AUTOSAR XML (schema 4-1-2)
package /Nexteer/NvMProxy_swc/DataTypes
  impl type NvM_BlockIdType: category=VALUE, base-type=NvM_BlockIdType, range raw 1..32767
  impl type NvM_RequestResultType: category=VALUE, base-type=NvM_RequestResultType, compu {0=NVM_REQ_OK, 1=NVM_REQ_NOT_OK, 2=NVM_REQ_PENDING, 3=NVM_REQ_INTEGRITY_FAILED, 4=NVM_REQ_BLOCK_SKIPPED, 5=NVM_REQ_NV_INVALIDATED, 6=NVM_REQ_CANCELED, 7=NVM_REQ_REDUNDANCY_FAILED, 8=NVM_REQ_RESTORED_FROM_ROM}
package /Nexteer/NvMProxy_swc/DataTypes/BaseTypes
  base type NvM_BlockIdType: category=FIXED_LENGTH, base-type-size=16, base-type-encoding=NONE, native-declaration=uint16
  base type NvM_RequestResultType: category=FIXED_LENGTH, base-type-size=8, base-type-encoding=NONE, native-declaration=uint8
package /Nexteer/NvMProxy_swc/Interfaces
  5 x client server interface, all with is-service=true:
    NvMAdministration
      operation SetBlockProtection: possible-error=NvMAdministration/E_NOT_OK
        arg ProtectionEnabled_Arg: type=boolean, direction=IN
      error E_NOT_OK: error-code=1
    NvMService_AC3_SRBS
      6 x operation, all with possible-error=NvMService_AC3_SRBS/E_NOT_OK:
        EraseBlock
        GetErrorStatus
          arg ErrorStatus_Arg: type=NvM_RequestResultType, direction=OUT
        InvalidateNvBlock
        ReadBlock
          arg DstPtr_Arg: type=dtRef_VOID, direction=IN
        SetRamBlockStatus
          arg RamBlockStatus_Arg: type=boolean, direction=IN
        WriteBlock
          arg SrcPtr_Arg: type=dtRef_const_VOID, direction=IN
      error E_NOT_OK: error-code=1
    NvMService_AC3_SRBS_Defs
      7 x operation, all with possible-error=NvMService_AC3_SRBS_Defs/E_NOT_OK:
        EraseBlock
        GetErrorStatus
          arg ErrorStatus_Arg: type=NvM_RequestResultType, direction=OUT
        InvalidateNvBlock
        ReadBlock
          arg DstPtr_Arg: type=dtRef_VOID, direction=IN
        RestoreBlockDefaults
          arg DstPtr_Arg: type=dtRef_VOID, direction=IN
        SetRamBlockStatus
          arg RamBlockStatus_Arg: type=boolean, direction=IN
        WriteBlock
          arg SrcPtr_Arg: type=dtRef_const_VOID, direction=IN
      error E_NOT_OK: error-code=1
    NvMService_AC3_SRBS_DS
      8 x operation, all with possible-error=NvMService_AC3_SRBS_DS/E_NOT_OK:
        EraseBlock
        GetDataIndex
          arg DataIndex_Arg: type=uint8, direction=OUT
        GetErrorStatus
          arg ErrorStatus_Arg: type=NvM_RequestResultType, direction=OUT
        InvalidateNvBlock
        ReadBlock
          arg DstPtr_Arg: type=dtRef_VOID, direction=IN
        SetDataIndex
          arg DataIndex_Arg: type=uint8, direction=IN
        SetRamBlockStatus
          arg RamBlockStatus_Arg: type=boolean, direction=IN
        WriteBlock
          arg SrcPtr_Arg: type=dtRef_const_VOID, direction=IN
      error E_NOT_OK: error-code=1
    NvMService_AC3_SRBS_DS_Defs
      9 x operation, all with possible-error=NvMService_AC3_SRBS_DS_Defs/E_NOT_OK:
        EraseBlock
        GetDataIndex
          arg DataIndex_Arg: type=uint8, direction=OUT
        GetErrorStatus
          arg ErrorStatus_Arg: type=NvM_RequestResultType, direction=OUT
        InvalidateNvBlock
        ReadBlock
          arg DstPtr_Arg: type=dtRef_VOID, direction=IN
        RestoreBlockDefaults
          arg DstPtr_Arg: type=dtRef_VOID, direction=IN
        SetDataIndex
          arg DataIndex_Arg: type=uint8, direction=IN
        SetRamBlockStatus
          arg RamBlockStatus_Arg: type=boolean, direction=IN
        WriteBlock
          arg SrcPtr_Arg: type=dtRef_const_VOID, direction=IN
      error E_NOT_OK: error-code=1
package /Nexteer/NvMProxy_swc/ComponentTypes
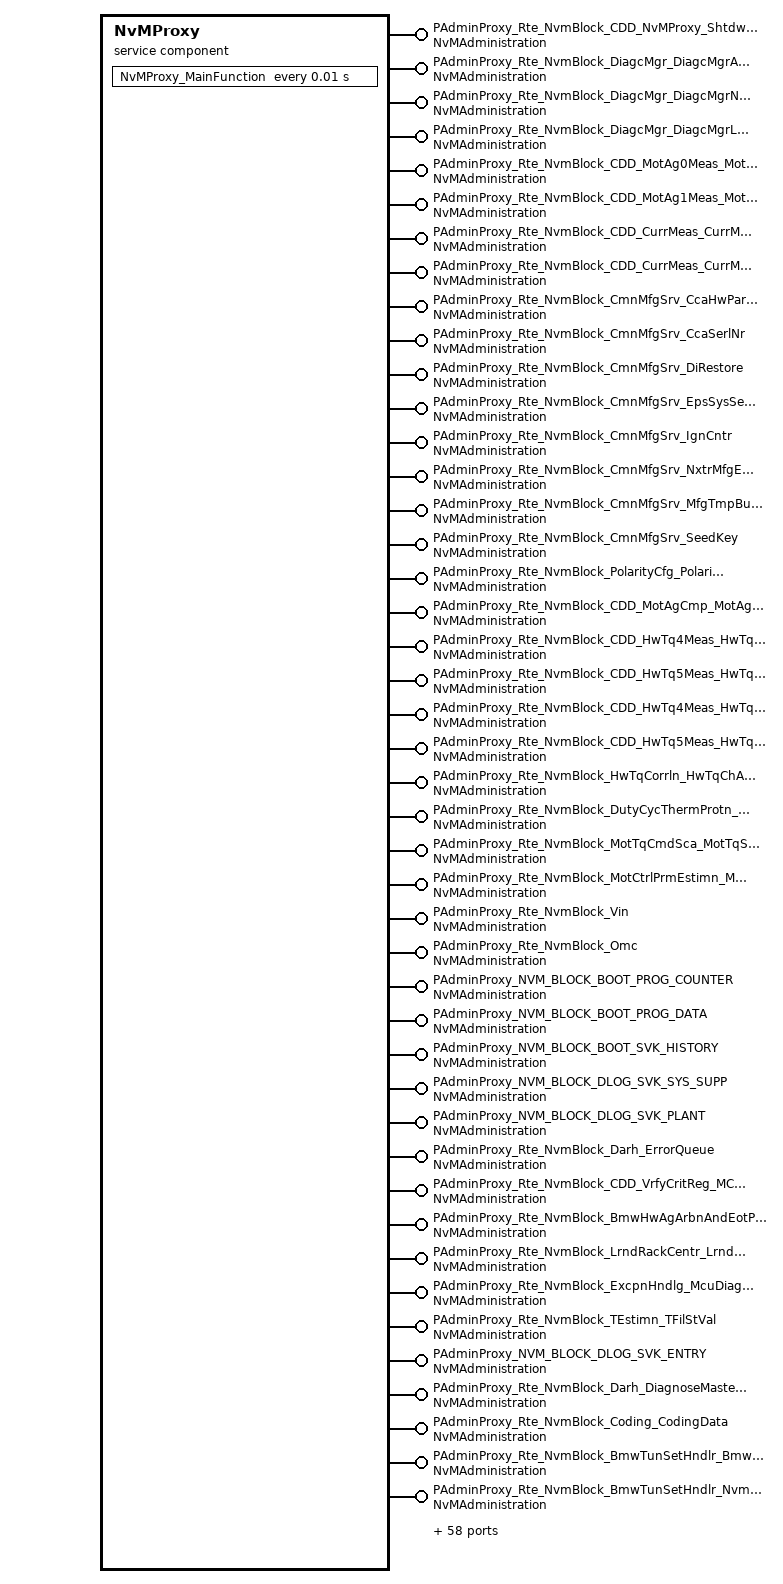
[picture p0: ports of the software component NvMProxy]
  service sw component type NvMProxy
    106 x provide port:
      PAdminProxy_Rte_NvmBlock_CDD_NvMProxy_ShtdwnClsChk: server-com-spec{operation=SetBlockProtection, queue-length=1}, provided-interface=NvMAdministration
      PAdminProxy_Rte_NvmBlock_DiagcMgr_DiagcMgrApplCrc: server-com-spec{operation=SetBlockProtection, queue-length=1}, provided-interface=NvMAdministration
      PAdminProxy_Rte_NvmBlock_DiagcMgr_DiagcMgrNtcFltAry: server-com-spec{operation=SetBlockProtection, queue-length=1}, provided-interface=NvMAdministration
      PAdminProxy_Rte_NvmBlock_DiagcMgr_DiagcMgrLtchCntrAry: server-com-spec{operation=SetBlockProtection, queue-length=1}, provided-interface=NvMAdministration
      PAdminProxy_Rte_NvmBlock_CDD_MotAg0Meas_MotAg0CoeffTbl: server-com-spec{operation=SetBlockProtection, queue-length=1}, provided-interface=NvMAdministration
      PAdminProxy_Rte_NvmBlock_CDD_MotAg1Meas_MotAg1CoeffTbl: server-com-spec{operation=SetBlockProtection, queue-length=1}, provided-interface=NvMAdministration
      PAdminProxy_Rte_NvmBlock_CDD_CurrMeas_CurrMeasEolGainCalSetABC: server-com-spec{operation=SetBlockProtection, queue-length=1}, provided-interface=NvMAdministration
      PAdminProxy_Rte_NvmBlock_CDD_CurrMeas_CurrMeasEolOffsCalSetABC: server-com-spec{operation=SetBlockProtection, queue-length=1}, provided-interface=NvMAdministration
      PAdminProxy_Rte_NvmBlock_CmnMfgSrv_CcaHwPartNr: server-com-spec{operation=SetBlockProtection, queue-length=1}, provided-interface=NvMAdministration
      PAdminProxy_Rte_NvmBlock_CmnMfgSrv_CcaSerlNr: server-com-spec{operation=SetBlockProtection, queue-length=1}, provided-interface=NvMAdministration
      PAdminProxy_Rte_NvmBlock_CmnMfgSrv_DiRestore: server-com-spec{operation=SetBlockProtection, queue-length=1}, provided-interface=NvMAdministration
      PAdminProxy_Rte_NvmBlock_CmnMfgSrv_EpsSysSerlNr: server-com-spec{operation=SetBlockProtection, queue-length=1}, provided-interface=NvMAdministration
      PAdminProxy_Rte_NvmBlock_CmnMfgSrv_IgnCntr: server-com-spec{operation=SetBlockProtection, queue-length=1}, provided-interface=NvMAdministration
      PAdminProxy_Rte_NvmBlock_CmnMfgSrv_NxtrMfgEnaCntr: server-com-spec{operation=SetBlockProtection, queue-length=1}, provided-interface=NvMAdministration
      PAdminProxy_Rte_NvmBlock_CmnMfgSrv_MfgTmpBuf{0..4}: server-com-spec{operation=SetBlockProtection, queue-length=1}, provided-interface=NvMAdministration
      PAdminProxy_Rte_NvmBlock_CmnMfgSrv_SeedKey: server-com-spec{operation=SetBlockProtection, queue-length=1}, provided-interface=NvMAdministration
      PAdminProxy_Rte_NvmBlock_PolarityCfg_PolarityCfgSaved: server-com-spec{operation=SetBlockProtection, queue-length=1}, provided-interface=NvMAdministration
      PAdminProxy_Rte_NvmBlock_CDD_MotAgCmp_MotAgCmpMotAgBackEmf: server-com-spec{operation=SetBlockProtection, queue-length=1}, provided-interface=NvMAdministration
      PAdminProxy_Rte_NvmBlock_CDD_HwTq4Meas_HwTq4Offs_MirrorBlock: server-com-spec{operation=SetBlockProtection, queue-length=1}, provided-interface=NvMAdministration
      PAdminProxy_Rte_NvmBlock_CDD_HwTq5Meas_HwTq5Offs_MirrorBlock: server-com-spec{operation=SetBlockProtection, queue-length=1}, provided-interface=NvMAdministration
      PAdminProxy_Rte_NvmBlock_CDD_HwTq4Meas_HwTq4Sca_MirrorBlock: server-com-spec{operation=SetBlockProtection, queue-length=1}, provided-interface=NvMAdministration
      PAdminProxy_Rte_NvmBlock_CDD_HwTq5Meas_HwTq5Sca_MirrorBlock: server-com-spec{operation=SetBlockProtection, queue-length=1}, provided-interface=NvMAdministration
      PAdminProxy_Rte_NvmBlock_HwTqCorrln_HwTqChACmnModCmpLpFilSt: server-com-spec{operation=SetBlockProtection, queue-length=1}, provided-interface=NvMAdministration
      PAdminProxy_Rte_NvmBlock_DutyCycThermProtn_FilStVal: server-com-spec{operation=SetBlockProtection, queue-length=1}, provided-interface=NvMAdministration
      PAdminProxy_Rte_NvmBlock_MotTqCmdSca_MotTqScaFac: server-com-spec{operation=SetBlockProtection, queue-length=1}, provided-interface=NvMAdministration
      PAdminProxy_Rte_NvmBlock_MotCtrlPrmEstimn_MotPrmNom: server-com-spec{operation=SetBlockProtection, queue-length=1}, provided-interface=NvMAdministration
      PAdminProxy_Rte_NvmBlock_Vin: server-com-spec{operation=SetBlockProtection, queue-length=1}, provided-interface=NvMAdministration
      PAdminProxy_Rte_NvmBlock_Omc: server-com-spec{operation=SetBlockProtection, queue-length=1}, provided-interface=NvMAdministration
      PAdminProxy_NVM_BLOCK_BOOT_PROG_COUNTER: server-com-spec{operation=SetBlockProtection, queue-length=1}, provided-interface=NvMAdministration
      PAdminProxy_NVM_BLOCK_BOOT_PROG_DATA: server-com-spec{operation=SetBlockProtection, queue-length=1}, provided-interface=NvMAdministration
      PAdminProxy_NVM_BLOCK_BOOT_SVK_HISTORY: server-com-spec{operation=SetBlockProtection, queue-length=1}, provided-interface=NvMAdministration
      PAdminProxy_NVM_BLOCK_DLOG_SVK_SYS_SUPP: server-com-spec{operation=SetBlockProtection, queue-length=1}, provided-interface=NvMAdministration
      PAdminProxy_NVM_BLOCK_DLOG_SVK_PLANT: server-com-spec{operation=SetBlockProtection, queue-length=1}, provided-interface=NvMAdministration
      PAdminProxy_Rte_NvmBlock_Darh_ErrorQueue: server-com-spec{operation=SetBlockProtection, queue-length=1}, provided-interface=NvMAdministration
      PAdminProxy_Rte_NvmBlock_CDD_VrfyCritReg_MCalReadVrfyCritRegFltInfo: server-com-spec{operation=SetBlockProtection, queue-length=1}, provided-interface=NvMAdministration
      PAdminProxy_Rte_NvmBlock_BmwHwAgArbnAndEotPosn_BmwVehCentrOffs: server-com-spec{operation=SetBlockProtection, queue-length=1}, provided-interface=NvMAdministration
      PAdminProxy_Rte_NvmBlock_LrndRackCentr_LrndRackCentr: server-com-spec{operation=SetBlockProtection, queue-length=1}, provided-interface=NvMAdministration
      PAdminProxy_Rte_NvmBlock_ExcpnHndlg_McuDiagcData: server-com-spec{operation=SetBlockProtection, queue-length=1}, provided-interface=NvMAdministration
      PAdminProxy_Rte_NvmBlock_TEstimn_TFilStVal: server-com-spec{operation=SetBlockProtection, queue-length=1}, provided-interface=NvMAdministration
      PAdminProxy_NVM_BLOCK_DLOG_SVK_ENTRY: server-com-spec{operation=SetBlockProtection, queue-length=1}, provided-interface=NvMAdministration
      PAdminProxy_Rte_NvmBlock_Darh_DiagnoseMasterEnable: server-com-spec{operation=SetBlockProtection, queue-length=1}, provided-interface=NvMAdministration
      PAdminProxy_Rte_NvmBlock_Coding_CodingData: server-com-spec{operation=SetBlockProtection, queue-length=1}, provided-interface=NvMAdministration
      PAdminProxy_Rte_NvmBlock_BmwTunSetHndlr_BmwDesIninIdx: server-com-spec{operation=SetBlockProtection, queue-length=1}, provided-interface=NvMAdministration
      PAdminProxy_Rte_NvmBlock_BmwTunSetHndlr_NvmBmwDesIninOptSetAIdx: server-com-spec{operation=SetBlockProtection, queue-length=1}, provided-interface=NvMAdministration
      PAdminProxy_Rte_NvmBlock_BmwDiagcSrvHndlg_MilesKmEeprom: server-com-spec{operation=SetBlockProtection, queue-length=1}, provided-interface=NvMAdministration
      PAdminProxy_Rte_NvmBlock_BmwDiagcSrvHndlg_ProgCntr: server-com-spec{operation=SetBlockProtection, queue-length=1}, provided-interface=NvMAdministration
      PAdminProxy_Rte_NvmBlock_BmwDiagcSrvHndlg_ProgCntrMaxVal: server-com-spec{operation=SetBlockProtection, queue-length=1}, provided-interface=NvMAdministration
      PAdminProxy_Rte_NvmBlock_BmwDiagcSrvHndlg_TestStamp: server-com-spec{operation=SetBlockProtection, queue-length=1}, provided-interface=NvMAdministration
      PAdminProxy_Rte_NvmBlock_PullCmpActv_PullCmpLongTerm: server-com-spec{operation=SetBlockProtection, queue-length=1}, provided-interface=NvMAdministration
      PSProxy_Rte_NvmBlock_DiagcMgr_DiagcMgrApplCrc: provided-interface=NvMService_AC3_SRBS_Defs
        provided-com-specs:
          operation=NvMService_AC3_SRBS_Defs/EraseBlock, queue-length=1
          operation=NvMService_AC3_SRBS_Defs/GetErrorStatus, queue-length=1
          operation=NvMService_AC3_SRBS_Defs/InvalidateNvBlock, queue-length=1
          operation=NvMService_AC3_SRBS_Defs/ReadBlock, queue-length=1
          operation=NvMService_AC3_SRBS_Defs/RestoreBlockDefaults, queue-length=1
          operation=NvMService_AC3_SRBS_Defs/SetRamBlockStatus, queue-length=1
          operation=NvMService_AC3_SRBS_Defs/WriteBlock, queue-length=1
      PSProxy_Rte_NvmBlock_CDD_CurrMeas_CurrMeasEolGainCalSetABC: provided-interface=NvMService_AC3_SRBS_Defs
        provided-com-specs:
          operation=NvMService_AC3_SRBS_Defs/EraseBlock, queue-length=1
          operation=NvMService_AC3_SRBS_Defs/GetErrorStatus, queue-length=1
          operation=NvMService_AC3_SRBS_Defs/InvalidateNvBlock, queue-length=1
          operation=NvMService_AC3_SRBS_Defs/ReadBlock, queue-length=1
          operation=NvMService_AC3_SRBS_Defs/RestoreBlockDefaults, queue-length=1
          operation=NvMService_AC3_SRBS_Defs/SetRamBlockStatus, queue-length=1
          operation=NvMService_AC3_SRBS_Defs/WriteBlock, queue-length=1
      PSProxy_Rte_NvmBlock_CDD_CurrMeas_CurrMeasEolOffsCalSetABC: provided-interface=NvMService_AC3_SRBS_Defs
        provided-com-specs:
          operation=NvMService_AC3_SRBS_Defs/EraseBlock, queue-length=1
          operation=NvMService_AC3_SRBS_Defs/GetErrorStatus, queue-length=1
          operation=NvMService_AC3_SRBS_Defs/InvalidateNvBlock, queue-length=1
          operation=NvMService_AC3_SRBS_Defs/ReadBlock, queue-length=1
          operation=NvMService_AC3_SRBS_Defs/RestoreBlockDefaults, queue-length=1
          operation=NvMService_AC3_SRBS_Defs/SetRamBlockStatus, queue-length=1
          operation=NvMService_AC3_SRBS_Defs/WriteBlock, queue-length=1
      PSProxy_Rte_NvmBlock_CmnMfgSrv_IgnCntr: provided-interface=NvMService_AC3_SRBS_Defs
        provided-com-specs:
          operation=NvMService_AC3_SRBS_Defs/EraseBlock, queue-length=1
          operation=NvMService_AC3_SRBS_Defs/GetErrorStatus, queue-length=1
          operation=NvMService_AC3_SRBS_Defs/InvalidateNvBlock, queue-length=1
          operation=NvMService_AC3_SRBS_Defs/ReadBlock, queue-length=1
          operation=NvMService_AC3_SRBS_Defs/RestoreBlockDefaults, queue-length=1
          operation=NvMService_AC3_SRBS_Defs/SetRamBlockStatus, queue-length=1
          operation=NvMService_AC3_SRBS_Defs/WriteBlock, queue-length=1
      PSProxy_Rte_NvmBlock_CmnMfgSrv_NxtrMfgEnaCntr: provided-interface=NvMService_AC3_SRBS_Defs
        provided-com-specs:
          operation=NvMService_AC3_SRBS_Defs/EraseBlock, queue-length=1
          operation=NvMService_AC3_SRBS_Defs/GetErrorStatus, queue-length=1
          operation=NvMService_AC3_SRBS_Defs/InvalidateNvBlock, queue-length=1
          operation=NvMService_AC3_SRBS_Defs/ReadBlock, queue-length=1
          operation=NvMService_AC3_SRBS_Defs/RestoreBlockDefaults, queue-length=1
          operation=NvMService_AC3_SRBS_Defs/SetRamBlockStatus, queue-length=1
          operation=NvMService_AC3_SRBS_Defs/WriteBlock, queue-length=1
      PSProxy_Rte_NvmBlock_CmnMfgSrv_SeedKey: provided-interface=NvMService_AC3_SRBS_Defs
        provided-com-specs:
          operation=NvMService_AC3_SRBS_Defs/EraseBlock, queue-length=1
          operation=NvMService_AC3_SRBS_Defs/GetErrorStatus, queue-length=1
          operation=NvMService_AC3_SRBS_Defs/InvalidateNvBlock, queue-length=1
          operation=NvMService_AC3_SRBS_Defs/ReadBlock, queue-length=1
          operation=NvMService_AC3_SRBS_Defs/RestoreBlockDefaults, queue-length=1
          operation=NvMService_AC3_SRBS_Defs/SetRamBlockStatus, queue-length=1
          operation=NvMService_AC3_SRBS_Defs/WriteBlock, queue-length=1
      PSProxy_Rte_NvmBlock_PolarityCfg_PolarityCfgSaved: provided-interface=NvMService_AC3_SRBS_Defs
        provided-com-specs:
          operation=NvMService_AC3_SRBS_Defs/EraseBlock, queue-length=1
          operation=NvMService_AC3_SRBS_Defs/GetErrorStatus, queue-length=1
          operation=NvMService_AC3_SRBS_Defs/InvalidateNvBlock, queue-length=1
          operation=NvMService_AC3_SRBS_Defs/ReadBlock, queue-length=1
          operation=NvMService_AC3_SRBS_Defs/RestoreBlockDefaults, queue-length=1
          operation=NvMService_AC3_SRBS_Defs/SetRamBlockStatus, queue-length=1
          operation=NvMService_AC3_SRBS_Defs/WriteBlock, queue-length=1
      PSProxy_Rte_NvmBlock_CDD_MotAgCmp_MotAgCmpMotAgBackEmf: provided-interface=NvMService_AC3_SRBS_Defs
        provided-com-specs:
          operation=NvMService_AC3_SRBS_Defs/EraseBlock, queue-length=1
          operation=NvMService_AC3_SRBS_Defs/GetErrorStatus, queue-length=1
          operation=NvMService_AC3_SRBS_Defs/InvalidateNvBlock, queue-length=1
          operation=NvMService_AC3_SRBS_Defs/ReadBlock, queue-length=1
          operation=NvMService_AC3_SRBS_Defs/RestoreBlockDefaults, queue-length=1
          operation=NvMService_AC3_SRBS_Defs/SetRamBlockStatus, queue-length=1
          operation=NvMService_AC3_SRBS_Defs/WriteBlock, queue-length=1
      PSProxy_Rte_NvmBlock_HwTqCorrln_HwTqChACmnModCmpLpFilSt: provided-interface=NvMService_AC3_SRBS_Defs
        provided-com-specs:
          operation=NvMService_AC3_SRBS_Defs/EraseBlock, queue-length=1
          operation=NvMService_AC3_SRBS_Defs/GetErrorStatus, queue-length=1
          operation=NvMService_AC3_SRBS_Defs/InvalidateNvBlock, queue-length=1
          operation=NvMService_AC3_SRBS_Defs/ReadBlock, queue-length=1
          operation=NvMService_AC3_SRBS_Defs/RestoreBlockDefaults, queue-length=1
          operation=NvMService_AC3_SRBS_Defs/SetRamBlockStatus, queue-length=1
          operation=NvMService_AC3_SRBS_Defs/WriteBlock, queue-length=1
      PSProxy_Rte_NvmBlock_Vin: provided-interface=NvMService_AC3_SRBS_Defs
        provided-com-specs:
          operation=NvMService_AC3_SRBS_Defs/EraseBlock, queue-length=1
          operation=NvMService_AC3_SRBS_Defs/GetErrorStatus, queue-length=1
          operation=NvMService_AC3_SRBS_Defs/InvalidateNvBlock, queue-length=1
          operation=NvMService_AC3_SRBS_Defs/ReadBlock, queue-length=1
          operation=NvMService_AC3_SRBS_Defs/RestoreBlockDefaults, queue-length=1
          operation=NvMService_AC3_SRBS_Defs/SetRamBlockStatus, queue-length=1
          operation=NvMService_AC3_SRBS_Defs/WriteBlock, queue-length=1
      PSProxy_Rte_NvmBlock_Omc: provided-interface=NvMService_AC3_SRBS_Defs
        provided-com-specs:
          operation=NvMService_AC3_SRBS_Defs/EraseBlock, queue-length=1
          operation=NvMService_AC3_SRBS_Defs/GetErrorStatus, queue-length=1
          operation=NvMService_AC3_SRBS_Defs/InvalidateNvBlock, queue-length=1
          operation=NvMService_AC3_SRBS_Defs/ReadBlock, queue-length=1
          operation=NvMService_AC3_SRBS_Defs/RestoreBlockDefaults, queue-length=1
          operation=NvMService_AC3_SRBS_Defs/SetRamBlockStatus, queue-length=1
          operation=NvMService_AC3_SRBS_Defs/WriteBlock, queue-length=1
      PSProxy_Rte_NvmBlock_Darh_ErrorQueue: provided-interface=NvMService_AC3_SRBS_Defs
        provided-com-specs:
          operation=NvMService_AC3_SRBS_Defs/EraseBlock, queue-length=1
          operation=NvMService_AC3_SRBS_Defs/GetErrorStatus, queue-length=1
          operation=NvMService_AC3_SRBS_Defs/InvalidateNvBlock, queue-length=1
          operation=NvMService_AC3_SRBS_Defs/ReadBlock, queue-length=1
          operation=NvMService_AC3_SRBS_Defs/RestoreBlockDefaults, queue-length=1
          operation=NvMService_AC3_SRBS_Defs/SetRamBlockStatus, queue-length=1
          operation=NvMService_AC3_SRBS_Defs/WriteBlock, queue-length=1
      PSProxy_Rte_NvmBlock_ExcpnHndlg_McuDiagcData: provided-interface=NvMService_AC3_SRBS_Defs
        provided-com-specs:
          operation=NvMService_AC3_SRBS_Defs/EraseBlock, queue-length=1
          operation=NvMService_AC3_SRBS_Defs/GetErrorStatus, queue-length=1
          operation=NvMService_AC3_SRBS_Defs/InvalidateNvBlock, queue-length=1
          operation=NvMService_AC3_SRBS_Defs/ReadBlock, queue-length=1
          operation=NvMService_AC3_SRBS_Defs/RestoreBlockDefaults, queue-length=1
          operation=NvMService_AC3_SRBS_Defs/SetRamBlockStatus, queue-length=1
          operation=NvMService_AC3_SRBS_Defs/WriteBlock, queue-length=1
      PSProxy_Rte_NvmBlock_Coding_CodingData: provided-interface=NvMService_AC3_SRBS_Defs
        provided-com-specs:
          operation=NvMService_AC3_SRBS_Defs/EraseBlock, queue-length=1
          operation=NvMService_AC3_SRBS_Defs/GetErrorStatus, queue-length=1
          operation=NvMService_AC3_SRBS_Defs/InvalidateNvBlock, queue-length=1
          operation=NvMService_AC3_SRBS_Defs/ReadBlock, queue-length=1
          operation=NvMService_AC3_SRBS_Defs/RestoreBlockDefaults, queue-length=1
          operation=NvMService_AC3_SRBS_Defs/SetRamBlockStatus, queue-length=1
          operation=NvMService_AC3_SRBS_Defs/WriteBlock, queue-length=1
      PSProxy_Rte_NvmBlock_BmwTunSetHndlr_BmwDesIninIdx: provided-interface=NvMService_AC3_SRBS_Defs
        provided-com-specs:
          operation=NvMService_AC3_SRBS_Defs/EraseBlock, queue-length=1
          operation=NvMService_AC3_SRBS_Defs/GetErrorStatus, queue-length=1
          operation=NvMService_AC3_SRBS_Defs/InvalidateNvBlock, queue-length=1
          operation=NvMService_AC3_SRBS_Defs/ReadBlock, queue-length=1
          operation=NvMService_AC3_SRBS_Defs/RestoreBlockDefaults, queue-length=1
          operation=NvMService_AC3_SRBS_Defs/SetRamBlockStatus, queue-length=1
          operation=NvMService_AC3_SRBS_Defs/WriteBlock, queue-length=1
      PSProxy_Rte_NvmBlock_BmwTunSetHndlr_NvmBmwDesIninOptSetAIdx: provided-interface=NvMService_AC3_SRBS_Defs
        provided-com-specs:
          operation=NvMService_AC3_SRBS_Defs/EraseBlock, queue-length=1
          operation=NvMService_AC3_SRBS_Defs/GetErrorStatus, queue-length=1
          operation=NvMService_AC3_SRBS_Defs/InvalidateNvBlock, queue-length=1
          operation=NvMService_AC3_SRBS_Defs/ReadBlock, queue-length=1
          operation=NvMService_AC3_SRBS_Defs/RestoreBlockDefaults, queue-length=1
          operation=NvMService_AC3_SRBS_Defs/SetRamBlockStatus, queue-length=1
          operation=NvMService_AC3_SRBS_Defs/WriteBlock, queue-length=1
      PSProxy_Rte_NvmBlock_BmwDiagcSrvHndlg_ProgCntrMaxVal: provided-interface=NvMService_AC3_SRBS_Defs
        provided-com-specs:
          operation=NvMService_AC3_SRBS_Defs/EraseBlock, queue-length=1
          operation=NvMService_AC3_SRBS_Defs/GetErrorStatus, queue-length=1
          operation=NvMService_AC3_SRBS_Defs/InvalidateNvBlock, queue-length=1
          operation=NvMService_AC3_SRBS_Defs/ReadBlock, queue-length=1
          operation=NvMService_AC3_SRBS_Defs/RestoreBlockDefaults, queue-length=1
          operation=NvMService_AC3_SRBS_Defs/SetRamBlockStatus, queue-length=1
          operation=NvMService_AC3_SRBS_Defs/WriteBlock, queue-length=1
      PSProxy_Rte_NvmBlock_PullCmpActv_PullCmpLongTerm: provided-interface=NvMService_AC3_SRBS_Defs
        provided-com-specs:
          operation=NvMService_AC3_SRBS_Defs/EraseBlock, queue-length=1
          operation=NvMService_AC3_SRBS_Defs/GetErrorStatus, queue-length=1
          operation=NvMService_AC3_SRBS_Defs/InvalidateNvBlock, queue-length=1
          operation=NvMService_AC3_SRBS_Defs/ReadBlock, queue-length=1
          operation=NvMService_AC3_SRBS_Defs/RestoreBlockDefaults, queue-length=1
          operation=NvMService_AC3_SRBS_Defs/SetRamBlockStatus, queue-length=1
          operation=NvMService_AC3_SRBS_Defs/WriteBlock, queue-length=1
      PSProxy_NVM_BLOCK_DLOG_SVK_ENTRY: provided-interface=NvMService_AC3_SRBS_DS
        provided-com-specs:
          operation=NvMService_AC3_SRBS_DS/EraseBlock, queue-length=1
          operation=NvMService_AC3_SRBS_DS/GetDataIndex, queue-length=1
          operation=NvMService_AC3_SRBS_DS/GetErrorStatus, queue-length=1
          operation=NvMService_AC3_SRBS_DS/InvalidateNvBlock, queue-length=1
          operation=NvMService_AC3_SRBS_DS/ReadBlock, queue-length=1
          operation=NvMService_AC3_SRBS_DS/SetDataIndex, queue-length=1
          operation=NvMService_AC3_SRBS_DS/SetRamBlockStatus, queue-length=1
          operation=NvMService_AC3_SRBS_DS/WriteBlock, queue-length=1
      PSProxy_Rte_NvmBlock_CDD_NvMProxy_ShtdwnClsChk: provided-interface=NvMService_AC3_SRBS
        provided-com-specs:
          operation=NvMService_AC3_SRBS/EraseBlock, queue-length=1
          operation=NvMService_AC3_SRBS/GetErrorStatus, queue-length=1
          operation=NvMService_AC3_SRBS/InvalidateNvBlock, queue-length=1
          operation=NvMService_AC3_SRBS/ReadBlock, queue-length=1
          operation=NvMService_AC3_SRBS/SetRamBlockStatus, queue-length=1
          operation=NvMService_AC3_SRBS/WriteBlock, queue-length=1
      PSProxy_Rte_NvmBlock_DiagcMgr_DiagcMgrNtcFltAry: provided-interface=NvMService_AC3_SRBS
        provided-com-specs:
          operation=NvMService_AC3_SRBS/EraseBlock, queue-length=1
          operation=NvMService_AC3_SRBS/GetErrorStatus, queue-length=1
          operation=NvMService_AC3_SRBS/InvalidateNvBlock, queue-length=1
          operation=NvMService_AC3_SRBS/ReadBlock, queue-length=1
          operation=NvMService_AC3_SRBS/SetRamBlockStatus, queue-length=1
          operation=NvMService_AC3_SRBS/WriteBlock, queue-length=1
      PSProxy_Rte_NvmBlock_DiagcMgr_DiagcMgrLtchCntrAry: provided-interface=NvMService_AC3_SRBS
        provided-com-specs:
          operation=NvMService_AC3_SRBS/EraseBlock, queue-length=1
          operation=NvMService_AC3_SRBS/GetErrorStatus, queue-length=1
          operation=NvMService_AC3_SRBS/InvalidateNvBlock, queue-length=1
          operation=NvMService_AC3_SRBS/ReadBlock, queue-length=1
          operation=NvMService_AC3_SRBS/SetRamBlockStatus, queue-length=1
          operation=NvMService_AC3_SRBS/WriteBlock, queue-length=1
      PSProxy_Rte_NvmBlock_CDD_MotAg0Meas_MotAg0CoeffTbl: provided-interface=NvMService_AC3_SRBS
        provided-com-specs:
          operation=NvMService_AC3_SRBS/EraseBlock, queue-length=1
          operation=NvMService_AC3_SRBS/GetErrorStatus, queue-length=1
          operation=NvMService_AC3_SRBS/InvalidateNvBlock, queue-length=1
          operation=NvMService_AC3_SRBS/ReadBlock, queue-length=1
          operation=NvMService_AC3_SRBS/SetRamBlockStatus, queue-length=1
          operation=NvMService_AC3_SRBS/WriteBlock, queue-length=1
      PSProxy_Rte_NvmBlock_CDD_MotAg1Meas_MotAg1CoeffTbl: provided-interface=NvMService_AC3_SRBS
        provided-com-specs:
          operation=NvMService_AC3_SRBS/EraseBlock, queue-length=1
          operation=NvMService_AC3_SRBS/GetErrorStatus, queue-length=1
          operation=NvMService_AC3_SRBS/InvalidateNvBlock, queue-length=1
          operation=NvMService_AC3_SRBS/ReadBlock, queue-length=1
          operation=NvMService_AC3_SRBS/SetRamBlockStatus, queue-length=1
          operation=NvMService_AC3_SRBS/WriteBlock, queue-length=1
      PSProxy_Rte_NvmBlock_CmnMfgSrv_CcaHwPartNr: provided-interface=NvMService_AC3_SRBS
        provided-com-specs:
          operation=NvMService_AC3_SRBS/EraseBlock, queue-length=1
          operation=NvMService_AC3_SRBS/GetErrorStatus, queue-length=1
          operation=NvMService_AC3_SRBS/InvalidateNvBlock, queue-length=1
          operation=NvMService_AC3_SRBS/ReadBlock, queue-length=1
          operation=NvMService_AC3_SRBS/SetRamBlockStatus, queue-length=1
          operation=NvMService_AC3_SRBS/WriteBlock, queue-length=1
      PSProxy_Rte_NvmBlock_CmnMfgSrv_CcaSerlNr: provided-interface=NvMService_AC3_SRBS
        provided-com-specs:
          operation=NvMService_AC3_SRBS/EraseBlock, queue-length=1
          operation=NvMService_AC3_SRBS/GetErrorStatus, queue-length=1
          operation=NvMService_AC3_SRBS/InvalidateNvBlock, queue-length=1
          operation=NvMService_AC3_SRBS/ReadBlock, queue-length=1
          operation=NvMService_AC3_SRBS/SetRamBlockStatus, queue-length=1
          operation=NvMService_AC3_SRBS/WriteBlock, queue-length=1
      PSProxy_Rte_NvmBlock_CmnMfgSrv_DiRestore: provided-interface=NvMService_AC3_SRBS
        provided-com-specs:
          operation=NvMService_AC3_SRBS/EraseBlock, queue-length=1
          operation=NvMService_AC3_SRBS/GetErrorStatus, queue-length=1
          operation=NvMService_AC3_SRBS/InvalidateNvBlock, queue-length=1
          operation=NvMService_AC3_SRBS/ReadBlock, queue-length=1
          operation=NvMService_AC3_SRBS/SetRamBlockStatus, queue-length=1
          operation=NvMService_AC3_SRBS/WriteBlock, queue-length=1
      PSProxy_Rte_NvmBlock_CmnMfgSrv_EpsSysSerlNr: provided-interface=NvMService_AC3_SRBS
        provided-com-specs:
          operation=NvMService_AC3_SRBS/EraseBlock, queue-length=1
          operation=NvMService_AC3_SRBS/GetErrorStatus, queue-length=1
          operation=NvMService_AC3_SRBS/InvalidateNvBlock, queue-length=1
          operation=NvMService_AC3_SRBS/ReadBlock, queue-length=1
          operation=NvMService_AC3_SRBS/SetRamBlockStatus, queue-length=1
          operation=NvMService_AC3_SRBS/WriteBlock, queue-length=1
      PSProxy_Rte_NvmBlock_CmnMfgSrv_MfgTmpBuf0: provided-interface=NvMService_AC3_SRBS
        provided-com-specs:
          operation=NvMService_AC3_SRBS/EraseBlock, queue-length=1
          operation=NvMService_AC3_SRBS/GetErrorStatus, queue-length=1
          operation=NvMService_AC3_SRBS/InvalidateNvBlock, queue-length=1
          operation=NvMService_AC3_SRBS/ReadBlock, queue-length=1
          operation=NvMService_AC3_SRBS/SetRamBlockStatus, queue-length=1
          operation=NvMService_AC3_SRBS/WriteBlock, queue-length=1
      PSProxy_Rte_NvmBlock_CmnMfgSrv_MfgTmpBuf1: provided-interface=NvMService_AC3_SRBS
        provided-com-specs:
          operation=NvMService_AC3_SRBS/EraseBlock, queue-length=1
          operation=NvMService_AC3_SRBS/GetErrorStatus, queue-length=1
          operation=NvMService_AC3_SRBS/InvalidateNvBlock, queue-length=1
          operation=NvMService_AC3_SRBS/ReadBlock, queue-length=1
          operation=NvMService_AC3_SRBS/SetRamBlockStatus, queue-length=1
          operation=NvMService_AC3_SRBS/WriteBlock, queue-length=1
      PSProxy_Rte_NvmBlock_CmnMfgSrv_MfgTmpBuf2: provided-interface=NvMService_AC3_SRBS
        provided-com-specs:
          operation=NvMService_AC3_SRBS/EraseBlock, queue-length=1
          operation=NvMService_AC3_SRBS/GetErrorStatus, queue-length=1
          operation=NvMService_AC3_SRBS/InvalidateNvBlock, queue-length=1
          operation=NvMService_AC3_SRBS/ReadBlock, queue-length=1
          operation=NvMService_AC3_SRBS/SetRamBlockStatus, queue-length=1
          operation=NvMService_AC3_SRBS/WriteBlock, queue-length=1
      PSProxy_Rte_NvmBlock_CmnMfgSrv_MfgTmpBuf3: provided-interface=NvMService_AC3_SRBS
        provided-com-specs:
          operation=NvMService_AC3_SRBS/EraseBlock, queue-length=1
          operation=NvMService_AC3_SRBS/GetErrorStatus, queue-length=1
          operation=NvMService_AC3_SRBS/InvalidateNvBlock, queue-length=1
          operation=NvMService_AC3_SRBS/ReadBlock, queue-length=1
          operation=NvMService_AC3_SRBS/SetRamBlockStatus, queue-length=1
          operation=NvMService_AC3_SRBS/WriteBlock, queue-length=1
      PSProxy_Rte_NvmBlock_CmnMfgSrv_MfgTmpBuf4: provided-interface=NvMService_AC3_SRBS
        provided-com-specs:
          operation=NvMService_AC3_SRBS/EraseBlock, queue-length=1
          operation=NvMService_AC3_SRBS/GetErrorStatus, queue-length=1
          operation=NvMService_AC3_SRBS/InvalidateNvBlock, queue-length=1
          operation=NvMService_AC3_SRBS/ReadBlock, queue-length=1
          operation=NvMService_AC3_SRBS/SetRamBlockStatus, queue-length=1
          operation=NvMService_AC3_SRBS/WriteBlock, queue-length=1
      PSProxy_Rte_NvmBlock_CDD_HwTq4Meas_HwTq4Offs_MirrorBlock: provided-interface=NvMService_AC3_SRBS
        provided-com-specs:
          operation=NvMService_AC3_SRBS/EraseBlock, queue-length=1
          operation=NvMService_AC3_SRBS/GetErrorStatus, queue-length=1
          operation=NvMService_AC3_SRBS/InvalidateNvBlock, queue-length=1
          operation=NvMService_AC3_SRBS/ReadBlock, queue-length=1
          operation=NvMService_AC3_SRBS/SetRamBlockStatus, queue-length=1
          operation=NvMService_AC3_SRBS/WriteBlock, queue-length=1
      PSProxy_Rte_NvmBlock_CDD_HwTq5Meas_HwTq5Offs_MirrorBlock: provided-interface=NvMService_AC3_SRBS
        provided-com-specs:
          operation=NvMService_AC3_SRBS/EraseBlock, queue-length=1
          operation=NvMService_AC3_SRBS/GetErrorStatus, queue-length=1
          operation=NvMService_AC3_SRBS/InvalidateNvBlock, queue-length=1
          operation=NvMService_AC3_SRBS/ReadBlock, queue-length=1
          operation=NvMService_AC3_SRBS/SetRamBlockStatus, queue-length=1
          operation=NvMService_AC3_SRBS/WriteBlock, queue-length=1
      PSProxy_Rte_NvmBlock_CDD_HwTq4Meas_HwTq4Sca_MirrorBlock: provided-interface=NvMService_AC3_SRBS
        provided-com-specs:
          operation=NvMService_AC3_SRBS/EraseBlock, queue-length=1
          operation=NvMService_AC3_SRBS/GetErrorStatus, queue-length=1
          operation=NvMService_AC3_SRBS/InvalidateNvBlock, queue-length=1
          operation=NvMService_AC3_SRBS/ReadBlock, queue-length=1
          operation=NvMService_AC3_SRBS/SetRamBlockStatus, queue-length=1
          operation=NvMService_AC3_SRBS/WriteBlock, queue-length=1
      PSProxy_Rte_NvmBlock_CDD_HwTq5Meas_HwTq5Sca_MirrorBlock: provided-interface=NvMService_AC3_SRBS
        provided-com-specs:
          operation=NvMService_AC3_SRBS/EraseBlock, queue-length=1
          operation=NvMService_AC3_SRBS/GetErrorStatus, queue-length=1
          operation=NvMService_AC3_SRBS/InvalidateNvBlock, queue-length=1
          operation=NvMService_AC3_SRBS/ReadBlock, queue-length=1
          operation=NvMService_AC3_SRBS/SetRamBlockStatus, queue-length=1
          operation=NvMService_AC3_SRBS/WriteBlock, queue-length=1
      PSProxy_Rte_NvmBlock_DutyCycThermProtn_FilStVal: provided-interface=NvMService_AC3_SRBS
        provided-com-specs:
          operation=NvMService_AC3_SRBS/EraseBlock, queue-length=1
          operation=NvMService_AC3_SRBS/GetErrorStatus, queue-length=1
          operation=NvMService_AC3_SRBS/InvalidateNvBlock, queue-length=1
          operation=NvMService_AC3_SRBS/ReadBlock, queue-length=1
          operation=NvMService_AC3_SRBS/SetRamBlockStatus, queue-length=1
          operation=NvMService_AC3_SRBS/WriteBlock, queue-length=1
      PSProxy_Rte_NvmBlock_MotTqCmdSca_MotTqScaFac: provided-interface=NvMService_AC3_SRBS
        provided-com-specs:
          operation=NvMService_AC3_SRBS/EraseBlock, queue-length=1
          operation=NvMService_AC3_SRBS/GetErrorStatus, queue-length=1
          operation=NvMService_AC3_SRBS/InvalidateNvBlock, queue-length=1
          operation=NvMService_AC3_SRBS/ReadBlock, queue-length=1
          operation=NvMService_AC3_SRBS/SetRamBlockStatus, queue-length=1
          operation=NvMService_AC3_SRBS/WriteBlock, queue-length=1
      PSProxy_Rte_NvmBlock_MotCtrlPrmEstimn_MotPrmNom: provided-interface=NvMService_AC3_SRBS
        provided-com-specs:
          operation=NvMService_AC3_SRBS/EraseBlock, queue-length=1
          operation=NvMService_AC3_SRBS/GetErrorStatus, queue-length=1
          operation=NvMService_AC3_SRBS/InvalidateNvBlock, queue-length=1
          operation=NvMService_AC3_SRBS/ReadBlock, queue-length=1
          operation=NvMService_AC3_SRBS/SetRamBlockStatus, queue-length=1
          operation=NvMService_AC3_SRBS/WriteBlock, queue-length=1
      PSProxy_NVM_BLOCK_BOOT_PROG_COUNTER: provided-interface=NvMService_AC3_SRBS
        provided-com-specs:
          operation=NvMService_AC3_SRBS/EraseBlock, queue-length=1
          operation=NvMService_AC3_SRBS/GetErrorStatus, queue-length=1
          operation=NvMService_AC3_SRBS/InvalidateNvBlock, queue-length=1
          operation=NvMService_AC3_SRBS/ReadBlock, queue-length=1
          operation=NvMService_AC3_SRBS/SetRamBlockStatus, queue-length=1
          operation=NvMService_AC3_SRBS/WriteBlock, queue-length=1
      PSProxy_NVM_BLOCK_BOOT_PROG_DATA: provided-interface=NvMService_AC3_SRBS
        provided-com-specs:
          operation=NvMService_AC3_SRBS/EraseBlock, queue-length=1
          operation=NvMService_AC3_SRBS/GetErrorStatus, queue-length=1
          operation=NvMService_AC3_SRBS/InvalidateNvBlock, queue-length=1
          operation=NvMService_AC3_SRBS/ReadBlock, queue-length=1
          operation=NvMService_AC3_SRBS/SetRamBlockStatus, queue-length=1
          operation=NvMService_AC3_SRBS/WriteBlock, queue-length=1
      PSProxy_NVM_BLOCK_BOOT_SVK_HISTORY: provided-interface=NvMService_AC3_SRBS
        provided-com-specs:
          operation=NvMService_AC3_SRBS/EraseBlock, queue-length=1
          operation=NvMService_AC3_SRBS/GetErrorStatus, queue-length=1
          operation=NvMService_AC3_SRBS/InvalidateNvBlock, queue-length=1
          operation=NvMService_AC3_SRBS/ReadBlock, queue-length=1
          operation=NvMService_AC3_SRBS/SetRamBlockStatus, queue-length=1
          operation=NvMService_AC3_SRBS/WriteBlock, queue-length=1
      PSProxy_NVM_BLOCK_DLOG_SVK_SYS_SUPP: provided-interface=NvMService_AC3_SRBS
        provided-com-specs:
          operation=NvMService_AC3_SRBS/EraseBlock, queue-length=1
          operation=NvMService_AC3_SRBS/GetErrorStatus, queue-length=1
          operation=NvMService_AC3_SRBS/InvalidateNvBlock, queue-length=1
          operation=NvMService_AC3_SRBS/ReadBlock, queue-length=1
          operation=NvMService_AC3_SRBS/SetRamBlockStatus, queue-length=1
          operation=NvMService_AC3_SRBS/WriteBlock, queue-length=1
      PSProxy_NVM_BLOCK_DLOG_SVK_PLANT: provided-interface=NvMService_AC3_SRBS
        provided-com-specs:
          operation=NvMService_AC3_SRBS/EraseBlock, queue-length=1
          operation=NvMService_AC3_SRBS/GetErrorStatus, queue-length=1
          operation=NvMService_AC3_SRBS/InvalidateNvBlock, queue-length=1
          operation=NvMService_AC3_SRBS/ReadBlock, queue-length=1
          operation=NvMService_AC3_SRBS/SetRamBlockStatus, queue-length=1
          operation=NvMService_AC3_SRBS/WriteBlock, queue-length=1
      PSProxy_Rte_NvmBlock_CDD_VrfyCritReg_MCalReadVrfyCritRegFltInfo: provided-interface=NvMService_AC3_SRBS
        provided-com-specs:
          operation=NvMService_AC3_SRBS/EraseBlock, queue-length=1
          operation=NvMService_AC3_SRBS/GetErrorStatus, queue-length=1
          operation=NvMService_AC3_SRBS/InvalidateNvBlock, queue-length=1
          operation=NvMService_AC3_SRBS/ReadBlock, queue-length=1
          operation=NvMService_AC3_SRBS/SetRamBlockStatus, queue-length=1
          operation=NvMService_AC3_SRBS/WriteBlock, queue-length=1
      PSProxy_Rte_NvmBlock_BmwHwAgArbnAndEotPosn_BmwVehCentrOffs: provided-interface=NvMService_AC3_SRBS
        provided-com-specs:
          operation=NvMService_AC3_SRBS/EraseBlock, queue-length=1
          operation=NvMService_AC3_SRBS/GetErrorStatus, queue-length=1
          operation=NvMService_AC3_SRBS/InvalidateNvBlock, queue-length=1
          operation=NvMService_AC3_SRBS/ReadBlock, queue-length=1
          operation=NvMService_AC3_SRBS/SetRamBlockStatus, queue-length=1
          operation=NvMService_AC3_SRBS/WriteBlock, queue-length=1
      PSProxy_Rte_NvmBlock_LrndRackCentr_LrndRackCentr: provided-interface=NvMService_AC3_SRBS
        provided-com-specs:
          operation=NvMService_AC3_SRBS/EraseBlock, queue-length=1
          operation=NvMService_AC3_SRBS/GetErrorStatus, queue-length=1
          operation=NvMService_AC3_SRBS/InvalidateNvBlock, queue-length=1
          operation=NvMService_AC3_SRBS/ReadBlock, queue-length=1
          operation=NvMService_AC3_SRBS/SetRamBlockStatus, queue-length=1
          operation=NvMService_AC3_SRBS/WriteBlock, queue-length=1
      PSProxy_Rte_NvmBlock_TEstimn_TFilStVal: provided-interface=NvMService_AC3_SRBS
        provided-com-specs:
          operation=NvMService_AC3_SRBS/EraseBlock, queue-length=1
          operation=NvMService_AC3_SRBS/GetErrorStatus, queue-length=1
          operation=NvMService_AC3_SRBS/InvalidateNvBlock, queue-length=1
          operation=NvMService_AC3_SRBS/ReadBlock, queue-length=1
          operation=NvMService_AC3_SRBS/SetRamBlockStatus, queue-length=1
          operation=NvMService_AC3_SRBS/WriteBlock, queue-length=1
      PSProxy_Rte_NvmBlock_Darh_DiagnoseMasterEnable: provided-interface=NvMService_AC3_SRBS
        provided-com-specs:
          operation=NvMService_AC3_SRBS/EraseBlock, queue-length=1
          operation=NvMService_AC3_SRBS/GetErrorStatus, queue-length=1
          operation=NvMService_AC3_SRBS/InvalidateNvBlock, queue-length=1
          operation=NvMService_AC3_SRBS/ReadBlock, queue-length=1
          operation=NvMService_AC3_SRBS/SetRamBlockStatus, queue-length=1
          operation=NvMService_AC3_SRBS/WriteBlock, queue-length=1
      PSProxy_Rte_NvmBlock_BmwDiagcSrvHndlg_MilesKmEeprom: provided-interface=NvMService_AC3_SRBS
        provided-com-specs:
          operation=NvMService_AC3_SRBS/EraseBlock, queue-length=1
          operation=NvMService_AC3_SRBS/GetErrorStatus, queue-length=1
          operation=NvMService_AC3_SRBS/InvalidateNvBlock, queue-length=1
          operation=NvMService_AC3_SRBS/ReadBlock, queue-length=1
          operation=NvMService_AC3_SRBS/SetRamBlockStatus, queue-length=1
          operation=NvMService_AC3_SRBS/WriteBlock, queue-length=1
      PSProxy_Rte_NvmBlock_BmwDiagcSrvHndlg_ProgCntr: provided-interface=NvMService_AC3_SRBS
        provided-com-specs:
          operation=NvMService_AC3_SRBS/EraseBlock, queue-length=1
          operation=NvMService_AC3_SRBS/GetErrorStatus, queue-length=1
          operation=NvMService_AC3_SRBS/InvalidateNvBlock, queue-length=1
          operation=NvMService_AC3_SRBS/ReadBlock, queue-length=1
          operation=NvMService_AC3_SRBS/SetRamBlockStatus, queue-length=1
          operation=NvMService_AC3_SRBS/WriteBlock, queue-length=1
      PSProxy_Rte_NvmBlock_BmwDiagcSrvHndlg_TestStamp: provided-interface=NvMService_AC3_SRBS
        provided-com-specs:
          operation=NvMService_AC3_SRBS/EraseBlock, queue-length=1
          operation=NvMService_AC3_SRBS/GetErrorStatus, queue-length=1
          operation=NvMService_AC3_SRBS/InvalidateNvBlock, queue-length=1
          operation=NvMService_AC3_SRBS/ReadBlock, queue-length=1
          operation=NvMService_AC3_SRBS/SetRamBlockStatus, queue-length=1
          operation=NvMService_AC3_SRBS/WriteBlock, queue-length=1
    behavior NvMProxyInternalBehavior
      timing event Timer_NvMProxy_MainFunction: start-on-event=NvMProxy_MainFunction, period=0.01
      391 x operation invoked event:
        OIT_EraseBlock_PSProxy_Rte_NvmBlock_DiagcMgr_DiagcMgrApplCrc_EraseBlock: start-on-event=EraseBlock, operation=PSProxy_Rte_NvmBlock_DiagcMgr_DiagcMgrApplCrc.EraseBlock
        OIT_GetErrorStatus_PSProxy_Rte_NvmBlock_DiagcMgr_DiagcMgrApplCrc_GetErrorStatus: start-on-event=GetErrorStatus, operation=PSProxy_Rte_NvmBlock_DiagcMgr_DiagcMgrApplCrc.GetErrorStatus
        OIT_InvalidateNvBlock_PSProxy_Rte_NvmBlock_DiagcMgr_DiagcMgrApplCrc_InvalidateNvBlock: start-on-event=InvalidateNvBlock, operation=PSProxy_Rte_NvmBlock_DiagcMgr_DiagcMgrApplCrc.InvalidateNvBlock
        OIT_ReadBlock_PSProxy_Rte_NvmBlock_DiagcMgr_DiagcMgrApplCrc_ReadBlock: start-on-event=ReadBlock, operation=PSProxy_Rte_NvmBlock_DiagcMgr_DiagcMgrApplCrc.ReadBlock
        OIT_RestoreBlockDefaults_PSProxy_Rte_NvmBlock_DiagcMgr_DiagcMgrApplCrc_RestoreBlockDefaults: start-on-event=RestoreBlockDefaults, operation=PSProxy_Rte_NvmBlock_DiagcMgr_DiagcMgrApplCrc.RestoreBlockDefaults
        OIT_SetRamBlockStatus_PSProxy_Rte_NvmBlock_DiagcMgr_DiagcMgrApplCrc_SetRamBlockStatus: start-on-event=SetRamBlockStatus, operation=PSProxy_Rte_NvmBlock_DiagcMgr_DiagcMgrApplCrc.SetRamBlockStatus
        OIT_WriteBlock_PSProxy_Rte_NvmBlock_DiagcMgr_DiagcMgrApplCrc_WriteBlock: start-on-event=WriteBlock, operation=PSProxy_Rte_NvmBlock_DiagcMgr_DiagcMgrApplCrc.WriteBlock
        OIT_EraseBlock_PSProxy_Rte_NvmBlock_CDD_CurrMeas_CurrMeasEolGainCalSetABC_EraseBlock: start-on-event=EraseBlock, operation=PSProxy_Rte_NvmBlock_CDD_CurrMeas_CurrMeasEolGainCalSetABC.EraseBlock
        OIT_GetErrorStatus_PSProxy_Rte_NvmBlock_CDD_CurrMeas_CurrMeasEolGainCalSetABC_GetErrorStatus: start-on-event=GetErrorStatus, operation=PSProxy_Rte_NvmBlock_CDD_CurrMeas_CurrMeasEolGainCalSetABC.GetErrorStatus
        OIT_InvalidateNvBlock_PSProxy_Rte_NvmBlock_CDD_CurrMeas_CurrMeasEolGainCalSetABC_InvalidateNvBlock: start-on-event=InvalidateNvBlock, operation=PSProxy_Rte_NvmBlock_CDD_CurrMeas_CurrMeasEolGainCalSetABC.InvalidateNvBlock
        OIT_ReadBlock_PSProxy_Rte_NvmBlock_CDD_CurrMeas_CurrMeasEolGainCalSetABC_ReadBlock: start-on-event=ReadBlock, operation=PSProxy_Rte_NvmBlock_CDD_CurrMeas_CurrMeasEolGainCalSetABC.ReadBlock
        OIT_RestoreBlockDefaults_PSProxy_Rte_NvmBlock_CDD_CurrMeas_CurrMeasEolGainCalSetABC_RestoreBlockDefaults: start-on-event=RestoreBlockDefaults, operation=PSProxy_Rte_NvmBlock_CDD_CurrMeas_CurrMeasEolGainCalSetABC.RestoreBlockDefaults
        OIT_SetRamBlockStatus_PSProxy_Rte_NvmBlock_CDD_CurrMeas_CurrMeasEolGainCalSetABC_SetRamBlockStatus: start-on-event=SetRamBlockStatus, operation=PSProxy_Rte_NvmBlock_CDD_CurrMeas_CurrMeasEolGainCalSetABC.SetRamBlockStatus
        OIT_WriteBlock_PSProxy_Rte_NvmBlock_CDD_CurrMeas_CurrMeasEolGainCalSetABC_WriteBlock: start-on-event=WriteBlock, operation=PSProxy_Rte_NvmBlock_CDD_CurrMeas_CurrMeasEolGainCalSetABC.WriteBlock
        OIT_EraseBlock_PSProxy_Rte_NvmBlock_CDD_CurrMeas_CurrMeasEolOffsCalSetABC_EraseBlock: start-on-event=EraseBlock, operation=PSProxy_Rte_NvmBlock_CDD_CurrMeas_CurrMeasEolOffsCalSetABC.EraseBlock
        OIT_GetErrorStatus_PSProxy_Rte_NvmBlock_CDD_CurrMeas_CurrMeasEolOffsCalSetABC_GetErrorStatus: start-on-event=GetErrorStatus, operation=PSProxy_Rte_NvmBlock_CDD_CurrMeas_CurrMeasEolOffsCalSetABC.GetErrorStatus
        OIT_InvalidateNvBlock_PSProxy_Rte_NvmBlock_CDD_CurrMeas_CurrMeasEolOffsCalSetABC_InvalidateNvBlock: start-on-event=InvalidateNvBlock, operation=PSProxy_Rte_NvmBlock_CDD_CurrMeas_CurrMeasEolOffsCalSetABC.InvalidateNvBlock
        OIT_ReadBlock_PSProxy_Rte_NvmBlock_CDD_CurrMeas_CurrMeasEolOffsCalSetABC_ReadBlock: start-on-event=ReadBlock, operation=PSProxy_Rte_NvmBlock_CDD_CurrMeas_CurrMeasEolOffsCalSetABC.ReadBlock
        OIT_RestoreBlockDefaults_PSProxy_Rte_NvmBlock_CDD_CurrMeas_CurrMeasEolOffsCalSetABC_RestoreBlockDefaults: start-on-event=RestoreBlockDefaults, operation=PSProxy_Rte_NvmBlock_CDD_CurrMeas_CurrMeasEolOffsCalSetABC.RestoreBlockDefaults
        OIT_SetRamBlockStatus_PSProxy_Rte_NvmBlock_CDD_CurrMeas_CurrMeasEolOffsCalSetABC_SetRamBlockStatus: start-on-event=SetRamBlockStatus, operation=PSProxy_Rte_NvmBlock_CDD_CurrMeas_CurrMeasEolOffsCalSetABC.SetRamBlockStatus
        OIT_WriteBlock_PSProxy_Rte_NvmBlock_CDD_CurrMeas_CurrMeasEolOffsCalSetABC_WriteBlock: start-on-event=WriteBlock, operation=PSProxy_Rte_NvmBlock_CDD_CurrMeas_CurrMeasEolOffsCalSetABC.WriteBlock
        OIT_EraseBlock_PSProxy_Rte_NvmBlock_CmnMfgSrv_IgnCntr_EraseBlock: start-on-event=EraseBlock, operation=PSProxy_Rte_NvmBlock_CmnMfgSrv_IgnCntr.EraseBlock
        OIT_GetErrorStatus_PSProxy_Rte_NvmBlock_CmnMfgSrv_IgnCntr_GetErrorStatus: start-on-event=GetErrorStatus, operation=PSProxy_Rte_NvmBlock_CmnMfgSrv_IgnCntr.GetErrorStatus
        OIT_InvalidateNvBlock_PSProxy_Rte_NvmBlock_CmnMfgSrv_IgnCntr_InvalidateNvBlock: start-on-event=InvalidateNvBlock, operation=PSProxy_Rte_NvmBlock_CmnMfgSrv_IgnCntr.InvalidateNvBlock
        OIT_ReadBlock_PSProxy_Rte_NvmBlock_CmnMfgSrv_IgnCntr_ReadBlock: start-on-event=ReadBlock, operation=PSProxy_Rte_NvmBlock_CmnMfgSrv_IgnCntr.ReadBlock
        OIT_RestoreBlockDefaults_PSProxy_Rte_NvmBlock_CmnMfgSrv_IgnCntr_RestoreBlockDefaults: start-on-event=RestoreBlockDefaults, operation=PSProxy_Rte_NvmBlock_CmnMfgSrv_IgnCntr.RestoreBlockDefaults
        OIT_SetRamBlockStatus_PSProxy_Rte_NvmBlock_CmnMfgSrv_IgnCntr_SetRamBlockStatus: start-on-event=SetRamBlockStatus, operation=PSProxy_Rte_NvmBlock_CmnMfgSrv_IgnCntr.SetRamBlockStatus
        OIT_WriteBlock_PSProxy_Rte_NvmBlock_CmnMfgSrv_IgnCntr_WriteBlock: start-on-event=WriteBlock, operation=PSProxy_Rte_NvmBlock_CmnMfgSrv_IgnCntr.WriteBlock
        OIT_EraseBlock_PSProxy_Rte_NvmBlock_CmnMfgSrv_NxtrMfgEnaCntr_EraseBlock: start-on-event=EraseBlock, operation=PSProxy_Rte_NvmBlock_CmnMfgSrv_NxtrMfgEnaCntr.EraseBlock
        OIT_GetErrorStatus_PSProxy_Rte_NvmBlock_CmnMfgSrv_NxtrMfgEnaCntr_GetErrorStatus: start-on-event=GetErrorStatus, operation=PSProxy_Rte_NvmBlock_CmnMfgSrv_NxtrMfgEnaCntr.GetErrorStatus
        OIT_InvalidateNvBlock_PSProxy_Rte_NvmBlock_CmnMfgSrv_NxtrMfgEnaCntr_InvalidateNvBlock: start-on-event=InvalidateNvBlock, operation=PSProxy_Rte_NvmBlock_CmnMfgSrv_NxtrMfgEnaCntr.InvalidateNvBlock
        OIT_ReadBlock_PSProxy_Rte_NvmBlock_CmnMfgSrv_NxtrMfgEnaCntr_ReadBlock: start-on-event=ReadBlock, operation=PSProxy_Rte_NvmBlock_CmnMfgSrv_NxtrMfgEnaCntr.ReadBlock
        OIT_RestoreBlockDefaults_PSProxy_Rte_NvmBlock_CmnMfgSrv_NxtrMfgEnaCntr_RestoreBlockDefaults: start-on-event=RestoreBlockDefaults, operation=PSProxy_Rte_NvmBlock_CmnMfgSrv_NxtrMfgEnaCntr.RestoreBlockDefaults
        OIT_SetRamBlockStatus_PSProxy_Rte_NvmBlock_CmnMfgSrv_NxtrMfgEnaCntr_SetRamBlockStatus: start-on-event=SetRamBlockStatus, operation=PSProxy_Rte_NvmBlock_CmnMfgSrv_NxtrMfgEnaCntr.SetRamBlockStatus
        OIT_WriteBlock_PSProxy_Rte_NvmBlock_CmnMfgSrv_NxtrMfgEnaCntr_WriteBlock: start-on-event=WriteBlock, operation=PSProxy_Rte_NvmBlock_CmnMfgSrv_NxtrMfgEnaCntr.WriteBlock
        OIT_EraseBlock_PSProxy_Rte_NvmBlock_CmnMfgSrv_SeedKey_EraseBlock: start-on-event=EraseBlock, operation=PSProxy_Rte_NvmBlock_CmnMfgSrv_SeedKey.EraseBlock
        OIT_GetErrorStatus_PSProxy_Rte_NvmBlock_CmnMfgSrv_SeedKey_GetErrorStatus: start-on-event=GetErrorStatus, operation=PSProxy_Rte_NvmBlock_CmnMfgSrv_SeedKey.GetErrorStatus
        OIT_InvalidateNvBlock_PSProxy_Rte_NvmBlock_CmnMfgSrv_SeedKey_InvalidateNvBlock: start-on-event=InvalidateNvBlock, operation=PSProxy_Rte_NvmBlock_CmnMfgSrv_SeedKey.InvalidateNvBlock
        OIT_ReadBlock_PSProxy_Rte_NvmBlock_CmnMfgSrv_SeedKey_ReadBlock: start-on-event=ReadBlock, operation=PSProxy_Rte_NvmBlock_CmnMfgSrv_SeedKey.ReadBlock
        OIT_RestoreBlockDefaults_PSProxy_Rte_NvmBlock_CmnMfgSrv_SeedKey_RestoreBlockDefaults: start-on-event=RestoreBlockDefaults, operation=PSProxy_Rte_NvmBlock_CmnMfgSrv_SeedKey.RestoreBlockDefaults
        OIT_SetRamBlockStatus_PSProxy_Rte_NvmBlock_CmnMfgSrv_SeedKey_SetRamBlockStatus: start-on-event=SetRamBlockStatus, operation=PSProxy_Rte_NvmBlock_CmnMfgSrv_SeedKey.SetRamBlockStatus
        OIT_WriteBlock_PSProxy_Rte_NvmBlock_CmnMfgSrv_SeedKey_WriteBlock: start-on-event=WriteBlock, operation=PSProxy_Rte_NvmBlock_CmnMfgSrv_SeedKey.WriteBlock
        OIT_EraseBlock_PSProxy_Rte_NvmBlock_PolarityCfg_PolarityCfgSaved_EraseBlock: start-on-event=EraseBlock, operation=PSProxy_Rte_NvmBlock_PolarityCfg_PolarityCfgSaved.EraseBlock
        OIT_GetErrorStatus_PSProxy_Rte_NvmBlock_PolarityCfg_PolarityCfgSaved_GetErrorStatus: start-on-event=GetErrorStatus, operation=PSProxy_Rte_NvmBlock_PolarityCfg_PolarityCfgSaved.GetErrorStatus
        OIT_InvalidateNvBlock_PSProxy_Rte_NvmBlock_PolarityCfg_PolarityCfgSaved_InvalidateNvBlock: start-on-event=InvalidateNvBlock, operation=PSProxy_Rte_NvmBlock_PolarityCfg_PolarityCfgSaved.InvalidateNvBlock
        OIT_ReadBlock_PSProxy_Rte_NvmBlock_PolarityCfg_PolarityCfgSaved_ReadBlock: start-on-event=ReadBlock, operation=PSProxy_Rte_NvmBlock_PolarityCfg_PolarityCfgSaved.ReadBlock
        OIT_RestoreBlockDefaults_PSProxy_Rte_NvmBlock_PolarityCfg_PolarityCfgSaved_RestoreBlockDefaults: start-on-event=RestoreBlockDefaults, operation=PSProxy_Rte_NvmBlock_PolarityCfg_PolarityCfgSaved.RestoreBlockDefaults
        OIT_SetRamBlockStatus_PSProxy_Rte_NvmBlock_PolarityCfg_PolarityCfgSaved_SetRamBlockStatus: start-on-event=SetRamBlockStatus, operation=PSProxy_Rte_NvmBlock_PolarityCfg_PolarityCfgSaved.SetRamBlockStatus
        OIT_WriteBlock_PSProxy_Rte_NvmBlock_PolarityCfg_PolarityCfgSaved_WriteBlock: start-on-event=WriteBlock, operation=PSProxy_Rte_NvmBlock_PolarityCfg_PolarityCfgSaved.WriteBlock
        OIT_EraseBlock_PSProxy_Rte_NvmBlock_CDD_MotAgCmp_MotAgCmpMotAgBackEmf_EraseBlock: start-on-event=EraseBlock, operation=PSProxy_Rte_NvmBlock_CDD_MotAgCmp_MotAgCmpMotAgBackEmf.EraseBlock
        OIT_GetErrorStatus_PSProxy_Rte_NvmBlock_CDD_MotAgCmp_MotAgCmpMotAgBackEmf_GetErrorStatus: start-on-event=GetErrorStatus, operation=PSProxy_Rte_NvmBlock_CDD_MotAgCmp_MotAgCmpMotAgBackEmf.GetErrorStatus
        OIT_InvalidateNvBlock_PSProxy_Rte_NvmBlock_CDD_MotAgCmp_MotAgCmpMotAgBackEmf_InvalidateNvBlock: start-on-event=InvalidateNvBlock, operation=PSProxy_Rte_NvmBlock_CDD_MotAgCmp_MotAgCmpMotAgBackEmf.InvalidateNvBlock
        OIT_ReadBlock_PSProxy_Rte_NvmBlock_CDD_MotAgCmp_MotAgCmpMotAgBackEmf_ReadBlock: start-on-event=ReadBlock, operation=PSProxy_Rte_NvmBlock_CDD_MotAgCmp_MotAgCmpMotAgBackEmf.ReadBlock
        OIT_RestoreBlockDefaults_PSProxy_Rte_NvmBlock_CDD_MotAgCmp_MotAgCmpMotAgBackEmf_RestoreBlockDefaults: start-on-event=RestoreBlockDefaults, operation=PSProxy_Rte_NvmBlock_CDD_MotAgCmp_MotAgCmpMotAgBackEmf.RestoreBlockDefaults
        OIT_SetRamBlockStatus_PSProxy_Rte_NvmBlock_CDD_MotAgCmp_MotAgCmpMotAgBackEmf_SetRamBlockStatus: start-on-event=SetRamBlockStatus, operation=PSProxy_Rte_NvmBlock_CDD_MotAgCmp_MotAgCmpMotAgBackEmf.SetRamBlockStatus
        OIT_WriteBlock_PSProxy_Rte_NvmBlock_CDD_MotAgCmp_MotAgCmpMotAgBackEmf_WriteBlock: start-on-event=WriteBlock, operation=PSProxy_Rte_NvmBlock_CDD_MotAgCmp_MotAgCmpMotAgBackEmf.WriteBlock
        OIT_EraseBlock_PSProxy_Rte_NvmBlock_HwTqCorrln_HwTqChACmnModCmpLpFilSt_EraseBlock: start-on-event=EraseBlock, operation=PSProxy_Rte_NvmBlock_HwTqCorrln_HwTqChACmnModCmpLpFilSt.EraseBlock
        OIT_GetErrorStatus_PSProxy_Rte_NvmBlock_HwTqCorrln_HwTqChACmnModCmpLpFilSt_GetErrorStatus: start-on-event=GetErrorStatus, operation=PSProxy_Rte_NvmBlock_HwTqCorrln_HwTqChACmnModCmpLpFilSt.GetErrorStatus
        OIT_InvalidateNvBlock_PSProxy_Rte_NvmBlock_HwTqCorrln_HwTqChACmnModCmpLpFilSt_InvalidateNvBlock: start-on-event=InvalidateNvBlock, operation=PSProxy_Rte_NvmBlock_HwTqCorrln_HwTqChACmnModCmpLpFilSt.InvalidateNvBlock
        OIT_ReadBlock_PSProxy_Rte_NvmBlock_HwTqCorrln_HwTqChACmnModCmpLpFilSt_ReadBlock: start-on-event=ReadBlock, operation=PSProxy_Rte_NvmBlock_HwTqCorrln_HwTqChACmnModCmpLpFilSt.ReadBlock
        OIT_RestoreBlockDefaults_PSProxy_Rte_NvmBlock_HwTqCorrln_HwTqChACmnModCmpLpFilSt_RestoreBlockDefaults: start-on-event=RestoreBlockDefaults, operation=PSProxy_Rte_NvmBlock_HwTqCorrln_HwTqChACmnModCmpLpFilSt.RestoreBlockDefaults
        OIT_SetRamBlockStatus_PSProxy_Rte_NvmBlock_HwTqCorrln_HwTqChACmnModCmpLpFilSt_SetRamBlockStatus: start-on-event=SetRamBlockStatus, operation=PSProxy_Rte_NvmBlock_HwTqCorrln_HwTqChACmnModCmpLpFilSt.SetRamBlockStatus
        OIT_WriteBlock_PSProxy_Rte_NvmBlock_HwTqCorrln_HwTqChACmnModCmpLpFilSt_WriteBlock: start-on-event=WriteBlock, operation=PSProxy_Rte_NvmBlock_HwTqCorrln_HwTqChACmnModCmpLpFilSt.WriteBlock
        OIT_EraseBlock_PSProxy_Rte_NvmBlock_Vin_EraseBlock: start-on-event=EraseBlock, operation=PSProxy_Rte_NvmBlock_Vin.EraseBlock
        OIT_GetErrorStatus_PSProxy_Rte_NvmBlock_Vin_GetErrorStatus: start-on-event=GetErrorStatus, operation=PSProxy_Rte_NvmBlock_Vin.GetErrorStatus
        OIT_InvalidateNvBlock_PSProxy_Rte_NvmBlock_Vin_InvalidateNvBlock: start-on-event=InvalidateNvBlock, operation=PSProxy_Rte_NvmBlock_Vin.InvalidateNvBlock
        OIT_ReadBlock_PSProxy_Rte_NvmBlock_Vin_ReadBlock: start-on-event=ReadBlock, operation=PSProxy_Rte_NvmBlock_Vin.ReadBlock
        OIT_RestoreBlockDefaults_PSProxy_Rte_NvmBlock_Vin_RestoreBlockDefaults: start-on-event=RestoreBlockDefaults, operation=PSProxy_Rte_NvmBlock_Vin.RestoreBlockDefaults
        OIT_SetRamBlockStatus_PSProxy_Rte_NvmBlock_Vin_SetRamBlockStatus: start-on-event=SetRamBlockStatus, operation=PSProxy_Rte_NvmBlock_Vin.SetRamBlockStatus
        OIT_WriteBlock_PSProxy_Rte_NvmBlock_Vin_WriteBlock: start-on-event=WriteBlock, operation=PSProxy_Rte_NvmBlock_Vin.WriteBlock
        OIT_EraseBlock_PSProxy_Rte_NvmBlock_Omc_EraseBlock: start-on-event=EraseBlock, operation=PSProxy_Rte_NvmBlock_Omc.EraseBlock
        OIT_GetErrorStatus_PSProxy_Rte_NvmBlock_Omc_GetErrorStatus: start-on-event=GetErrorStatus, operation=PSProxy_Rte_NvmBlock_Omc.GetErrorStatus
        OIT_InvalidateNvBlock_PSProxy_Rte_NvmBlock_Omc_InvalidateNvBlock: start-on-event=InvalidateNvBlock, operation=PSProxy_Rte_NvmBlock_Omc.InvalidateNvBlock
        OIT_ReadBlock_PSProxy_Rte_NvmBlock_Omc_ReadBlock: start-on-event=ReadBlock, operation=PSProxy_Rte_NvmBlock_Omc.ReadBlock
        OIT_RestoreBlockDefaults_PSProxy_Rte_NvmBlock_Omc_RestoreBlockDefaults: start-on-event=RestoreBlockDefaults, operation=PSProxy_Rte_NvmBlock_Omc.RestoreBlockDefaults
        OIT_SetRamBlockStatus_PSProxy_Rte_NvmBlock_Omc_SetRamBlockStatus: start-on-event=SetRamBlockStatus, operation=PSProxy_Rte_NvmBlock_Omc.SetRamBlockStatus
        OIT_WriteBlock_PSProxy_Rte_NvmBlock_Omc_WriteBlock: start-on-event=WriteBlock, operation=PSProxy_Rte_NvmBlock_Omc.WriteBlock
        OIT_EraseBlock_PSProxy_Rte_NvmBlock_Darh_ErrorQueue_EraseBlock: start-on-event=EraseBlock, operation=PSProxy_Rte_NvmBlock_Darh_ErrorQueue.EraseBlock
        OIT_GetErrorStatus_PSProxy_Rte_NvmBlock_Darh_ErrorQueue_GetErrorStatus: start-on-event=GetErrorStatus, operation=PSProxy_Rte_NvmBlock_Darh_ErrorQueue.GetErrorStatus
        OIT_InvalidateNvBlock_PSProxy_Rte_NvmBlock_Darh_ErrorQueue_InvalidateNvBlock: start-on-event=InvalidateNvBlock, operation=PSProxy_Rte_NvmBlock_Darh_ErrorQueue.InvalidateNvBlock
        OIT_ReadBlock_PSProxy_Rte_NvmBlock_Darh_ErrorQueue_ReadBlock: start-on-event=ReadBlock, operation=PSProxy_Rte_NvmBlock_Darh_ErrorQueue.ReadBlock
        OIT_RestoreBlockDefaults_PSProxy_Rte_NvmBlock_Darh_ErrorQueue_RestoreBlockDefaults: start-on-event=RestoreBlockDefaults, operation=PSProxy_Rte_NvmBlock_Darh_ErrorQueue.RestoreBlockDefaults
        OIT_SetRamBlockStatus_PSProxy_Rte_NvmBlock_Darh_ErrorQueue_SetRamBlockStatus: start-on-event=SetRamBlockStatus, operation=PSProxy_Rte_NvmBlock_Darh_ErrorQueue.SetRamBlockStatus
        OIT_WriteBlock_PSProxy_Rte_NvmBlock_Darh_ErrorQueue_WriteBlock: start-on-event=WriteBlock, operation=PSProxy_Rte_NvmBlock_Darh_ErrorQueue.WriteBlock
        OIT_EraseBlock_PSProxy_Rte_NvmBlock_ExcpnHndlg_McuDiagcData_EraseBlock: start-on-event=EraseBlock, operation=PSProxy_Rte_NvmBlock_ExcpnHndlg_McuDiagcData.EraseBlock
        OIT_GetErrorStatus_PSProxy_Rte_NvmBlock_ExcpnHndlg_McuDiagcData_GetErrorStatus: start-on-event=GetErrorStatus, operation=PSProxy_Rte_NvmBlock_ExcpnHndlg_McuDiagcData.GetErrorStatus
        OIT_InvalidateNvBlock_PSProxy_Rte_NvmBlock_ExcpnHndlg_McuDiagcData_InvalidateNvBlock: start-on-event=InvalidateNvBlock, operation=PSProxy_Rte_NvmBlock_ExcpnHndlg_McuDiagcData.InvalidateNvBlock
        OIT_ReadBlock_PSProxy_Rte_NvmBlock_ExcpnHndlg_McuDiagcData_ReadBlock: start-on-event=ReadBlock, operation=PSProxy_Rte_NvmBlock_ExcpnHndlg_McuDiagcData.ReadBlock
        OIT_RestoreBlockDefaults_PSProxy_Rte_NvmBlock_ExcpnHndlg_McuDiagcData_RestoreBlockDefaults: start-on-event=RestoreBlockDefaults, operation=PSProxy_Rte_NvmBlock_ExcpnHndlg_McuDiagcData.RestoreBlockDefaults
        OIT_SetRamBlockStatus_PSProxy_Rte_NvmBlock_ExcpnHndlg_McuDiagcData_SetRamBlockStatus: start-on-event=SetRamBlockStatus, operation=PSProxy_Rte_NvmBlock_ExcpnHndlg_McuDiagcData.SetRamBlockStatus
        OIT_WriteBlock_PSProxy_Rte_NvmBlock_ExcpnHndlg_McuDiagcData_WriteBlock: start-on-event=WriteBlock, operation=PSProxy_Rte_NvmBlock_ExcpnHndlg_McuDiagcData.WriteBlock
        OIT_EraseBlock_PSProxy_Rte_NvmBlock_Coding_CodingData_EraseBlock: start-on-event=EraseBlock, operation=PSProxy_Rte_NvmBlock_Coding_CodingData.EraseBlock
        OIT_GetErrorStatus_PSProxy_Rte_NvmBlock_Coding_CodingData_GetErrorStatus: start-on-event=GetErrorStatus, operation=PSProxy_Rte_NvmBlock_Coding_CodingData.GetErrorStatus
        OIT_InvalidateNvBlock_PSProxy_Rte_NvmBlock_Coding_CodingData_InvalidateNvBlock: start-on-event=InvalidateNvBlock, operation=PSProxy_Rte_NvmBlock_Coding_CodingData.InvalidateNvBlock
        OIT_ReadBlock_PSProxy_Rte_NvmBlock_Coding_CodingData_ReadBlock: start-on-event=ReadBlock, operation=PSProxy_Rte_NvmBlock_Coding_CodingData.ReadBlock
        OIT_RestoreBlockDefaults_PSProxy_Rte_NvmBlock_Coding_CodingData_RestoreBlockDefaults: start-on-event=RestoreBlockDefaults, operation=PSProxy_Rte_NvmBlock_Coding_CodingData.RestoreBlockDefaults
        OIT_SetRamBlockStatus_PSProxy_Rte_NvmBlock_Coding_CodingData_SetRamBlockStatus: start-on-event=SetRamBlockStatus, operation=PSProxy_Rte_NvmBlock_Coding_CodingData.SetRamBlockStatus
        OIT_WriteBlock_PSProxy_Rte_NvmBlock_Coding_CodingData_WriteBlock: start-on-event=WriteBlock, operation=PSProxy_Rte_NvmBlock_Coding_CodingData.WriteBlock
        OIT_EraseBlock_PSProxy_Rte_NvmBlock_BmwTunSetHndlr_BmwDesIninIdx_EraseBlock: start-on-event=EraseBlock, operation=PSProxy_Rte_NvmBlock_BmwTunSetHndlr_BmwDesIninIdx.EraseBlock
        OIT_GetErrorStatus_PSProxy_Rte_NvmBlock_BmwTunSetHndlr_BmwDesIninIdx_GetErrorStatus: start-on-event=GetErrorStatus, operation=PSProxy_Rte_NvmBlock_BmwTunSetHndlr_BmwDesIninIdx.GetErrorStatus
        OIT_InvalidateNvBlock_PSProxy_Rte_NvmBlock_BmwTunSetHndlr_BmwDesIninIdx_InvalidateNvBlock: start-on-event=InvalidateNvBlock, operation=PSProxy_Rte_NvmBlock_BmwTunSetHndlr_BmwDesIninIdx.InvalidateNvBlock
        OIT_ReadBlock_PSProxy_Rte_NvmBlock_BmwTunSetHndlr_BmwDesIninIdx_ReadBlock: start-on-event=ReadBlock, operation=PSProxy_Rte_NvmBlock_BmwTunSetHndlr_BmwDesIninIdx.ReadBlock
        OIT_RestoreBlockDefaults_PSProxy_Rte_NvmBlock_BmwTunSetHndlr_BmwDesIninIdx_RestoreBlockDefaults: start-on-event=RestoreBlockDefaults, operation=PSProxy_Rte_NvmBlock_BmwTunSetHndlr_BmwDesIninIdx.RestoreBlockDefaults
        OIT_SetRamBlockStatus_PSProxy_Rte_NvmBlock_BmwTunSetHndlr_BmwDesIninIdx_SetRamBlockStatus: start-on-event=SetRamBlockStatus, operation=PSProxy_Rte_NvmBlock_BmwTunSetHndlr_BmwDesIninIdx.SetRamBlockStatus
        OIT_WriteBlock_PSProxy_Rte_NvmBlock_BmwTunSetHndlr_BmwDesIninIdx_WriteBlock: start-on-event=WriteBlock, operation=PSProxy_Rte_NvmBlock_BmwTunSetHndlr_BmwDesIninIdx.WriteBlock
        OIT_EraseBlock_PSProxy_Rte_NvmBlock_BmwTunSetHndlr_NvmBmwDesIninOptSetAIdx_EraseBlock: start-on-event=EraseBlock, operation=PSProxy_Rte_NvmBlock_BmwTunSetHndlr_NvmBmwDesIninOptSetAIdx.EraseBlock
        OIT_GetErrorStatus_PSProxy_Rte_NvmBlock_BmwTunSetHndlr_NvmBmwDesIninOptSetAIdx_GetErrorStatus: start-on-event=GetErrorStatus, operation=PSProxy_Rte_NvmBlock_BmwTunSetHndlr_NvmBmwDesIninOptSetAIdx.GetErrorStatus
        OIT_InvalidateNvBlock_PSProxy_Rte_NvmBlock_BmwTunSetHndlr_NvmBmwDesIninOptSetAIdx_InvalidateNvBlock: start-on-event=InvalidateNvBlock, operation=PSProxy_Rte_NvmBlock_BmwTunSetHndlr_NvmBmwDesIninOptSetAIdx.InvalidateNvBlock
        OIT_ReadBlock_PSProxy_Rte_NvmBlock_BmwTunSetHndlr_NvmBmwDesIninOptSetAIdx_ReadBlock: start-on-event=ReadBlock, operation=PSProxy_Rte_NvmBlock_BmwTunSetHndlr_NvmBmwDesIninOptSetAIdx.ReadBlock
        OIT_RestoreBlockDefaults_PSProxy_Rte_NvmBlock_BmwTunSetHndlr_NvmBmwDesIninOptSetAIdx_RestoreBlockDefaults: start-on-event=RestoreBlockDefaults, operation=PSProxy_Rte_NvmBlock_BmwTunSetHndlr_NvmBmwDesIninOptSetAIdx.RestoreBlockDefaults
        OIT_SetRamBlockStatus_PSProxy_Rte_NvmBlock_BmwTunSetHndlr_NvmBmwDesIninOptSetAIdx_SetRamBlockStatus: start-on-event=SetRamBlockStatus, operation=PSProxy_Rte_NvmBlock_BmwTunSetHndlr_NvmBmwDesIninOptSetAIdx.SetRamBlockStatus
        OIT_WriteBlock_PSProxy_Rte_NvmBlock_BmwTunSetHndlr_NvmBmwDesIninOptSetAIdx_WriteBlock: start-on-event=WriteBlock, operation=PSProxy_Rte_NvmBlock_BmwTunSetHndlr_NvmBmwDesIninOptSetAIdx.WriteBlock
        OIT_EraseBlock_PSProxy_Rte_NvmBlock_BmwDiagcSrvHndlg_ProgCntrMaxVal_EraseBlock: start-on-event=EraseBlock, operation=PSProxy_Rte_NvmBlock_BmwDiagcSrvHndlg_ProgCntrMaxVal.EraseBlock
        OIT_GetErrorStatus_PSProxy_Rte_NvmBlock_BmwDiagcSrvHndlg_ProgCntrMaxVal_GetErrorStatus: start-on-event=GetErrorStatus, operation=PSProxy_Rte_NvmBlock_BmwDiagcSrvHndlg_ProgCntrMaxVal.GetErrorStatus
        OIT_InvalidateNvBlock_PSProxy_Rte_NvmBlock_BmwDiagcSrvHndlg_ProgCntrMaxVal_InvalidateNvBlock: start-on-event=InvalidateNvBlock, operation=PSProxy_Rte_NvmBlock_BmwDiagcSrvHndlg_ProgCntrMaxVal.InvalidateNvBlock
        OIT_ReadBlock_PSProxy_Rte_NvmBlock_BmwDiagcSrvHndlg_ProgCntrMaxVal_ReadBlock: start-on-event=ReadBlock, operation=PSProxy_Rte_NvmBlock_BmwDiagcSrvHndlg_ProgCntrMaxVal.ReadBlock
        OIT_RestoreBlockDefaults_PSProxy_Rte_NvmBlock_BmwDiagcSrvHndlg_ProgCntrMaxVal_RestoreBlockDefaults: start-on-event=RestoreBlockDefaults, operation=PSProxy_Rte_NvmBlock_BmwDiagcSrvHndlg_ProgCntrMaxVal.RestoreBlockDefaults
        OIT_SetRamBlockStatus_PSProxy_Rte_NvmBlock_BmwDiagcSrvHndlg_ProgCntrMaxVal_SetRamBlockStatus: start-on-event=SetRamBlockStatus, operation=PSProxy_Rte_NvmBlock_BmwDiagcSrvHndlg_ProgCntrMaxVal.SetRamBlockStatus
        OIT_WriteBlock_PSProxy_Rte_NvmBlock_BmwDiagcSrvHndlg_ProgCntrMaxVal_WriteBlock: start-on-event=WriteBlock, operation=PSProxy_Rte_NvmBlock_BmwDiagcSrvHndlg_ProgCntrMaxVal.WriteBlock
        OIT_EraseBlock_PSProxy_Rte_NvmBlock_PullCmpActv_PullCmpLongTerm_EraseBlock: start-on-event=EraseBlock, operation=PSProxy_Rte_NvmBlock_PullCmpActv_PullCmpLongTerm.EraseBlock
        OIT_GetErrorStatus_PSProxy_Rte_NvmBlock_PullCmpActv_PullCmpLongTerm_GetErrorStatus: start-on-event=GetErrorStatus, operation=PSProxy_Rte_NvmBlock_PullCmpActv_PullCmpLongTerm.GetErrorStatus
        OIT_InvalidateNvBlock_PSProxy_Rte_NvmBlock_PullCmpActv_PullCmpLongTerm_InvalidateNvBlock: start-on-event=InvalidateNvBlock, operation=PSProxy_Rte_NvmBlock_PullCmpActv_PullCmpLongTerm.InvalidateNvBlock
        OIT_ReadBlock_PSProxy_Rte_NvmBlock_PullCmpActv_PullCmpLongTerm_ReadBlock: start-on-event=ReadBlock, operation=PSProxy_Rte_NvmBlock_PullCmpActv_PullCmpLongTerm.ReadBlock
        OIT_RestoreBlockDefaults_PSProxy_Rte_NvmBlock_PullCmpActv_PullCmpLongTerm_RestoreBlockDefaults: start-on-event=RestoreBlockDefaults, operation=PSProxy_Rte_NvmBlock_PullCmpActv_PullCmpLongTerm.RestoreBlockDefaults
        OIT_SetRamBlockStatus_PSProxy_Rte_NvmBlock_PullCmpActv_PullCmpLongTerm_SetRamBlockStatus: start-on-event=SetRamBlockStatus, operation=PSProxy_Rte_NvmBlock_PullCmpActv_PullCmpLongTerm.SetRamBlockStatus
        OIT_WriteBlock_PSProxy_Rte_NvmBlock_PullCmpActv_PullCmpLongTerm_WriteBlock: start-on-event=WriteBlock, operation=PSProxy_Rte_NvmBlock_PullCmpActv_PullCmpLongTerm.WriteBlock
        OIT_EraseBlock_PSProxy_NVM_BLOCK_DLOG_SVK_ENTRY_EraseBlock: start-on-event=EraseBlock, operation=PSProxy_NVM_BLOCK_DLOG_SVK_ENTRY.EraseBlock
        OIT_GetDataIndex_PSProxy_NVM_BLOCK_DLOG_SVK_ENTRY_GetDataIndex: start-on-event=GetDataIndex, operation=PSProxy_NVM_BLOCK_DLOG_SVK_ENTRY.GetDataIndex
        OIT_GetErrorStatus_PSProxy_NVM_BLOCK_DLOG_SVK_ENTRY_GetErrorStatus: start-on-event=GetErrorStatus, operation=PSProxy_NVM_BLOCK_DLOG_SVK_ENTRY.GetErrorStatus
        OIT_InvalidateNvBlock_PSProxy_NVM_BLOCK_DLOG_SVK_ENTRY_InvalidateNvBlock: start-on-event=InvalidateNvBlock, operation=PSProxy_NVM_BLOCK_DLOG_SVK_ENTRY.InvalidateNvBlock
        OIT_ReadBlock_PSProxy_NVM_BLOCK_DLOG_SVK_ENTRY_ReadBlock: start-on-event=ReadBlock, operation=PSProxy_NVM_BLOCK_DLOG_SVK_ENTRY.ReadBlock
        OIT_SetDataIndex_PSProxy_NVM_BLOCK_DLOG_SVK_ENTRY_SetDataIndex: start-on-event=SetDataIndex, operation=PSProxy_NVM_BLOCK_DLOG_SVK_ENTRY.SetDataIndex
        OIT_SetRamBlockStatus_PSProxy_NVM_BLOCK_DLOG_SVK_ENTRY_SetRamBlockStatus: start-on-event=SetRamBlockStatus, operation=PSProxy_NVM_BLOCK_DLOG_SVK_ENTRY.SetRamBlockStatus
        OIT_WriteBlock_PSProxy_NVM_BLOCK_DLOG_SVK_ENTRY_WriteBlock: start-on-event=WriteBlock, operation=PSProxy_NVM_BLOCK_DLOG_SVK_ENTRY.WriteBlock
        OIT_EraseBlock_PSProxy_Rte_NvmBlock_CDD_NvMProxy_ShtdwnClsChk_EraseBlock: start-on-event=EraseBlock, operation=PSProxy_Rte_NvmBlock_CDD_NvMProxy_ShtdwnClsChk.EraseBlock
        OIT_GetErrorStatus_PSProxy_Rte_NvmBlock_CDD_NvMProxy_ShtdwnClsChk_GetErrorStatus: start-on-event=GetErrorStatus, operation=PSProxy_Rte_NvmBlock_CDD_NvMProxy_ShtdwnClsChk.GetErrorStatus
        OIT_InvalidateNvBlock_PSProxy_Rte_NvmBlock_CDD_NvMProxy_ShtdwnClsChk_InvalidateNvBlock: start-on-event=InvalidateNvBlock, operation=PSProxy_Rte_NvmBlock_CDD_NvMProxy_ShtdwnClsChk.InvalidateNvBlock
        OIT_ReadBlock_PSProxy_Rte_NvmBlock_CDD_NvMProxy_ShtdwnClsChk_ReadBlock: start-on-event=ReadBlock, operation=PSProxy_Rte_NvmBlock_CDD_NvMProxy_ShtdwnClsChk.ReadBlock
        OIT_SetRamBlockStatus_PSProxy_Rte_NvmBlock_CDD_NvMProxy_ShtdwnClsChk_SetRamBlockStatus: start-on-event=SetRamBlockStatus, operation=PSProxy_Rte_NvmBlock_CDD_NvMProxy_ShtdwnClsChk.SetRamBlockStatus
        OIT_WriteBlock_PSProxy_Rte_NvmBlock_CDD_NvMProxy_ShtdwnClsChk_WriteBlock: start-on-event=WriteBlock, operation=PSProxy_Rte_NvmBlock_CDD_NvMProxy_ShtdwnClsChk.WriteBlock
        OIT_EraseBlock_PSProxy_Rte_NvmBlock_DiagcMgr_DiagcMgrNtcFltAry_EraseBlock: start-on-event=EraseBlock, operation=PSProxy_Rte_NvmBlock_DiagcMgr_DiagcMgrNtcFltAry.EraseBlock
        OIT_GetErrorStatus_PSProxy_Rte_NvmBlock_DiagcMgr_DiagcMgrNtcFltAry_GetErrorStatus: start-on-event=GetErrorStatus, operation=PSProxy_Rte_NvmBlock_DiagcMgr_DiagcMgrNtcFltAry.GetErrorStatus
        OIT_InvalidateNvBlock_PSProxy_Rte_NvmBlock_DiagcMgr_DiagcMgrNtcFltAry_InvalidateNvBlock: start-on-event=InvalidateNvBlock, operation=PSProxy_Rte_NvmBlock_DiagcMgr_DiagcMgrNtcFltAry.InvalidateNvBlock
        OIT_ReadBlock_PSProxy_Rte_NvmBlock_DiagcMgr_DiagcMgrNtcFltAry_ReadBlock: start-on-event=ReadBlock, operation=PSProxy_Rte_NvmBlock_DiagcMgr_DiagcMgrNtcFltAry.ReadBlock
        OIT_SetRamBlockStatus_PSProxy_Rte_NvmBlock_DiagcMgr_DiagcMgrNtcFltAry_SetRamBlockStatus: start-on-event=SetRamBlockStatus, operation=PSProxy_Rte_NvmBlock_DiagcMgr_DiagcMgrNtcFltAry.SetRamBlockStatus
        OIT_WriteBlock_PSProxy_Rte_NvmBlock_DiagcMgr_DiagcMgrNtcFltAry_WriteBlock: start-on-event=WriteBlock, operation=PSProxy_Rte_NvmBlock_DiagcMgr_DiagcMgrNtcFltAry.WriteBlock
        OIT_EraseBlock_PSProxy_Rte_NvmBlock_DiagcMgr_DiagcMgrLtchCntrAry_EraseBlock: start-on-event=EraseBlock, operation=PSProxy_Rte_NvmBlock_DiagcMgr_DiagcMgrLtchCntrAry.EraseBlock
        OIT_GetErrorStatus_PSProxy_Rte_NvmBlock_DiagcMgr_DiagcMgrLtchCntrAry_GetErrorStatus: start-on-event=GetErrorStatus, operation=PSProxy_Rte_NvmBlock_DiagcMgr_DiagcMgrLtchCntrAry.GetErrorStatus
        OIT_InvalidateNvBlock_PSProxy_Rte_NvmBlock_DiagcMgr_DiagcMgrLtchCntrAry_InvalidateNvBlock: start-on-event=InvalidateNvBlock, operation=PSProxy_Rte_NvmBlock_DiagcMgr_DiagcMgrLtchCntrAry.InvalidateNvBlock
        OIT_ReadBlock_PSProxy_Rte_NvmBlock_DiagcMgr_DiagcMgrLtchCntrAry_ReadBlock: start-on-event=ReadBlock, operation=PSProxy_Rte_NvmBlock_DiagcMgr_DiagcMgrLtchCntrAry.ReadBlock
        OIT_SetRamBlockStatus_PSProxy_Rte_NvmBlock_DiagcMgr_DiagcMgrLtchCntrAry_SetRamBlockStatus: start-on-event=SetRamBlockStatus, operation=PSProxy_Rte_NvmBlock_DiagcMgr_DiagcMgrLtchCntrAry.SetRamBlockStatus
        OIT_WriteBlock_PSProxy_Rte_NvmBlock_DiagcMgr_DiagcMgrLtchCntrAry_WriteBlock: start-on-event=WriteBlock, operation=PSProxy_Rte_NvmBlock_DiagcMgr_DiagcMgrLtchCntrAry.WriteBlock
        OIT_EraseBlock_PSProxy_Rte_NvmBlock_CDD_MotAg0Meas_MotAg0CoeffTbl_EraseBlock: start-on-event=EraseBlock, operation=PSProxy_Rte_NvmBlock_CDD_MotAg0Meas_MotAg0CoeffTbl.EraseBlock
        OIT_GetErrorStatus_PSProxy_Rte_NvmBlock_CDD_MotAg0Meas_MotAg0CoeffTbl_GetErrorStatus: start-on-event=GetErrorStatus, operation=PSProxy_Rte_NvmBlock_CDD_MotAg0Meas_MotAg0CoeffTbl.GetErrorStatus
        OIT_InvalidateNvBlock_PSProxy_Rte_NvmBlock_CDD_MotAg0Meas_MotAg0CoeffTbl_InvalidateNvBlock: start-on-event=InvalidateNvBlock, operation=PSProxy_Rte_NvmBlock_CDD_MotAg0Meas_MotAg0CoeffTbl.InvalidateNvBlock
        OIT_ReadBlock_PSProxy_Rte_NvmBlock_CDD_MotAg0Meas_MotAg0CoeffTbl_ReadBlock: start-on-event=ReadBlock, operation=PSProxy_Rte_NvmBlock_CDD_MotAg0Meas_MotAg0CoeffTbl.ReadBlock
        OIT_SetRamBlockStatus_PSProxy_Rte_NvmBlock_CDD_MotAg0Meas_MotAg0CoeffTbl_SetRamBlockStatus: start-on-event=SetRamBlockStatus, operation=PSProxy_Rte_NvmBlock_CDD_MotAg0Meas_MotAg0CoeffTbl.SetRamBlockStatus
        OIT_WriteBlock_PSProxy_Rte_NvmBlock_CDD_MotAg0Meas_MotAg0CoeffTbl_WriteBlock: start-on-event=WriteBlock, operation=PSProxy_Rte_NvmBlock_CDD_MotAg0Meas_MotAg0CoeffTbl.WriteBlock
        OIT_EraseBlock_PSProxy_Rte_NvmBlock_CDD_MotAg1Meas_MotAg1CoeffTbl_EraseBlock: start-on-event=EraseBlock, operation=PSProxy_Rte_NvmBlock_CDD_MotAg1Meas_MotAg1CoeffTbl.EraseBlock
        OIT_GetErrorStatus_PSProxy_Rte_NvmBlock_CDD_MotAg1Meas_MotAg1CoeffTbl_GetErrorStatus: start-on-event=GetErrorStatus, operation=PSProxy_Rte_NvmBlock_CDD_MotAg1Meas_MotAg1CoeffTbl.GetErrorStatus
        OIT_InvalidateNvBlock_PSProxy_Rte_NvmBlock_CDD_MotAg1Meas_MotAg1CoeffTbl_InvalidateNvBlock: start-on-event=InvalidateNvBlock, operation=PSProxy_Rte_NvmBlock_CDD_MotAg1Meas_MotAg1CoeffTbl.InvalidateNvBlock
        OIT_ReadBlock_PSProxy_Rte_NvmBlock_CDD_MotAg1Meas_MotAg1CoeffTbl_ReadBlock: start-on-event=ReadBlock, operation=PSProxy_Rte_NvmBlock_CDD_MotAg1Meas_MotAg1CoeffTbl.ReadBlock
        OIT_SetRamBlockStatus_PSProxy_Rte_NvmBlock_CDD_MotAg1Meas_MotAg1CoeffTbl_SetRamBlockStatus: start-on-event=SetRamBlockStatus, operation=PSProxy_Rte_NvmBlock_CDD_MotAg1Meas_MotAg1CoeffTbl.SetRamBlockStatus
        OIT_WriteBlock_PSProxy_Rte_NvmBlock_CDD_MotAg1Meas_MotAg1CoeffTbl_WriteBlock: start-on-event=WriteBlock, operation=PSProxy_Rte_NvmBlock_CDD_MotAg1Meas_MotAg1CoeffTbl.WriteBlock
        OIT_EraseBlock_PSProxy_Rte_NvmBlock_CmnMfgSrv_CcaHwPartNr_EraseBlock: start-on-event=EraseBlock, operation=PSProxy_Rte_NvmBlock_CmnMfgSrv_CcaHwPartNr.EraseBlock
        OIT_GetErrorStatus_PSProxy_Rte_NvmBlock_CmnMfgSrv_CcaHwPartNr_GetErrorStatus: start-on-event=GetErrorStatus, operation=PSProxy_Rte_NvmBlock_CmnMfgSrv_CcaHwPartNr.GetErrorStatus
        OIT_InvalidateNvBlock_PSProxy_Rte_NvmBlock_CmnMfgSrv_CcaHwPartNr_InvalidateNvBlock: start-on-event=InvalidateNvBlock, operation=PSProxy_Rte_NvmBlock_CmnMfgSrv_CcaHwPartNr.InvalidateNvBlock
        OIT_ReadBlock_PSProxy_Rte_NvmBlock_CmnMfgSrv_CcaHwPartNr_ReadBlock: start-on-event=ReadBlock, operation=PSProxy_Rte_NvmBlock_CmnMfgSrv_CcaHwPartNr.ReadBlock
        OIT_SetRamBlockStatus_PSProxy_Rte_NvmBlock_CmnMfgSrv_CcaHwPartNr_SetRamBlockStatus: start-on-event=SetRamBlockStatus, operation=PSProxy_Rte_NvmBlock_CmnMfgSrv_CcaHwPartNr.SetRamBlockStatus
        OIT_WriteBlock_PSProxy_Rte_NvmBlock_CmnMfgSrv_CcaHwPartNr_WriteBlock: start-on-event=WriteBlock, operation=PSProxy_Rte_NvmBlock_CmnMfgSrv_CcaHwPartNr.WriteBlock
        OIT_EraseBlock_PSProxy_Rte_NvmBlock_CmnMfgSrv_CcaSerlNr_EraseBlock: start-on-event=EraseBlock, operation=PSProxy_Rte_NvmBlock_CmnMfgSrv_CcaSerlNr.EraseBlock
        OIT_GetErrorStatus_PSProxy_Rte_NvmBlock_CmnMfgSrv_CcaSerlNr_GetErrorStatus: start-on-event=GetErrorStatus, operation=PSProxy_Rte_NvmBlock_CmnMfgSrv_CcaSerlNr.GetErrorStatus
        OIT_InvalidateNvBlock_PSProxy_Rte_NvmBlock_CmnMfgSrv_CcaSerlNr_InvalidateNvBlock: start-on-event=InvalidateNvBlock, operation=PSProxy_Rte_NvmBlock_CmnMfgSrv_CcaSerlNr.InvalidateNvBlock
        OIT_ReadBlock_PSProxy_Rte_NvmBlock_CmnMfgSrv_CcaSerlNr_ReadBlock: start-on-event=ReadBlock, operation=PSProxy_Rte_NvmBlock_CmnMfgSrv_CcaSerlNr.ReadBlock
        OIT_SetRamBlockStatus_PSProxy_Rte_NvmBlock_CmnMfgSrv_CcaSerlNr_SetRamBlockStatus: start-on-event=SetRamBlockStatus, operation=PSProxy_Rte_NvmBlock_CmnMfgSrv_CcaSerlNr.SetRamBlockStatus
        OIT_WriteBlock_PSProxy_Rte_NvmBlock_CmnMfgSrv_CcaSerlNr_WriteBlock: start-on-event=WriteBlock, operation=PSProxy_Rte_NvmBlock_CmnMfgSrv_CcaSerlNr.WriteBlock
        OIT_EraseBlock_PSProxy_Rte_NvmBlock_CmnMfgSrv_DiRestore_EraseBlock: start-on-event=EraseBlock, operation=PSProxy_Rte_NvmBlock_CmnMfgSrv_DiRestore.EraseBlock
        OIT_GetErrorStatus_PSProxy_Rte_NvmBlock_CmnMfgSrv_DiRestore_GetErrorStatus: start-on-event=GetErrorStatus, operation=PSProxy_Rte_NvmBlock_CmnMfgSrv_DiRestore.GetErrorStatus
        OIT_InvalidateNvBlock_PSProxy_Rte_NvmBlock_CmnMfgSrv_DiRestore_InvalidateNvBlock: start-on-event=InvalidateNvBlock, operation=PSProxy_Rte_NvmBlock_CmnMfgSrv_DiRestore.InvalidateNvBlock
        OIT_ReadBlock_PSProxy_Rte_NvmBlock_CmnMfgSrv_DiRestore_ReadBlock: start-on-event=ReadBlock, operation=PSProxy_Rte_NvmBlock_CmnMfgSrv_DiRestore.ReadBlock
        OIT_SetRamBlockStatus_PSProxy_Rte_NvmBlock_CmnMfgSrv_DiRestore_SetRamBlockStatus: start-on-event=SetRamBlockStatus, operation=PSProxy_Rte_NvmBlock_CmnMfgSrv_DiRestore.SetRamBlockStatus
        OIT_WriteBlock_PSProxy_Rte_NvmBlock_CmnMfgSrv_DiRestore_WriteBlock: start-on-event=WriteBlock, operation=PSProxy_Rte_NvmBlock_CmnMfgSrv_DiRestore.WriteBlock
        OIT_EraseBlock_PSProxy_Rte_NvmBlock_CmnMfgSrv_EpsSysSerlNr_EraseBlock: start-on-event=EraseBlock, operation=PSProxy_Rte_NvmBlock_CmnMfgSrv_EpsSysSerlNr.EraseBlock
        OIT_GetErrorStatus_PSProxy_Rte_NvmBlock_CmnMfgSrv_EpsSysSerlNr_GetErrorStatus: start-on-event=GetErrorStatus, operation=PSProxy_Rte_NvmBlock_CmnMfgSrv_EpsSysSerlNr.GetErrorStatus
        OIT_InvalidateNvBlock_PSProxy_Rte_NvmBlock_CmnMfgSrv_EpsSysSerlNr_InvalidateNvBlock: start-on-event=InvalidateNvBlock, operation=PSProxy_Rte_NvmBlock_CmnMfgSrv_EpsSysSerlNr.InvalidateNvBlock
        OIT_ReadBlock_PSProxy_Rte_NvmBlock_CmnMfgSrv_EpsSysSerlNr_ReadBlock: start-on-event=ReadBlock, operation=PSProxy_Rte_NvmBlock_CmnMfgSrv_EpsSysSerlNr.ReadBlock
        OIT_SetRamBlockStatus_PSProxy_Rte_NvmBlock_CmnMfgSrv_EpsSysSerlNr_SetRamBlockStatus: start-on-event=SetRamBlockStatus, operation=PSProxy_Rte_NvmBlock_CmnMfgSrv_EpsSysSerlNr.SetRamBlockStatus
        OIT_WriteBlock_PSProxy_Rte_NvmBlock_CmnMfgSrv_EpsSysSerlNr_WriteBlock: start-on-event=WriteBlock, operation=PSProxy_Rte_NvmBlock_CmnMfgSrv_EpsSysSerlNr.WriteBlock
        OIT_EraseBlock_PSProxy_Rte_NvmBlock_CmnMfgSrv_MfgTmpBuf0_EraseBlock: start-on-event=EraseBlock, operation=PSProxy_Rte_NvmBlock_CmnMfgSrv_MfgTmpBuf0.EraseBlock
        OIT_GetErrorStatus_PSProxy_Rte_NvmBlock_CmnMfgSrv_MfgTmpBuf0_GetErrorStatus: start-on-event=GetErrorStatus, operation=PSProxy_Rte_NvmBlock_CmnMfgSrv_MfgTmpBuf0.GetErrorStatus
        OIT_InvalidateNvBlock_PSProxy_Rte_NvmBlock_CmnMfgSrv_MfgTmpBuf0_InvalidateNvBlock: start-on-event=InvalidateNvBlock, operation=PSProxy_Rte_NvmBlock_CmnMfgSrv_MfgTmpBuf0.InvalidateNvBlock
        OIT_ReadBlock_PSProxy_Rte_NvmBlock_CmnMfgSrv_MfgTmpBuf0_ReadBlock: start-on-event=ReadBlock, operation=PSProxy_Rte_NvmBlock_CmnMfgSrv_MfgTmpBuf0.ReadBlock
        OIT_SetRamBlockStatus_PSProxy_Rte_NvmBlock_CmnMfgSrv_MfgTmpBuf0_SetRamBlockStatus: start-on-event=SetRamBlockStatus, operation=PSProxy_Rte_NvmBlock_CmnMfgSrv_MfgTmpBuf0.SetRamBlockStatus
        OIT_WriteBlock_PSProxy_Rte_NvmBlock_CmnMfgSrv_MfgTmpBuf0_WriteBlock: start-on-event=WriteBlock, operation=PSProxy_Rte_NvmBlock_CmnMfgSrv_MfgTmpBuf0.WriteBlock
        OIT_EraseBlock_PSProxy_Rte_NvmBlock_CmnMfgSrv_MfgTmpBuf1_EraseBlock: start-on-event=EraseBlock, operation=PSProxy_Rte_NvmBlock_CmnMfgSrv_MfgTmpBuf1.EraseBlock
        OIT_GetErrorStatus_PSProxy_Rte_NvmBlock_CmnMfgSrv_MfgTmpBuf1_GetErrorStatus: start-on-event=GetErrorStatus, operation=PSProxy_Rte_NvmBlock_CmnMfgSrv_MfgTmpBuf1.GetErrorStatus
        OIT_InvalidateNvBlock_PSProxy_Rte_NvmBlock_CmnMfgSrv_MfgTmpBuf1_InvalidateNvBlock: start-on-event=InvalidateNvBlock, operation=PSProxy_Rte_NvmBlock_CmnMfgSrv_MfgTmpBuf1.InvalidateNvBlock
        OIT_ReadBlock_PSProxy_Rte_NvmBlock_CmnMfgSrv_MfgTmpBuf1_ReadBlock: start-on-event=ReadBlock, operation=PSProxy_Rte_NvmBlock_CmnMfgSrv_MfgTmpBuf1.ReadBlock
        OIT_SetRamBlockStatus_PSProxy_Rte_NvmBlock_CmnMfgSrv_MfgTmpBuf1_SetRamBlockStatus: start-on-event=SetRamBlockStatus, operation=PSProxy_Rte_NvmBlock_CmnMfgSrv_MfgTmpBuf1.SetRamBlockStatus
        OIT_WriteBlock_PSProxy_Rte_NvmBlock_CmnMfgSrv_MfgTmpBuf1_WriteBlock: start-on-event=WriteBlock, operation=PSProxy_Rte_NvmBlock_CmnMfgSrv_MfgTmpBuf1.WriteBlock
        OIT_EraseBlock_PSProxy_Rte_NvmBlock_CmnMfgSrv_MfgTmpBuf2_EraseBlock: start-on-event=EraseBlock, operation=PSProxy_Rte_NvmBlock_CmnMfgSrv_MfgTmpBuf2.EraseBlock
        OIT_GetErrorStatus_PSProxy_Rte_NvmBlock_CmnMfgSrv_MfgTmpBuf2_GetErrorStatus: start-on-event=GetErrorStatus, operation=PSProxy_Rte_NvmBlock_CmnMfgSrv_MfgTmpBuf2.GetErrorStatus
        OIT_InvalidateNvBlock_PSProxy_Rte_NvmBlock_CmnMfgSrv_MfgTmpBuf2_InvalidateNvBlock: start-on-event=InvalidateNvBlock, operation=PSProxy_Rte_NvmBlock_CmnMfgSrv_MfgTmpBuf2.InvalidateNvBlock
        OIT_ReadBlock_PSProxy_Rte_NvmBlock_CmnMfgSrv_MfgTmpBuf2_ReadBlock: start-on-event=ReadBlock, operation=PSProxy_Rte_NvmBlock_CmnMfgSrv_MfgTmpBuf2.ReadBlock
        OIT_SetRamBlockStatus_PSProxy_Rte_NvmBlock_CmnMfgSrv_MfgTmpBuf2_SetRamBlockStatus: start-on-event=SetRamBlockStatus, operation=PSProxy_Rte_NvmBlock_CmnMfgSrv_MfgTmpBuf2.SetRamBlockStatus
        OIT_WriteBlock_PSProxy_Rte_NvmBlock_CmnMfgSrv_MfgTmpBuf2_WriteBlock: start-on-event=WriteBlock, operation=PSProxy_Rte_NvmBlock_CmnMfgSrv_MfgTmpBuf2.WriteBlock
        OIT_EraseBlock_PSProxy_Rte_NvmBlock_CmnMfgSrv_MfgTmpBuf3_EraseBlock: start-on-event=EraseBlock, operation=PSProxy_Rte_NvmBlock_CmnMfgSrv_MfgTmpBuf3.EraseBlock
        OIT_GetErrorStatus_PSProxy_Rte_NvmBlock_CmnMfgSrv_MfgTmpBuf3_GetErrorStatus: start-on-event=GetErrorStatus, operation=PSProxy_Rte_NvmBlock_CmnMfgSrv_MfgTmpBuf3.GetErrorStatus
        OIT_InvalidateNvBlock_PSProxy_Rte_NvmBlock_CmnMfgSrv_MfgTmpBuf3_InvalidateNvBlock: start-on-event=InvalidateNvBlock, operation=PSProxy_Rte_NvmBlock_CmnMfgSrv_MfgTmpBuf3.InvalidateNvBlock
        OIT_ReadBlock_PSProxy_Rte_NvmBlock_CmnMfgSrv_MfgTmpBuf3_ReadBlock: start-on-event=ReadBlock, operation=PSProxy_Rte_NvmBlock_CmnMfgSrv_MfgTmpBuf3.ReadBlock
        OIT_SetRamBlockStatus_PSProxy_Rte_NvmBlock_CmnMfgSrv_MfgTmpBuf3_SetRamBlockStatus: start-on-event=SetRamBlockStatus, operation=PSProxy_Rte_NvmBlock_CmnMfgSrv_MfgTmpBuf3.SetRamBlockStatus
        OIT_WriteBlock_PSProxy_Rte_NvmBlock_CmnMfgSrv_MfgTmpBuf3_WriteBlock: start-on-event=WriteBlock, operation=PSProxy_Rte_NvmBlock_CmnMfgSrv_MfgTmpBuf3.WriteBlock
        OIT_EraseBlock_PSProxy_Rte_NvmBlock_CmnMfgSrv_MfgTmpBuf4_EraseBlock: start-on-event=EraseBlock, operation=PSProxy_Rte_NvmBlock_CmnMfgSrv_MfgTmpBuf4.EraseBlock
        OIT_GetErrorStatus_PSProxy_Rte_NvmBlock_CmnMfgSrv_MfgTmpBuf4_GetErrorStatus: start-on-event=GetErrorStatus, operation=PSProxy_Rte_NvmBlock_CmnMfgSrv_MfgTmpBuf4.GetErrorStatus
        OIT_InvalidateNvBlock_PSProxy_Rte_NvmBlock_CmnMfgSrv_MfgTmpBuf4_InvalidateNvBlock: start-on-event=InvalidateNvBlock, operation=PSProxy_Rte_NvmBlock_CmnMfgSrv_MfgTmpBuf4.InvalidateNvBlock
        OIT_ReadBlock_PSProxy_Rte_NvmBlock_CmnMfgSrv_MfgTmpBuf4_ReadBlock: start-on-event=ReadBlock, operation=PSProxy_Rte_NvmBlock_CmnMfgSrv_MfgTmpBuf4.ReadBlock
        OIT_SetRamBlockStatus_PSProxy_Rte_NvmBlock_CmnMfgSrv_MfgTmpBuf4_SetRamBlockStatus: start-on-event=SetRamBlockStatus, operation=PSProxy_Rte_NvmBlock_CmnMfgSrv_MfgTmpBuf4.SetRamBlockStatus
        OIT_WriteBlock_PSProxy_Rte_NvmBlock_CmnMfgSrv_MfgTmpBuf4_WriteBlock: start-on-event=WriteBlock, operation=PSProxy_Rte_NvmBlock_CmnMfgSrv_MfgTmpBuf4.WriteBlock
        OIT_EraseBlock_PSProxy_Rte_NvmBlock_CDD_HwTq4Meas_HwTq4Offs_MirrorBlock_EraseBlock: start-on-event=EraseBlock, operation=PSProxy_Rte_NvmBlock_CDD_HwTq4Meas_HwTq4Offs_MirrorBlock.EraseBlock
        OIT_GetErrorStatus_PSProxy_Rte_NvmBlock_CDD_HwTq4Meas_HwTq4Offs_MirrorBlock_GetErrorStatus: start-on-event=GetErrorStatus, operation=PSProxy_Rte_NvmBlock_CDD_HwTq4Meas_HwTq4Offs_MirrorBlock.GetErrorStatus
        OIT_InvalidateNvBlock_PSProxy_Rte_NvmBlock_CDD_HwTq4Meas_HwTq4Offs_MirrorBlock_InvalidateNvBlock: start-on-event=InvalidateNvBlock, operation=PSProxy_Rte_NvmBlock_CDD_HwTq4Meas_HwTq4Offs_MirrorBlock.InvalidateNvBlock
        OIT_ReadBlock_PSProxy_Rte_NvmBlock_CDD_HwTq4Meas_HwTq4Offs_MirrorBlock_ReadBlock: start-on-event=ReadBlock, operation=PSProxy_Rte_NvmBlock_CDD_HwTq4Meas_HwTq4Offs_MirrorBlock.ReadBlock
        OIT_SetRamBlockStatus_PSProxy_Rte_NvmBlock_CDD_HwTq4Meas_HwTq4Offs_MirrorBlock_SetRamBlockStatus: start-on-event=SetRamBlockStatus, operation=PSProxy_Rte_NvmBlock_CDD_HwTq4Meas_HwTq4Offs_MirrorBlock.SetRamBlockStatus
        OIT_WriteBlock_PSProxy_Rte_NvmBlock_CDD_HwTq4Meas_HwTq4Offs_MirrorBlock_WriteBlock: start-on-event=WriteBlock, operation=PSProxy_Rte_NvmBlock_CDD_HwTq4Meas_HwTq4Offs_MirrorBlock.WriteBlock
        OIT_EraseBlock_PSProxy_Rte_NvmBlock_CDD_HwTq5Meas_HwTq5Offs_MirrorBlock_EraseBlock: start-on-event=EraseBlock, operation=PSProxy_Rte_NvmBlock_CDD_HwTq5Meas_HwTq5Offs_MirrorBlock.EraseBlock
        OIT_GetErrorStatus_PSProxy_Rte_NvmBlock_CDD_HwTq5Meas_HwTq5Offs_MirrorBlock_GetErrorStatus: start-on-event=GetErrorStatus, operation=PSProxy_Rte_NvmBlock_CDD_HwTq5Meas_HwTq5Offs_MirrorBlock.GetErrorStatus
        OIT_InvalidateNvBlock_PSProxy_Rte_NvmBlock_CDD_HwTq5Meas_HwTq5Offs_MirrorBlock_InvalidateNvBlock: start-on-event=InvalidateNvBlock, operation=PSProxy_Rte_NvmBlock_CDD_HwTq5Meas_HwTq5Offs_MirrorBlock.InvalidateNvBlock
        OIT_ReadBlock_PSProxy_Rte_NvmBlock_CDD_HwTq5Meas_HwTq5Offs_MirrorBlock_ReadBlock: start-on-event=ReadBlock, operation=PSProxy_Rte_NvmBlock_CDD_HwTq5Meas_HwTq5Offs_MirrorBlock.ReadBlock
        OIT_SetRamBlockStatus_PSProxy_Rte_NvmBlock_CDD_HwTq5Meas_HwTq5Offs_MirrorBlock_SetRamBlockStatus: start-on-event=SetRamBlockStatus, operation=PSProxy_Rte_NvmBlock_CDD_HwTq5Meas_HwTq5Offs_MirrorBlock.SetRamBlockStatus
        OIT_WriteBlock_PSProxy_Rte_NvmBlock_CDD_HwTq5Meas_HwTq5Offs_MirrorBlock_WriteBlock: start-on-event=WriteBlock, operation=PSProxy_Rte_NvmBlock_CDD_HwTq5Meas_HwTq5Offs_MirrorBlock.WriteBlock
        OIT_EraseBlock_PSProxy_Rte_NvmBlock_CDD_HwTq4Meas_HwTq4Sca_MirrorBlock_EraseBlock: start-on-event=EraseBlock, operation=PSProxy_Rte_NvmBlock_CDD_HwTq4Meas_HwTq4Sca_MirrorBlock.EraseBlock
        OIT_GetErrorStatus_PSProxy_Rte_NvmBlock_CDD_HwTq4Meas_HwTq4Sca_MirrorBlock_GetErrorStatus: start-on-event=GetErrorStatus, operation=PSProxy_Rte_NvmBlock_CDD_HwTq4Meas_HwTq4Sca_MirrorBlock.GetErrorStatus
        OIT_InvalidateNvBlock_PSProxy_Rte_NvmBlock_CDD_HwTq4Meas_HwTq4Sca_MirrorBlock_InvalidateNvBlock: start-on-event=InvalidateNvBlock, operation=PSProxy_Rte_NvmBlock_CDD_HwTq4Meas_HwTq4Sca_MirrorBlock.InvalidateNvBlock
        OIT_ReadBlock_PSProxy_Rte_NvmBlock_CDD_HwTq4Meas_HwTq4Sca_MirrorBlock_ReadBlock: start-on-event=ReadBlock, operation=PSProxy_Rte_NvmBlock_CDD_HwTq4Meas_HwTq4Sca_MirrorBlock.ReadBlock
        OIT_SetRamBlockStatus_PSProxy_Rte_NvmBlock_CDD_HwTq4Meas_HwTq4Sca_MirrorBlock_SetRamBlockStatus: start-on-event=SetRamBlockStatus, operation=PSProxy_Rte_NvmBlock_CDD_HwTq4Meas_HwTq4Sca_MirrorBlock.SetRamBlockStatus
        OIT_WriteBlock_PSProxy_Rte_NvmBlock_CDD_HwTq4Meas_HwTq4Sca_MirrorBlock_WriteBlock: start-on-event=WriteBlock, operation=PSProxy_Rte_NvmBlock_CDD_HwTq4Meas_HwTq4Sca_MirrorBlock.WriteBlock
        OIT_EraseBlock_PSProxy_Rte_NvmBlock_CDD_HwTq5Meas_HwTq5Sca_MirrorBlock_EraseBlock: start-on-event=EraseBlock, operation=PSProxy_Rte_NvmBlock_CDD_HwTq5Meas_HwTq5Sca_MirrorBlock.EraseBlock
        OIT_GetErrorStatus_PSProxy_Rte_NvmBlock_CDD_HwTq5Meas_HwTq5Sca_MirrorBlock_GetErrorStatus: start-on-event=GetErrorStatus, operation=PSProxy_Rte_NvmBlock_CDD_HwTq5Meas_HwTq5Sca_MirrorBlock.GetErrorStatus
        OIT_InvalidateNvBlock_PSProxy_Rte_NvmBlock_CDD_HwTq5Meas_HwTq5Sca_MirrorBlock_InvalidateNvBlock: start-on-event=InvalidateNvBlock, operation=PSProxy_Rte_NvmBlock_CDD_HwTq5Meas_HwTq5Sca_MirrorBlock.InvalidateNvBlock
        OIT_ReadBlock_PSProxy_Rte_NvmBlock_CDD_HwTq5Meas_HwTq5Sca_MirrorBlock_ReadBlock: start-on-event=ReadBlock, operation=PSProxy_Rte_NvmBlock_CDD_HwTq5Meas_HwTq5Sca_MirrorBlock.ReadBlock
        OIT_SetRamBlockStatus_PSProxy_Rte_NvmBlock_CDD_HwTq5Meas_HwTq5Sca_MirrorBlock_SetRamBlockStatus: start-on-event=SetRamBlockStatus, operation=PSProxy_Rte_NvmBlock_CDD_HwTq5Meas_HwTq5Sca_MirrorBlock.SetRamBlockStatus
        OIT_WriteBlock_PSProxy_Rte_NvmBlock_CDD_HwTq5Meas_HwTq5Sca_MirrorBlock_WriteBlock: start-on-event=WriteBlock, operation=PSProxy_Rte_NvmBlock_CDD_HwTq5Meas_HwTq5Sca_MirrorBlock.WriteBlock
        OIT_EraseBlock_PSProxy_Rte_NvmBlock_DutyCycThermProtn_FilStVal_EraseBlock: start-on-event=EraseBlock, operation=PSProxy_Rte_NvmBlock_DutyCycThermProtn_FilStVal.EraseBlock
        OIT_GetErrorStatus_PSProxy_Rte_NvmBlock_DutyCycThermProtn_FilStVal_GetErrorStatus: start-on-event=GetErrorStatus, operation=PSProxy_Rte_NvmBlock_DutyCycThermProtn_FilStVal.GetErrorStatus
        OIT_InvalidateNvBlock_PSProxy_Rte_NvmBlock_DutyCycThermProtn_FilStVal_InvalidateNvBlock: start-on-event=InvalidateNvBlock, operation=PSProxy_Rte_NvmBlock_DutyCycThermProtn_FilStVal.InvalidateNvBlock
        OIT_ReadBlock_PSProxy_Rte_NvmBlock_DutyCycThermProtn_FilStVal_ReadBlock: start-on-event=ReadBlock, operation=PSProxy_Rte_NvmBlock_DutyCycThermProtn_FilStVal.ReadBlock
        OIT_SetRamBlockStatus_PSProxy_Rte_NvmBlock_DutyCycThermProtn_FilStVal_SetRamBlockStatus: start-on-event=SetRamBlockStatus, operation=PSProxy_Rte_NvmBlock_DutyCycThermProtn_FilStVal.SetRamBlockStatus
        OIT_WriteBlock_PSProxy_Rte_NvmBlock_DutyCycThermProtn_FilStVal_WriteBlock: start-on-event=WriteBlock, operation=PSProxy_Rte_NvmBlock_DutyCycThermProtn_FilStVal.WriteBlock
        OIT_EraseBlock_PSProxy_Rte_NvmBlock_MotTqCmdSca_MotTqScaFac_EraseBlock: start-on-event=EraseBlock, operation=PSProxy_Rte_NvmBlock_MotTqCmdSca_MotTqScaFac.EraseBlock
        OIT_GetErrorStatus_PSProxy_Rte_NvmBlock_MotTqCmdSca_MotTqScaFac_GetErrorStatus: start-on-event=GetErrorStatus, operation=PSProxy_Rte_NvmBlock_MotTqCmdSca_MotTqScaFac.GetErrorStatus
        OIT_InvalidateNvBlock_PSProxy_Rte_NvmBlock_MotTqCmdSca_MotTqScaFac_InvalidateNvBlock: start-on-event=InvalidateNvBlock, operation=PSProxy_Rte_NvmBlock_MotTqCmdSca_MotTqScaFac.InvalidateNvBlock
        OIT_ReadBlock_PSProxy_Rte_NvmBlock_MotTqCmdSca_MotTqScaFac_ReadBlock: start-on-event=ReadBlock, operation=PSProxy_Rte_NvmBlock_MotTqCmdSca_MotTqScaFac.ReadBlock
        OIT_SetRamBlockStatus_PSProxy_Rte_NvmBlock_MotTqCmdSca_MotTqScaFac_SetRamBlockStatus: start-on-event=SetRamBlockStatus, operation=PSProxy_Rte_NvmBlock_MotTqCmdSca_MotTqScaFac.SetRamBlockStatus
        OIT_WriteBlock_PSProxy_Rte_NvmBlock_MotTqCmdSca_MotTqScaFac_WriteBlock: start-on-event=WriteBlock, operation=PSProxy_Rte_NvmBlock_MotTqCmdSca_MotTqScaFac.WriteBlock
        OIT_EraseBlock_PSProxy_Rte_NvmBlock_MotCtrlPrmEstimn_MotPrmNom_EraseBlock: start-on-event=EraseBlock, operation=PSProxy_Rte_NvmBlock_MotCtrlPrmEstimn_MotPrmNom.EraseBlock
        OIT_GetErrorStatus_PSProxy_Rte_NvmBlock_MotCtrlPrmEstimn_MotPrmNom_GetErrorStatus: start-on-event=GetErrorStatus, operation=PSProxy_Rte_NvmBlock_MotCtrlPrmEstimn_MotPrmNom.GetErrorStatus
        OIT_InvalidateNvBlock_PSProxy_Rte_NvmBlock_MotCtrlPrmEstimn_MotPrmNom_InvalidateNvBlock: start-on-event=InvalidateNvBlock, operation=PSProxy_Rte_NvmBlock_MotCtrlPrmEstimn_MotPrmNom.InvalidateNvBlock
        OIT_ReadBlock_PSProxy_Rte_NvmBlock_MotCtrlPrmEstimn_MotPrmNom_ReadBlock: start-on-event=ReadBlock, operation=PSProxy_Rte_NvmBlock_MotCtrlPrmEstimn_MotPrmNom.ReadBlock
        OIT_SetRamBlockStatus_PSProxy_Rte_NvmBlock_MotCtrlPrmEstimn_MotPrmNom_SetRamBlockStatus: start-on-event=SetRamBlockStatus, operation=PSProxy_Rte_NvmBlock_MotCtrlPrmEstimn_MotPrmNom.SetRamBlockStatus
        OIT_WriteBlock_PSProxy_Rte_NvmBlock_MotCtrlPrmEstimn_MotPrmNom_WriteBlock: start-on-event=WriteBlock, operation=PSProxy_Rte_NvmBlock_MotCtrlPrmEstimn_MotPrmNom.WriteBlock
        OIT_EraseBlock_PSProxy_NVM_BLOCK_BOOT_PROG_COUNTER_EraseBlock: start-on-event=EraseBlock, operation=PSProxy_NVM_BLOCK_BOOT_PROG_COUNTER.EraseBlock
        OIT_GetErrorStatus_PSProxy_NVM_BLOCK_BOOT_PROG_COUNTER_GetErrorStatus: start-on-event=GetErrorStatus, operation=PSProxy_NVM_BLOCK_BOOT_PROG_COUNTER.GetErrorStatus
        OIT_InvalidateNvBlock_PSProxy_NVM_BLOCK_BOOT_PROG_COUNTER_InvalidateNvBlock: start-on-event=InvalidateNvBlock, operation=PSProxy_NVM_BLOCK_BOOT_PROG_COUNTER.InvalidateNvBlock
        OIT_ReadBlock_PSProxy_NVM_BLOCK_BOOT_PROG_COUNTER_ReadBlock: start-on-event=ReadBlock, operation=PSProxy_NVM_BLOCK_BOOT_PROG_COUNTER.ReadBlock
        OIT_SetRamBlockStatus_PSProxy_NVM_BLOCK_BOOT_PROG_COUNTER_SetRamBlockStatus: start-on-event=SetRamBlockStatus, operation=PSProxy_NVM_BLOCK_BOOT_PROG_COUNTER.SetRamBlockStatus
        OIT_WriteBlock_PSProxy_NVM_BLOCK_BOOT_PROG_COUNTER_WriteBlock: start-on-event=WriteBlock, operation=PSProxy_NVM_BLOCK_BOOT_PROG_COUNTER.WriteBlock
        OIT_EraseBlock_PSProxy_NVM_BLOCK_BOOT_PROG_DATA_EraseBlock: start-on-event=EraseBlock, operation=PSProxy_NVM_BLOCK_BOOT_PROG_DATA.EraseBlock
        OIT_GetErrorStatus_PSProxy_NVM_BLOCK_BOOT_PROG_DATA_GetErrorStatus: start-on-event=GetErrorStatus, operation=PSProxy_NVM_BLOCK_BOOT_PROG_DATA.GetErrorStatus
        OIT_InvalidateNvBlock_PSProxy_NVM_BLOCK_BOOT_PROG_DATA_InvalidateNvBlock: start-on-event=InvalidateNvBlock, operation=PSProxy_NVM_BLOCK_BOOT_PROG_DATA.InvalidateNvBlock
        OIT_ReadBlock_PSProxy_NVM_BLOCK_BOOT_PROG_DATA_ReadBlock: start-on-event=ReadBlock, operation=PSProxy_NVM_BLOCK_BOOT_PROG_DATA.ReadBlock
        OIT_SetRamBlockStatus_PSProxy_NVM_BLOCK_BOOT_PROG_DATA_SetRamBlockStatus: start-on-event=SetRamBlockStatus, operation=PSProxy_NVM_BLOCK_BOOT_PROG_DATA.SetRamBlockStatus
        OIT_WriteBlock_PSProxy_NVM_BLOCK_BOOT_PROG_DATA_WriteBlock: start-on-event=WriteBlock, operation=PSProxy_NVM_BLOCK_BOOT_PROG_DATA.WriteBlock
        OIT_EraseBlock_PSProxy_NVM_BLOCK_BOOT_SVK_HISTORY_EraseBlock: start-on-event=EraseBlock, operation=PSProxy_NVM_BLOCK_BOOT_SVK_HISTORY.EraseBlock
        OIT_GetErrorStatus_PSProxy_NVM_BLOCK_BOOT_SVK_HISTORY_GetErrorStatus: start-on-event=GetErrorStatus, operation=PSProxy_NVM_BLOCK_BOOT_SVK_HISTORY.GetErrorStatus
        OIT_InvalidateNvBlock_PSProxy_NVM_BLOCK_BOOT_SVK_HISTORY_InvalidateNvBlock: start-on-event=InvalidateNvBlock, operation=PSProxy_NVM_BLOCK_BOOT_SVK_HISTORY.InvalidateNvBlock
        OIT_ReadBlock_PSProxy_NVM_BLOCK_BOOT_SVK_HISTORY_ReadBlock: start-on-event=ReadBlock, operation=PSProxy_NVM_BLOCK_BOOT_SVK_HISTORY.ReadBlock
        OIT_SetRamBlockStatus_PSProxy_NVM_BLOCK_BOOT_SVK_HISTORY_SetRamBlockStatus: start-on-event=SetRamBlockStatus, operation=PSProxy_NVM_BLOCK_BOOT_SVK_HISTORY.SetRamBlockStatus
        OIT_WriteBlock_PSProxy_NVM_BLOCK_BOOT_SVK_HISTORY_WriteBlock: start-on-event=WriteBlock, operation=PSProxy_NVM_BLOCK_BOOT_SVK_HISTORY.WriteBlock
        OIT_EraseBlock_PSProxy_NVM_BLOCK_DLOG_SVK_SYS_SUPP_EraseBlock: start-on-event=EraseBlock, operation=PSProxy_NVM_BLOCK_DLOG_SVK_SYS_SUPP.EraseBlock
        OIT_GetErrorStatus_PSProxy_NVM_BLOCK_DLOG_SVK_SYS_SUPP_GetErrorStatus: start-on-event=GetErrorStatus, operation=PSProxy_NVM_BLOCK_DLOG_SVK_SYS_SUPP.GetErrorStatus
        OIT_InvalidateNvBlock_PSProxy_NVM_BLOCK_DLOG_SVK_SYS_SUPP_InvalidateNvBlock: start-on-event=InvalidateNvBlock, operation=PSProxy_NVM_BLOCK_DLOG_SVK_SYS_SUPP.InvalidateNvBlock
        OIT_ReadBlock_PSProxy_NVM_BLOCK_DLOG_SVK_SYS_SUPP_ReadBlock: start-on-event=ReadBlock, operation=PSProxy_NVM_BLOCK_DLOG_SVK_SYS_SUPP.ReadBlock
        OIT_SetRamBlockStatus_PSProxy_NVM_BLOCK_DLOG_SVK_SYS_SUPP_SetRamBlockStatus: start-on-event=SetRamBlockStatus, operation=PSProxy_NVM_BLOCK_DLOG_SVK_SYS_SUPP.SetRamBlockStatus
        OIT_WriteBlock_PSProxy_NVM_BLOCK_DLOG_SVK_SYS_SUPP_WriteBlock: start-on-event=WriteBlock, operation=PSProxy_NVM_BLOCK_DLOG_SVK_SYS_SUPP.WriteBlock
        OIT_EraseBlock_PSProxy_NVM_BLOCK_DLOG_SVK_PLANT_EraseBlock: start-on-event=EraseBlock, operation=PSProxy_NVM_BLOCK_DLOG_SVK_PLANT.EraseBlock
        OIT_GetErrorStatus_PSProxy_NVM_BLOCK_DLOG_SVK_PLANT_GetErrorStatus: start-on-event=GetErrorStatus, operation=PSProxy_NVM_BLOCK_DLOG_SVK_PLANT.GetErrorStatus
        OIT_InvalidateNvBlock_PSProxy_NVM_BLOCK_DLOG_SVK_PLANT_InvalidateNvBlock: start-on-event=InvalidateNvBlock, operation=PSProxy_NVM_BLOCK_DLOG_SVK_PLANT.InvalidateNvBlock
        OIT_ReadBlock_PSProxy_NVM_BLOCK_DLOG_SVK_PLANT_ReadBlock: start-on-event=ReadBlock, operation=PSProxy_NVM_BLOCK_DLOG_SVK_PLANT.ReadBlock
        OIT_SetRamBlockStatus_PSProxy_NVM_BLOCK_DLOG_SVK_PLANT_SetRamBlockStatus: start-on-event=SetRamBlockStatus, operation=PSProxy_NVM_BLOCK_DLOG_SVK_PLANT.SetRamBlockStatus
        OIT_WriteBlock_PSProxy_NVM_BLOCK_DLOG_SVK_PLANT_WriteBlock: start-on-event=WriteBlock, operation=PSProxy_NVM_BLOCK_DLOG_SVK_PLANT.WriteBlock
        OIT_EraseBlock_PSProxy_Rte_NvmBlock_CDD_VrfyCritReg_MCalReadVrfyCritRegFltInfo_EraseBlock: start-on-event=EraseBlock, operation=PSProxy_Rte_NvmBlock_CDD_VrfyCritReg_MCalReadVrfyCritRegFltInfo.EraseBlock
        OIT_GetErrorStatus_PSProxy_Rte_NvmBlock_CDD_VrfyCritReg_MCalReadVrfyCritRegFltInfo_GetErrorStatus: start-on-event=GetErrorStatus, operation=PSProxy_Rte_NvmBlock_CDD_VrfyCritReg_MCalReadVrfyCritRegFltInfo.GetErrorStatus
        OIT_InvalidateNvBlock_PSProxy_Rte_NvmBlock_CDD_VrfyCritReg_MCalReadVrfyCritRegFltInfo_InvalidateNvBlock: start-on-event=InvalidateNvBlock, operation=PSProxy_Rte_NvmBlock_CDD_VrfyCritReg_MCalReadVrfyCritRegFltInfo.InvalidateNvBlock
        OIT_ReadBlock_PSProxy_Rte_NvmBlock_CDD_VrfyCritReg_MCalReadVrfyCritRegFltInfo_ReadBlock: start-on-event=ReadBlock, operation=PSProxy_Rte_NvmBlock_CDD_VrfyCritReg_MCalReadVrfyCritRegFltInfo.ReadBlock
        OIT_SetRamBlockStatus_PSProxy_Rte_NvmBlock_CDD_VrfyCritReg_MCalReadVrfyCritRegFltInfo_SetRamBlockStatus: start-on-event=SetRamBlockStatus, operation=PSProxy_Rte_NvmBlock_CDD_VrfyCritReg_MCalReadVrfyCritRegFltInfo.SetRamBlockStatus
        OIT_WriteBlock_PSProxy_Rte_NvmBlock_CDD_VrfyCritReg_MCalReadVrfyCritRegFltInfo_WriteBlock: start-on-event=WriteBlock, operation=PSProxy_Rte_NvmBlock_CDD_VrfyCritReg_MCalReadVrfyCritRegFltInfo.WriteBlock
        OIT_EraseBlock_PSProxy_Rte_NvmBlock_BmwHwAgArbnAndEotPosn_BmwVehCentrOffs_EraseBlock: start-on-event=EraseBlock, operation=PSProxy_Rte_NvmBlock_BmwHwAgArbnAndEotPosn_BmwVehCentrOffs.EraseBlock
        OIT_GetErrorStatus_PSProxy_Rte_NvmBlock_BmwHwAgArbnAndEotPosn_BmwVehCentrOffs_GetErrorStatus: start-on-event=GetErrorStatus, operation=PSProxy_Rte_NvmBlock_BmwHwAgArbnAndEotPosn_BmwVehCentrOffs.GetErrorStatus
        OIT_InvalidateNvBlock_PSProxy_Rte_NvmBlock_BmwHwAgArbnAndEotPosn_BmwVehCentrOffs_InvalidateNvBlock: start-on-event=InvalidateNvBlock, operation=PSProxy_Rte_NvmBlock_BmwHwAgArbnAndEotPosn_BmwVehCentrOffs.InvalidateNvBlock
        OIT_ReadBlock_PSProxy_Rte_NvmBlock_BmwHwAgArbnAndEotPosn_BmwVehCentrOffs_ReadBlock: start-on-event=ReadBlock, operation=PSProxy_Rte_NvmBlock_BmwHwAgArbnAndEotPosn_BmwVehCentrOffs.ReadBlock
        OIT_SetRamBlockStatus_PSProxy_Rte_NvmBlock_BmwHwAgArbnAndEotPosn_BmwVehCentrOffs_SetRamBlockStatus: start-on-event=SetRamBlockStatus, operation=PSProxy_Rte_NvmBlock_BmwHwAgArbnAndEotPosn_BmwVehCentrOffs.SetRamBlockStatus
        OIT_WriteBlock_PSProxy_Rte_NvmBlock_BmwHwAgArbnAndEotPosn_BmwVehCentrOffs_WriteBlock: start-on-event=WriteBlock, operation=PSProxy_Rte_NvmBlock_BmwHwAgArbnAndEotPosn_BmwVehCentrOffs.WriteBlock
        OIT_EraseBlock_PSProxy_Rte_NvmBlock_LrndRackCentr_LrndRackCentr_EraseBlock: start-on-event=EraseBlock, operation=PSProxy_Rte_NvmBlock_LrndRackCentr_LrndRackCentr.EraseBlock
        OIT_GetErrorStatus_PSProxy_Rte_NvmBlock_LrndRackCentr_LrndRackCentr_GetErrorStatus: start-on-event=GetErrorStatus, operation=PSProxy_Rte_NvmBlock_LrndRackCentr_LrndRackCentr.GetErrorStatus
        OIT_InvalidateNvBlock_PSProxy_Rte_NvmBlock_LrndRackCentr_LrndRackCentr_InvalidateNvBlock: start-on-event=InvalidateNvBlock, operation=PSProxy_Rte_NvmBlock_LrndRackCentr_LrndRackCentr.InvalidateNvBlock
        OIT_ReadBlock_PSProxy_Rte_NvmBlock_LrndRackCentr_LrndRackCentr_ReadBlock: start-on-event=ReadBlock, operation=PSProxy_Rte_NvmBlock_LrndRackCentr_LrndRackCentr.ReadBlock
        OIT_SetRamBlockStatus_PSProxy_Rte_NvmBlock_LrndRackCentr_LrndRackCentr_SetRamBlockStatus: start-on-event=SetRamBlockStatus, operation=PSProxy_Rte_NvmBlock_LrndRackCentr_LrndRackCentr.SetRamBlockStatus
        OIT_WriteBlock_PSProxy_Rte_NvmBlock_LrndRackCentr_LrndRackCentr_WriteBlock: start-on-event=WriteBlock, operation=PSProxy_Rte_NvmBlock_LrndRackCentr_LrndRackCentr.WriteBlock
        OIT_EraseBlock_PSProxy_Rte_NvmBlock_TEstimn_TFilStVal_EraseBlock: start-on-event=EraseBlock, operation=PSProxy_Rte_NvmBlock_TEstimn_TFilStVal.EraseBlock
        OIT_GetErrorStatus_PSProxy_Rte_NvmBlock_TEstimn_TFilStVal_GetErrorStatus: start-on-event=GetErrorStatus, operation=PSProxy_Rte_NvmBlock_TEstimn_TFilStVal.GetErrorStatus
        OIT_InvalidateNvBlock_PSProxy_Rte_NvmBlock_TEstimn_TFilStVal_InvalidateNvBlock: start-on-event=InvalidateNvBlock, operation=PSProxy_Rte_NvmBlock_TEstimn_TFilStVal.InvalidateNvBlock
        OIT_ReadBlock_PSProxy_Rte_NvmBlock_TEstimn_TFilStVal_ReadBlock: start-on-event=ReadBlock, operation=PSProxy_Rte_NvmBlock_TEstimn_TFilStVal.ReadBlock
        OIT_SetRamBlockStatus_PSProxy_Rte_NvmBlock_TEstimn_TFilStVal_SetRamBlockStatus: start-on-event=SetRamBlockStatus, operation=PSProxy_Rte_NvmBlock_TEstimn_TFilStVal.SetRamBlockStatus
        OIT_WriteBlock_PSProxy_Rte_NvmBlock_TEstimn_TFilStVal_WriteBlock: start-on-event=WriteBlock, operation=PSProxy_Rte_NvmBlock_TEstimn_TFilStVal.WriteBlock
        OIT_EraseBlock_PSProxy_Rte_NvmBlock_Darh_DiagnoseMasterEnable_EraseBlock: start-on-event=EraseBlock, operation=PSProxy_Rte_NvmBlock_Darh_DiagnoseMasterEnable.EraseBlock
        OIT_GetErrorStatus_PSProxy_Rte_NvmBlock_Darh_DiagnoseMasterEnable_GetErrorStatus: start-on-event=GetErrorStatus, operation=PSProxy_Rte_NvmBlock_Darh_DiagnoseMasterEnable.GetErrorStatus
        OIT_InvalidateNvBlock_PSProxy_Rte_NvmBlock_Darh_DiagnoseMasterEnable_InvalidateNvBlock: start-on-event=InvalidateNvBlock, operation=PSProxy_Rte_NvmBlock_Darh_DiagnoseMasterEnable.InvalidateNvBlock
        OIT_ReadBlock_PSProxy_Rte_NvmBlock_Darh_DiagnoseMasterEnable_ReadBlock: start-on-event=ReadBlock, operation=PSProxy_Rte_NvmBlock_Darh_DiagnoseMasterEnable.ReadBlock
        OIT_SetRamBlockStatus_PSProxy_Rte_NvmBlock_Darh_DiagnoseMasterEnable_SetRamBlockStatus: start-on-event=SetRamBlockStatus, operation=PSProxy_Rte_NvmBlock_Darh_DiagnoseMasterEnable.SetRamBlockStatus
        OIT_WriteBlock_PSProxy_Rte_NvmBlock_Darh_DiagnoseMasterEnable_WriteBlock: start-on-event=WriteBlock, operation=PSProxy_Rte_NvmBlock_Darh_DiagnoseMasterEnable.WriteBlock
        OIT_EraseBlock_PSProxy_Rte_NvmBlock_BmwDiagcSrvHndlg_MilesKmEeprom_EraseBlock: start-on-event=EraseBlock, operation=PSProxy_Rte_NvmBlock_BmwDiagcSrvHndlg_MilesKmEeprom.EraseBlock
        OIT_GetErrorStatus_PSProxy_Rte_NvmBlock_BmwDiagcSrvHndlg_MilesKmEeprom_GetErrorStatus: start-on-event=GetErrorStatus, operation=PSProxy_Rte_NvmBlock_BmwDiagcSrvHndlg_MilesKmEeprom.GetErrorStatus
        OIT_InvalidateNvBlock_PSProxy_Rte_NvmBlock_BmwDiagcSrvHndlg_MilesKmEeprom_InvalidateNvBlock: start-on-event=InvalidateNvBlock, operation=PSProxy_Rte_NvmBlock_BmwDiagcSrvHndlg_MilesKmEeprom.InvalidateNvBlock
        OIT_ReadBlock_PSProxy_Rte_NvmBlock_BmwDiagcSrvHndlg_MilesKmEeprom_ReadBlock: start-on-event=ReadBlock, operation=PSProxy_Rte_NvmBlock_BmwDiagcSrvHndlg_MilesKmEeprom.ReadBlock
        OIT_SetRamBlockStatus_PSProxy_Rte_NvmBlock_BmwDiagcSrvHndlg_MilesKmEeprom_SetRamBlockStatus: start-on-event=SetRamBlockStatus, operation=PSProxy_Rte_NvmBlock_BmwDiagcSrvHndlg_MilesKmEeprom.SetRamBlockStatus
        OIT_WriteBlock_PSProxy_Rte_NvmBlock_BmwDiagcSrvHndlg_MilesKmEeprom_WriteBlock: start-on-event=WriteBlock, operation=PSProxy_Rte_NvmBlock_BmwDiagcSrvHndlg_MilesKmEeprom.WriteBlock
        OIT_EraseBlock_PSProxy_Rte_NvmBlock_BmwDiagcSrvHndlg_ProgCntr_EraseBlock: start-on-event=EraseBlock, operation=PSProxy_Rte_NvmBlock_BmwDiagcSrvHndlg_ProgCntr.EraseBlock
        OIT_GetErrorStatus_PSProxy_Rte_NvmBlock_BmwDiagcSrvHndlg_ProgCntr_GetErrorStatus: start-on-event=GetErrorStatus, operation=PSProxy_Rte_NvmBlock_BmwDiagcSrvHndlg_ProgCntr.GetErrorStatus
        OIT_InvalidateNvBlock_PSProxy_Rte_NvmBlock_BmwDiagcSrvHndlg_ProgCntr_InvalidateNvBlock: start-on-event=InvalidateNvBlock, operation=PSProxy_Rte_NvmBlock_BmwDiagcSrvHndlg_ProgCntr.InvalidateNvBlock
        OIT_ReadBlock_PSProxy_Rte_NvmBlock_BmwDiagcSrvHndlg_ProgCntr_ReadBlock: start-on-event=ReadBlock, operation=PSProxy_Rte_NvmBlock_BmwDiagcSrvHndlg_ProgCntr.ReadBlock
        OIT_SetRamBlockStatus_PSProxy_Rte_NvmBlock_BmwDiagcSrvHndlg_ProgCntr_SetRamBlockStatus: start-on-event=SetRamBlockStatus, operation=PSProxy_Rte_NvmBlock_BmwDiagcSrvHndlg_ProgCntr.SetRamBlockStatus
        OIT_WriteBlock_PSProxy_Rte_NvmBlock_BmwDiagcSrvHndlg_ProgCntr_WriteBlock: start-on-event=WriteBlock, operation=PSProxy_Rte_NvmBlock_BmwDiagcSrvHndlg_ProgCntr.WriteBlock
        OIT_EraseBlock_PSProxy_Rte_NvmBlock_BmwDiagcSrvHndlg_TestStamp_EraseBlock: start-on-event=EraseBlock, operation=PSProxy_Rte_NvmBlock_BmwDiagcSrvHndlg_TestStamp.EraseBlock
        OIT_GetErrorStatus_PSProxy_Rte_NvmBlock_BmwDiagcSrvHndlg_TestStamp_GetErrorStatus: start-on-event=GetErrorStatus, operation=PSProxy_Rte_NvmBlock_BmwDiagcSrvHndlg_TestStamp.GetErrorStatus
        OIT_InvalidateNvBlock_PSProxy_Rte_NvmBlock_BmwDiagcSrvHndlg_TestStamp_InvalidateNvBlock: start-on-event=InvalidateNvBlock, operation=PSProxy_Rte_NvmBlock_BmwDiagcSrvHndlg_TestStamp.InvalidateNvBlock
        OIT_ReadBlock_PSProxy_Rte_NvmBlock_BmwDiagcSrvHndlg_TestStamp_ReadBlock: start-on-event=ReadBlock, operation=PSProxy_Rte_NvmBlock_BmwDiagcSrvHndlg_TestStamp.ReadBlock
        OIT_SetRamBlockStatus_PSProxy_Rte_NvmBlock_BmwDiagcSrvHndlg_TestStamp_SetRamBlockStatus: start-on-event=SetRamBlockStatus, operation=PSProxy_Rte_NvmBlock_BmwDiagcSrvHndlg_TestStamp.SetRamBlockStatus
        OIT_WriteBlock_PSProxy_Rte_NvmBlock_BmwDiagcSrvHndlg_TestStamp_WriteBlock: start-on-event=WriteBlock, operation=PSProxy_Rte_NvmBlock_BmwDiagcSrvHndlg_TestStamp.WriteBlock
        OIT_SetBlockProtection_PAdminProxy_Rte_NvmBlock_CDD_NvMProxy_ShtdwnClsChk_SetBlockProtection: start-on-event=SetBlockProtection, operation=PAdminProxy_Rte_NvmBlock_CDD_NvMProxy_ShtdwnClsChk.SetBlockProtection
        OIT_SetBlockProtection_PAdminProxy_Rte_NvmBlock_DiagcMgr_DiagcMgrApplCrc_SetBlockProtection: start-on-event=SetBlockProtection, operation=PAdminProxy_Rte_NvmBlock_DiagcMgr_DiagcMgrApplCrc.SetBlockProtection
        OIT_SetBlockProtection_PAdminProxy_Rte_NvmBlock_DiagcMgr_DiagcMgrNtcFltAry_SetBlockProtection: start-on-event=SetBlockProtection, operation=PAdminProxy_Rte_NvmBlock_DiagcMgr_DiagcMgrNtcFltAry.SetBlockProtection
        OIT_SetBlockProtection_PAdminProxy_Rte_NvmBlock_DiagcMgr_DiagcMgrLtchCntrAry_SetBlockProtection: start-on-event=SetBlockProtection, operation=PAdminProxy_Rte_NvmBlock_DiagcMgr_DiagcMgrLtchCntrAry.SetBlockProtection
        OIT_SetBlockProtection_PAdminProxy_Rte_NvmBlock_CDD_MotAg0Meas_MotAg0CoeffTbl_SetBlockProtection: start-on-event=SetBlockProtection, operation=PAdminProxy_Rte_NvmBlock_CDD_MotAg0Meas_MotAg0CoeffTbl.SetBlockProtection
        OIT_SetBlockProtection_PAdminProxy_Rte_NvmBlock_CDD_MotAg1Meas_MotAg1CoeffTbl_SetBlockProtection: start-on-event=SetBlockProtection, operation=PAdminProxy_Rte_NvmBlock_CDD_MotAg1Meas_MotAg1CoeffTbl.SetBlockProtection
        OIT_SetBlockProtection_PAdminProxy_Rte_NvmBlock_CDD_CurrMeas_CurrMeasEolGainCalSetABC_SetBlockProtection: start-on-event=SetBlockProtection, operation=PAdminProxy_Rte_NvmBlock_CDD_CurrMeas_CurrMeasEolGainCalSetABC.SetBlockProtection
        OIT_SetBlockProtection_PAdminProxy_Rte_NvmBlock_CDD_CurrMeas_CurrMeasEolOffsCalSetABC_SetBlockProtection: start-on-event=SetBlockProtection, operation=PAdminProxy_Rte_NvmBlock_CDD_CurrMeas_CurrMeasEolOffsCalSetABC.SetBlockProtection
        OIT_SetBlockProtection_PAdminProxy_Rte_NvmBlock_CmnMfgSrv_CcaHwPartNr_SetBlockProtection: start-on-event=SetBlockProtection, operation=PAdminProxy_Rte_NvmBlock_CmnMfgSrv_CcaHwPartNr.SetBlockProtection
        OIT_SetBlockProtection_PAdminProxy_Rte_NvmBlock_CmnMfgSrv_CcaSerlNr_SetBlockProtection: start-on-event=SetBlockProtection, operation=PAdminProxy_Rte_NvmBlock_CmnMfgSrv_CcaSerlNr.SetBlockProtection
        OIT_SetBlockProtection_PAdminProxy_Rte_NvmBlock_CmnMfgSrv_DiRestore_SetBlockProtection: start-on-event=SetBlockProtection, operation=PAdminProxy_Rte_NvmBlock_CmnMfgSrv_DiRestore.SetBlockProtection
        OIT_SetBlockProtection_PAdminProxy_Rte_NvmBlock_CmnMfgSrv_EpsSysSerlNr_SetBlockProtection: start-on-event=SetBlockProtection, operation=PAdminProxy_Rte_NvmBlock_CmnMfgSrv_EpsSysSerlNr.SetBlockProtection
        OIT_SetBlockProtection_PAdminProxy_Rte_NvmBlock_CmnMfgSrv_IgnCntr_SetBlockProtection: start-on-event=SetBlockProtection, operation=PAdminProxy_Rte_NvmBlock_CmnMfgSrv_IgnCntr.SetBlockProtection
        OIT_SetBlockProtection_PAdminProxy_Rte_NvmBlock_CmnMfgSrv_NxtrMfgEnaCntr_SetBlockProtection: start-on-event=SetBlockProtection, operation=PAdminProxy_Rte_NvmBlock_CmnMfgSrv_NxtrMfgEnaCntr.SetBlockProtection
        OIT_SetBlockProtection_PAdminProxy_Rte_NvmBlock_CmnMfgSrv_MfgTmpBuf{0..4}_SetBlockProtection: start-on-event=SetBlockProtection, operation=PAdminProxy_Rte_NvmBlock_CmnMfgSrv_MfgTmpBuf{0..4}.SetBlockProtection
        OIT_SetBlockProtection_PAdminProxy_Rte_NvmBlock_CmnMfgSrv_SeedKey_SetBlockProtection: start-on-event=SetBlockProtection, operation=PAdminProxy_Rte_NvmBlock_CmnMfgSrv_SeedKey.SetBlockProtection
        OIT_SetBlockProtection_PAdminProxy_Rte_NvmBlock_PolarityCfg_PolarityCfgSaved_SetBlockProtection: start-on-event=SetBlockProtection, operation=PAdminProxy_Rte_NvmBlock_PolarityCfg_PolarityCfgSaved.SetBlockProtection
        OIT_SetBlockProtection_PAdminProxy_Rte_NvmBlock_CDD_MotAgCmp_MotAgCmpMotAgBackEmf_SetBlockProtection: start-on-event=SetBlockProtection, operation=PAdminProxy_Rte_NvmBlock_CDD_MotAgCmp_MotAgCmpMotAgBackEmf.SetBlockProtection
        OIT_SetBlockProtection_PAdminProxy_Rte_NvmBlock_CDD_HwTq4Meas_HwTq4Offs_MirrorBlock_SetBlockProtection: start-on-event=SetBlockProtection, operation=PAdminProxy_Rte_NvmBlock_CDD_HwTq4Meas_HwTq4Offs_MirrorBlock.SetBlockProtection
        OIT_SetBlockProtection_PAdminProxy_Rte_NvmBlock_CDD_HwTq5Meas_HwTq5Offs_MirrorBlock_SetBlockProtection: start-on-event=SetBlockProtection, operation=PAdminProxy_Rte_NvmBlock_CDD_HwTq5Meas_HwTq5Offs_MirrorBlock.SetBlockProtection
        OIT_SetBlockProtection_PAdminProxy_Rte_NvmBlock_CDD_HwTq4Meas_HwTq4Sca_MirrorBlock_SetBlockProtection: start-on-event=SetBlockProtection, operation=PAdminProxy_Rte_NvmBlock_CDD_HwTq4Meas_HwTq4Sca_MirrorBlock.SetBlockProtection
        OIT_SetBlockProtection_PAdminProxy_Rte_NvmBlock_CDD_HwTq5Meas_HwTq5Sca_MirrorBlock_SetBlockProtection: start-on-event=SetBlockProtection, operation=PAdminProxy_Rte_NvmBlock_CDD_HwTq5Meas_HwTq5Sca_MirrorBlock.SetBlockProtection
        OIT_SetBlockProtection_PAdminProxy_Rte_NvmBlock_HwTqCorrln_HwTqChACmnModCmpLpFilSt_SetBlockProtection: start-on-event=SetBlockProtection, operation=PAdminProxy_Rte_NvmBlock_HwTqCorrln_HwTqChACmnModCmpLpFilSt.SetBlockProtection
        OIT_SetBlockProtection_PAdminProxy_Rte_NvmBlock_DutyCycThermProtn_FilStVal_SetBlockProtection: start-on-event=SetBlockProtection, operation=PAdminProxy_Rte_NvmBlock_DutyCycThermProtn_FilStVal.SetBlockProtection
        OIT_SetBlockProtection_PAdminProxy_Rte_NvmBlock_MotTqCmdSca_MotTqScaFac_SetBlockProtection: start-on-event=SetBlockProtection, operation=PAdminProxy_Rte_NvmBlock_MotTqCmdSca_MotTqScaFac.SetBlockProtection
        OIT_SetBlockProtection_PAdminProxy_Rte_NvmBlock_MotCtrlPrmEstimn_MotPrmNom_SetBlockProtection: start-on-event=SetBlockProtection, operation=PAdminProxy_Rte_NvmBlock_MotCtrlPrmEstimn_MotPrmNom.SetBlockProtection
        OIT_SetBlockProtection_PAdminProxy_Rte_NvmBlock_Vin_SetBlockProtection: start-on-event=SetBlockProtection, operation=PAdminProxy_Rte_NvmBlock_Vin.SetBlockProtection
        OIT_SetBlockProtection_PAdminProxy_Rte_NvmBlock_Omc_SetBlockProtection: start-on-event=SetBlockProtection, operation=PAdminProxy_Rte_NvmBlock_Omc.SetBlockProtection
        OIT_SetBlockProtection_PAdminProxy_NVM_BLOCK_BOOT_PROG_COUNTER_SetBlockProtection: start-on-event=SetBlockProtection, operation=PAdminProxy_NVM_BLOCK_BOOT_PROG_COUNTER.SetBlockProtection
        OIT_SetBlockProtection_PAdminProxy_NVM_BLOCK_BOOT_PROG_DATA_SetBlockProtection: start-on-event=SetBlockProtection, operation=PAdminProxy_NVM_BLOCK_BOOT_PROG_DATA.SetBlockProtection
        OIT_SetBlockProtection_PAdminProxy_NVM_BLOCK_BOOT_SVK_HISTORY_SetBlockProtection: start-on-event=SetBlockProtection, operation=PAdminProxy_NVM_BLOCK_BOOT_SVK_HISTORY.SetBlockProtection
        OIT_SetBlockProtection_PAdminProxy_NVM_BLOCK_DLOG_SVK_SYS_SUPP_SetBlockProtection: start-on-event=SetBlockProtection, operation=PAdminProxy_NVM_BLOCK_DLOG_SVK_SYS_SUPP.SetBlockProtection
        OIT_SetBlockProtection_PAdminProxy_NVM_BLOCK_DLOG_SVK_PLANT_SetBlockProtection: start-on-event=SetBlockProtection, operation=PAdminProxy_NVM_BLOCK_DLOG_SVK_PLANT.SetBlockProtection
        OIT_SetBlockProtection_PAdminProxy_Rte_NvmBlock_Darh_ErrorQueue_SetBlockProtection: start-on-event=SetBlockProtection, operation=PAdminProxy_Rte_NvmBlock_Darh_ErrorQueue.SetBlockProtection
        OIT_SetBlockProtection_PAdminProxy_Rte_NvmBlock_CDD_VrfyCritReg_MCalReadVrfyCritRegFltInfo_SetBlockProtection: start-on-event=SetBlockProtection, operation=PAdminProxy_Rte_NvmBlock_CDD_VrfyCritReg_MCalReadVrfyCritRegFltInfo.SetBlockProtection
        OIT_SetBlockProtection_PAdminProxy_Rte_NvmBlock_BmwHwAgArbnAndEotPosn_BmwVehCentrOffs_SetBlockProtection: start-on-event=SetBlockProtection, operation=PAdminProxy_Rte_NvmBlock_BmwHwAgArbnAndEotPosn_BmwVehCentrOffs.SetBlockProtection
        OIT_SetBlockProtection_PAdminProxy_Rte_NvmBlock_LrndRackCentr_LrndRackCentr_SetBlockProtection: start-on-event=SetBlockProtection, operation=PAdminProxy_Rte_NvmBlock_LrndRackCentr_LrndRackCentr.SetBlockProtection
        OIT_SetBlockProtection_PAdminProxy_Rte_NvmBlock_ExcpnHndlg_McuDiagcData_SetBlockProtection: start-on-event=SetBlockProtection, operation=PAdminProxy_Rte_NvmBlock_ExcpnHndlg_McuDiagcData.SetBlockProtection
        OIT_SetBlockProtection_PAdminProxy_Rte_NvmBlock_TEstimn_TFilStVal_SetBlockProtection: start-on-event=SetBlockProtection, operation=PAdminProxy_Rte_NvmBlock_TEstimn_TFilStVal.SetBlockProtection
        OIT_SetBlockProtection_PAdminProxy_NVM_BLOCK_DLOG_SVK_ENTRY_SetBlockProtection: start-on-event=SetBlockProtection, operation=PAdminProxy_NVM_BLOCK_DLOG_SVK_ENTRY.SetBlockProtection
        OIT_SetBlockProtection_PAdminProxy_Rte_NvmBlock_Darh_DiagnoseMasterEnable_SetBlockProtection: start-on-event=SetBlockProtection, operation=PAdminProxy_Rte_NvmBlock_Darh_DiagnoseMasterEnable.SetBlockProtection
        OIT_SetBlockProtection_PAdminProxy_Rte_NvmBlock_Coding_CodingData_SetBlockProtection: start-on-event=SetBlockProtection, operation=PAdminProxy_Rte_NvmBlock_Coding_CodingData.SetBlockProtection
        OIT_SetBlockProtection_PAdminProxy_Rte_NvmBlock_BmwTunSetHndlr_BmwDesIninIdx_SetBlockProtection: start-on-event=SetBlockProtection, operation=PAdminProxy_Rte_NvmBlock_BmwTunSetHndlr_BmwDesIninIdx.SetBlockProtection
        OIT_SetBlockProtection_PAdminProxy_Rte_NvmBlock_BmwTunSetHndlr_NvmBmwDesIninOptSetAIdx_SetBlockProtection: start-on-event=SetBlockProtection, operation=PAdminProxy_Rte_NvmBlock_BmwTunSetHndlr_NvmBmwDesIninOptSetAIdx.SetBlockProtection
        OIT_SetBlockProtection_PAdminProxy_Rte_NvmBlock_BmwDiagcSrvHndlg_MilesKmEeprom_SetBlockProtection: start-on-event=SetBlockProtection, operation=PAdminProxy_Rte_NvmBlock_BmwDiagcSrvHndlg_MilesKmEeprom.SetBlockProtection
        OIT_SetBlockProtection_PAdminProxy_Rte_NvmBlock_BmwDiagcSrvHndlg_ProgCntr_SetBlockProtection: start-on-event=SetBlockProtection, operation=PAdminProxy_Rte_NvmBlock_BmwDiagcSrvHndlg_ProgCntr.SetBlockProtection
        OIT_SetBlockProtection_PAdminProxy_Rte_NvmBlock_BmwDiagcSrvHndlg_ProgCntrMaxVal_SetBlockProtection: start-on-event=SetBlockProtection, operation=PAdminProxy_Rte_NvmBlock_BmwDiagcSrvHndlg_ProgCntrMaxVal.SetBlockProtection
        OIT_SetBlockProtection_PAdminProxy_Rte_NvmBlock_BmwDiagcSrvHndlg_TestStamp_SetBlockProtection: start-on-event=SetBlockProtection, operation=PAdminProxy_Rte_NvmBlock_BmwDiagcSrvHndlg_TestStamp.SetBlockProtection
        OIT_SetBlockProtection_PAdminProxy_Rte_NvmBlock_PullCmpActv_PullCmpLongTerm_SetBlockProtection: start-on-event=SetBlockProtection, operation=PAdminProxy_Rte_NvmBlock_PullCmpActv_PullCmpLongTerm.SetBlockProtection
      port-api-options:
        {enable-take-address=true, indirect-api=false, port-defined-argument-value{value=PAdminProxy_Rte_NvmBlock_CDD_NvMProxy_ShtdwnClsChk_0:58, value-type=NvM_BlockIdType}, port=PAdminProxy_Rte_NvmBlock_CDD_NvMProxy_ShtdwnClsChk}
        {enable-take-address=false, indirect-api=false, port-defined-argument-value{value=PSProxy_Rte_NvmBlock_CDD_NvMProxy_ShtdwnClsChk_0:58, value-type=NvM_BlockIdType}, port=PSProxy_Rte_NvmBlock_CDD_NvMProxy_ShtdwnClsChk}
        {enable-take-address=true, indirect-api=false, port-defined-argument-value{value=PAdminProxy_Rte_NvmBlock_DiagcMgr_DiagcMgrApplCrc_0:55, value-type=NvM_BlockIdType}, port=PAdminProxy_Rte_NvmBlock_DiagcMgr_DiagcMgrApplCrc}
        {enable-take-address=false, indirect-api=false, port-defined-argument-value{value=PSProxy_Rte_NvmBlock_DiagcMgr_DiagcMgrApplCrc_0:55, value-type=NvM_BlockIdType}, port=PSProxy_Rte_NvmBlock_DiagcMgr_DiagcMgrApplCrc}
        {enable-take-address=true, indirect-api=false, port-defined-argument-value{value=PAdminProxy_Rte_NvmBlock_DiagcMgr_DiagcMgrNtcFltAry_0:56, value-type=NvM_BlockIdType}, port=PAdminProxy_Rte_NvmBlock_DiagcMgr_DiagcMgrNtcFltAry}
        {enable-take-address=false, indirect-api=false, port-defined-argument-value{value=PSProxy_Rte_NvmBlock_DiagcMgr_DiagcMgrNtcFltAry_0:56, value-type=NvM_BlockIdType}, port=PSProxy_Rte_NvmBlock_DiagcMgr_DiagcMgrNtcFltAry}
        {enable-take-address=true, indirect-api=false, port-defined-argument-value{value=PAdminProxy_Rte_NvmBlock_DiagcMgr_DiagcMgrLtchCntrAry_0:57, value-type=NvM_BlockIdType}, port=PAdminProxy_Rte_NvmBlock_DiagcMgr_DiagcMgrLtchCntrAry}
        {enable-take-address=false, indirect-api=false, port-defined-argument-value{value=PSProxy_Rte_NvmBlock_DiagcMgr_DiagcMgrLtchCntrAry_0:57, value-type=NvM_BlockIdType}, port=PSProxy_Rte_NvmBlock_DiagcMgr_DiagcMgrLtchCntrAry}
        {enable-take-address=true, indirect-api=false, port-defined-argument-value{value=PAdminProxy_Rte_NvmBlock_CDD_MotAg0Meas_MotAg0CoeffTbl_0:54, value-type=NvM_BlockIdType}, port=PAdminProxy_Rte_NvmBlock_CDD_MotAg0Meas_MotAg0CoeffTbl}
        {enable-take-address=false, indirect-api=false, port-defined-argument-value{value=PSProxy_Rte_NvmBlock_CDD_MotAg0Meas_MotAg0CoeffTbl_0:54, value-type=NvM_BlockIdType}, port=PSProxy_Rte_NvmBlock_CDD_MotAg0Meas_MotAg0CoeffTbl}
        {enable-take-address=true, indirect-api=false, port-defined-argument-value{value=PAdminProxy_Rte_NvmBlock_CDD_MotAg1Meas_MotAg1CoeffTbl_0:53, value-type=NvM_BlockIdType}, port=PAdminProxy_Rte_NvmBlock_CDD_MotAg1Meas_MotAg1CoeffTbl}
        {enable-take-address=false, indirect-api=false, port-defined-argument-value{value=PSProxy_Rte_NvmBlock_CDD_MotAg1Meas_MotAg1CoeffTbl_0:53, value-type=NvM_BlockIdType}, port=PSProxy_Rte_NvmBlock_CDD_MotAg1Meas_MotAg1CoeffTbl}
        {enable-take-address=true, indirect-api=false, port-defined-argument-value{value=PAdminProxy_Rte_NvmBlock_CDD_CurrMeas_CurrMeasEolGainCalSetABC_0:52, value-type=NvM_BlockIdType}, port=PAdminProxy_Rte_NvmBlock_CDD_CurrMeas_CurrMeasEolGainCalSetABC}
        {enable-take-address=false, indirect-api=false, port-defined-argument-value{value=PSProxy_Rte_NvmBlock_CDD_CurrMeas_CurrMeasEolGainCalSetABC_0:52, value-type=NvM_BlockIdType}, port=PSProxy_Rte_NvmBlock_CDD_CurrMeas_CurrMeasEolGainCalSetABC}
        {enable-take-address=true, indirect-api=false, port-defined-argument-value{value=PAdminProxy_Rte_NvmBlock_CDD_CurrMeas_CurrMeasEolOffsCalSetABC_0:51, value-type=NvM_BlockIdType}, port=PAdminProxy_Rte_NvmBlock_CDD_CurrMeas_CurrMeasEolOffsCalSetABC}
        {enable-take-address=false, indirect-api=false, port-defined-argument-value{value=PSProxy_Rte_NvmBlock_CDD_CurrMeas_CurrMeasEolOffsCalSetABC_0:51, value-type=NvM_BlockIdType}, port=PSProxy_Rte_NvmBlock_CDD_CurrMeas_CurrMeasEolOffsCalSetABC}
        {enable-take-address=true, indirect-api=false, port-defined-argument-value{value=PAdminProxy_Rte_NvmBlock_CmnMfgSrv_CcaHwPartNr_0:49, value-type=NvM_BlockIdType}, port=PAdminProxy_Rte_NvmBlock_CmnMfgSrv_CcaHwPartNr}
        {enable-take-address=false, indirect-api=false, port-defined-argument-value{value=PSProxy_Rte_NvmBlock_CmnMfgSrv_CcaHwPartNr_0:49, value-type=NvM_BlockIdType}, port=PSProxy_Rte_NvmBlock_CmnMfgSrv_CcaHwPartNr}
        {enable-take-address=true, indirect-api=false, port-defined-argument-value{value=PAdminProxy_Rte_NvmBlock_CmnMfgSrv_CcaSerlNr_0:48, value-type=NvM_BlockIdType}, port=PAdminProxy_Rte_NvmBlock_CmnMfgSrv_CcaSerlNr}
        {enable-take-address=false, indirect-api=false, port-defined-argument-value{value=PSProxy_Rte_NvmBlock_CmnMfgSrv_CcaSerlNr_0:48, value-type=NvM_BlockIdType}, port=PSProxy_Rte_NvmBlock_CmnMfgSrv_CcaSerlNr}
        {enable-take-address=true, indirect-api=false, port-defined-argument-value{value=PAdminProxy_Rte_NvmBlock_CmnMfgSrv_DiRestore_0:47, value-type=NvM_BlockIdType}, port=PAdminProxy_Rte_NvmBlock_CmnMfgSrv_DiRestore}
        {enable-take-address=false, indirect-api=false, port-defined-argument-value{value=PSProxy_Rte_NvmBlock_CmnMfgSrv_DiRestore_0:47, value-type=NvM_BlockIdType}, port=PSProxy_Rte_NvmBlock_CmnMfgSrv_DiRestore}
        {enable-take-address=true, indirect-api=false, port-defined-argument-value{value=PAdminProxy_Rte_NvmBlock_CmnMfgSrv_EpsSysSerlNr_0:46, value-type=NvM_BlockIdType}, port=PAdminProxy_Rte_NvmBlock_CmnMfgSrv_EpsSysSerlNr}
        {enable-take-address=false, indirect-api=false, port-defined-argument-value{value=PSProxy_Rte_NvmBlock_CmnMfgSrv_EpsSysSerlNr_0:46, value-type=NvM_BlockIdType}, port=PSProxy_Rte_NvmBlock_CmnMfgSrv_EpsSysSerlNr}
        {enable-take-address=true, indirect-api=false, port-defined-argument-value{value=PAdminProxy_Rte_NvmBlock_CmnMfgSrv_IgnCntr_0:45, value-type=NvM_BlockIdType}, port=PAdminProxy_Rte_NvmBlock_CmnMfgSrv_IgnCntr}
        {enable-take-address=false, indirect-api=false, port-defined-argument-value{value=PSProxy_Rte_NvmBlock_CmnMfgSrv_IgnCntr_0:45, value-type=NvM_BlockIdType}, port=PSProxy_Rte_NvmBlock_CmnMfgSrv_IgnCntr}
        {enable-take-address=true, indirect-api=false, port-defined-argument-value{value=PAdminProxy_Rte_NvmBlock_CmnMfgSrv_NxtrMfgEnaCntr_0:44, value-type=NvM_BlockIdType}, port=PAdminProxy_Rte_NvmBlock_CmnMfgSrv_NxtrMfgEnaCntr}
        {enable-take-address=false, indirect-api=false, port-defined-argument-value{value=PSProxy_Rte_NvmBlock_CmnMfgSrv_NxtrMfgEnaCntr_0:44, value-type=NvM_BlockIdType}, port=PSProxy_Rte_NvmBlock_CmnMfgSrv_NxtrMfgEnaCntr}
        {enable-take-address=true, indirect-api=false, port-defined-argument-value{value=PAdminProxy_Rte_NvmBlock_CmnMfgSrv_MfgTmpBuf0_0:43, value-type=NvM_BlockIdType}, port=PAdminProxy_Rte_NvmBlock_CmnMfgSrv_MfgTmpBuf0}
        {enable-take-address=false, indirect-api=false, port-defined-argument-value{value=PSProxy_Rte_NvmBlock_CmnMfgSrv_MfgTmpBuf0_0:43, value-type=NvM_BlockIdType}, port=PSProxy_Rte_NvmBlock_CmnMfgSrv_MfgTmpBuf0}
        {enable-take-address=true, indirect-api=false, port-defined-argument-value{value=PAdminProxy_Rte_NvmBlock_CmnMfgSrv_MfgTmpBuf1_0:42, value-type=NvM_BlockIdType}, port=PAdminProxy_Rte_NvmBlock_CmnMfgSrv_MfgTmpBuf1}
        {enable-take-address=false, indirect-api=false, port-defined-argument-value{value=PSProxy_Rte_NvmBlock_CmnMfgSrv_MfgTmpBuf1_0:42, value-type=NvM_BlockIdType}, port=PSProxy_Rte_NvmBlock_CmnMfgSrv_MfgTmpBuf1}
        {enable-take-address=true, indirect-api=false, port-defined-argument-value{value=PAdminProxy_Rte_NvmBlock_CmnMfgSrv_MfgTmpBuf2_0:41, value-type=NvM_BlockIdType}, port=PAdminProxy_Rte_NvmBlock_CmnMfgSrv_MfgTmpBuf2}
        {enable-take-address=false, indirect-api=false, port-defined-argument-value{value=PSProxy_Rte_NvmBlock_CmnMfgSrv_MfgTmpBuf2_0:41, value-type=NvM_BlockIdType}, port=PSProxy_Rte_NvmBlock_CmnMfgSrv_MfgTmpBuf2}
        {enable-take-address=true, indirect-api=false, port-defined-argument-value{value=PAdminProxy_Rte_NvmBlock_CmnMfgSrv_MfgTmpBuf3_0:40, value-type=NvM_BlockIdType}, port=PAdminProxy_Rte_NvmBlock_CmnMfgSrv_MfgTmpBuf3}
        {enable-take-address=false, indirect-api=false, port-defined-argument-value{value=PSProxy_Rte_NvmBlock_CmnMfgSrv_MfgTmpBuf3_0:40, value-type=NvM_BlockIdType}, port=PSProxy_Rte_NvmBlock_CmnMfgSrv_MfgTmpBuf3}
        {enable-take-address=true, indirect-api=false, port-defined-argument-value{value=PAdminProxy_Rte_NvmBlock_CmnMfgSrv_MfgTmpBuf4_0:39, value-type=NvM_BlockIdType}, port=PAdminProxy_Rte_NvmBlock_CmnMfgSrv_MfgTmpBuf4}
        {enable-take-address=false, indirect-api=false, port-defined-argument-value{value=PSProxy_Rte_NvmBlock_CmnMfgSrv_MfgTmpBuf4_0:39, value-type=NvM_BlockIdType}, port=PSProxy_Rte_NvmBlock_CmnMfgSrv_MfgTmpBuf4}
        {enable-take-address=true, indirect-api=false, port-defined-argument-value{value=PAdminProxy_Rte_NvmBlock_CmnMfgSrv_SeedKey_0:38, value-type=NvM_BlockIdType}, port=PAdminProxy_Rte_NvmBlock_CmnMfgSrv_SeedKey}
        {enable-take-address=false, indirect-api=false, port-defined-argument-value{value=PSProxy_Rte_NvmBlock_CmnMfgSrv_SeedKey_0:38, value-type=NvM_BlockIdType}, port=PSProxy_Rte_NvmBlock_CmnMfgSrv_SeedKey}
        {enable-take-address=true, indirect-api=false, port-defined-argument-value{value=PAdminProxy_Rte_NvmBlock_PolarityCfg_PolarityCfgSaved_0:37, value-type=NvM_BlockIdType}, port=PAdminProxy_Rte_NvmBlock_PolarityCfg_PolarityCfgSaved}
        {enable-take-address=false, indirect-api=false, port-defined-argument-value{value=PSProxy_Rte_NvmBlock_PolarityCfg_PolarityCfgSaved_0:37, value-type=NvM_BlockIdType}, port=PSProxy_Rte_NvmBlock_PolarityCfg_PolarityCfgSaved}
        {enable-take-address=true, indirect-api=false, port-defined-argument-value{value=PAdminProxy_Rte_NvmBlock_CDD_MotAgCmp_MotAgCmpMotAgBackEmf_0:36, value-type=NvM_BlockIdType}, port=PAdminProxy_Rte_NvmBlock_CDD_MotAgCmp_MotAgCmpMotAgBackEmf}
        {enable-take-address=false, indirect-api=false, port-defined-argument-value{value=PSProxy_Rte_NvmBlock_CDD_MotAgCmp_MotAgCmpMotAgBackEmf_0:36, value-type=NvM_BlockIdType}, port=PSProxy_Rte_NvmBlock_CDD_MotAgCmp_MotAgCmpMotAgBackEmf}
        {enable-take-address=true, indirect-api=false, port-defined-argument-value{value=PAdminProxy_Rte_NvmBlock_CDD_HwTq4Meas_HwTq4Offs_MirrorBlock_0:35, value-type=NvM_BlockIdType}, port=PAdminProxy_Rte_NvmBlock_CDD_HwTq4Meas_HwTq4Offs_MirrorBlock}
        {enable-take-address=false, indirect-api=false, port-defined-argument-value{value=PSProxy_Rte_NvmBlock_CDD_HwTq4Meas_HwTq4Offs_MirrorBlock_0:35, value-type=NvM_BlockIdType}, port=PSProxy_Rte_NvmBlock_CDD_HwTq4Meas_HwTq4Offs_MirrorBlock}
        {enable-take-address=true, indirect-api=false, port-defined-argument-value{value=PAdminProxy_Rte_NvmBlock_CDD_HwTq5Meas_HwTq5Offs_MirrorBlock_0:34, value-type=NvM_BlockIdType}, port=PAdminProxy_Rte_NvmBlock_CDD_HwTq5Meas_HwTq5Offs_MirrorBlock}
        {enable-take-address=false, indirect-api=false, port-defined-argument-value{value=PSProxy_Rte_NvmBlock_CDD_HwTq5Meas_HwTq5Offs_MirrorBlock_0:34, value-type=NvM_BlockIdType}, port=PSProxy_Rte_NvmBlock_CDD_HwTq5Meas_HwTq5Offs_MirrorBlock}
        {enable-take-address=true, indirect-api=false, port-defined-argument-value{value=PAdminProxy_Rte_NvmBlock_CDD_HwTq4Meas_HwTq4Sca_MirrorBlock_0:33, value-type=NvM_BlockIdType}, port=PAdminProxy_Rte_NvmBlock_CDD_HwTq4Meas_HwTq4Sca_MirrorBlock}
        {enable-take-address=false, indirect-api=false, port-defined-argument-value{value=PSProxy_Rte_NvmBlock_CDD_HwTq4Meas_HwTq4Sca_MirrorBlock_0:33, value-type=NvM_BlockIdType}, port=PSProxy_Rte_NvmBlock_CDD_HwTq4Meas_HwTq4Sca_MirrorBlock}
        {enable-take-address=true, indirect-api=false, port-defined-argument-value{value=PAdminProxy_Rte_NvmBlock_CDD_HwTq5Meas_HwTq5Sca_MirrorBlock_0:32, value-type=NvM_BlockIdType}, port=PAdminProxy_Rte_NvmBlock_CDD_HwTq5Meas_HwTq5Sca_MirrorBlock}
        {enable-take-address=false, indirect-api=false, port-defined-argument-value{value=PSProxy_Rte_NvmBlock_CDD_HwTq5Meas_HwTq5Sca_MirrorBlock_0:32, value-type=NvM_BlockIdType}, port=PSProxy_Rte_NvmBlock_CDD_HwTq5Meas_HwTq5Sca_MirrorBlock}
        {enable-take-address=true, indirect-api=false, port-defined-argument-value{value=PAdminProxy_Rte_NvmBlock_HwTqCorrln_HwTqChACmnModCmpLpFilSt_0:31, value-type=NvM_BlockIdType}, port=PAdminProxy_Rte_NvmBlock_HwTqCorrln_HwTqChACmnModCmpLpFilSt}
        {enable-take-address=false, indirect-api=false, port-defined-argument-value{value=PSProxy_Rte_NvmBlock_HwTqCorrln_HwTqChACmnModCmpLpFilSt_0:31, value-type=NvM_BlockIdType}, port=PSProxy_Rte_NvmBlock_HwTqCorrln_HwTqChACmnModCmpLpFilSt}
        {enable-take-address=true, indirect-api=false, port-defined-argument-value{value=PAdminProxy_Rte_NvmBlock_DutyCycThermProtn_FilStVal_0:30, value-type=NvM_BlockIdType}, port=PAdminProxy_Rte_NvmBlock_DutyCycThermProtn_FilStVal}
        {enable-take-address=false, indirect-api=false, port-defined-argument-value{value=PSProxy_Rte_NvmBlock_DutyCycThermProtn_FilStVal_0:30, value-type=NvM_BlockIdType}, port=PSProxy_Rte_NvmBlock_DutyCycThermProtn_FilStVal}
        {enable-take-address=true, indirect-api=false, port-defined-argument-value{value=PAdminProxy_Rte_NvmBlock_MotTqCmdSca_MotTqScaFac_0:29, value-type=NvM_BlockIdType}, port=PAdminProxy_Rte_NvmBlock_MotTqCmdSca_MotTqScaFac}
        {enable-take-address=false, indirect-api=false, port-defined-argument-value{value=PSProxy_Rte_NvmBlock_MotTqCmdSca_MotTqScaFac_0:29, value-type=NvM_BlockIdType}, port=PSProxy_Rte_NvmBlock_MotTqCmdSca_MotTqScaFac}
        {enable-take-address=true, indirect-api=false, port-defined-argument-value{value=PAdminProxy_Rte_NvmBlock_MotCtrlPrmEstimn_MotPrmNom_0:28, value-type=NvM_BlockIdType}, port=PAdminProxy_Rte_NvmBlock_MotCtrlPrmEstimn_MotPrmNom}
        {enable-take-address=false, indirect-api=false, port-defined-argument-value{value=PSProxy_Rte_NvmBlock_MotCtrlPrmEstimn_MotPrmNom_0:28, value-type=NvM_BlockIdType}, port=PSProxy_Rte_NvmBlock_MotCtrlPrmEstimn_MotPrmNom}
        {enable-take-address=true, indirect-api=false, port-defined-argument-value{value=PAdminProxy_Rte_NvmBlock_Vin_0:27, value-type=NvM_BlockIdType}, port=PAdminProxy_Rte_NvmBlock_Vin}
        {enable-take-address=false, indirect-api=false, port-defined-argument-value{value=PSProxy_Rte_NvmBlock_Vin_0:27, value-type=NvM_BlockIdType}, port=PSProxy_Rte_NvmBlock_Vin}
        {enable-take-address=true, indirect-api=false, port-defined-argument-value{value=PAdminProxy_Rte_NvmBlock_Omc_0:26, value-type=NvM_BlockIdType}, port=PAdminProxy_Rte_NvmBlock_Omc}
        {enable-take-address=false, indirect-api=false, port-defined-argument-value{value=PSProxy_Rte_NvmBlock_Omc_0:26, value-type=NvM_BlockIdType}, port=PSProxy_Rte_NvmBlock_Omc}
        {enable-take-address=true, indirect-api=false, port-defined-argument-value{value=PAdminProxy_NVM_BLOCK_BOOT_PROG_COUNTER_0:25, value-type=NvM_BlockIdType}, port=PAdminProxy_NVM_BLOCK_BOOT_PROG_COUNTER}
        {enable-take-address=false, indirect-api=false, port-defined-argument-value{value=PSProxy_NVM_BLOCK_BOOT_PROG_COUNTER_0:25, value-type=NvM_BlockIdType}, port=PSProxy_NVM_BLOCK_BOOT_PROG_COUNTER}
        {enable-take-address=true, indirect-api=false, port-defined-argument-value{value=PAdminProxy_NVM_BLOCK_BOOT_PROG_DATA_0:24, value-type=NvM_BlockIdType}, port=PAdminProxy_NVM_BLOCK_BOOT_PROG_DATA}
        {enable-take-address=false, indirect-api=false, port-defined-argument-value{value=PSProxy_NVM_BLOCK_BOOT_PROG_DATA_0:24, value-type=NvM_BlockIdType}, port=PSProxy_NVM_BLOCK_BOOT_PROG_DATA}
        {enable-take-address=true, indirect-api=false, port-defined-argument-value{value=PAdminProxy_NVM_BLOCK_BOOT_SVK_HISTORY_0:23, value-type=NvM_BlockIdType}, port=PAdminProxy_NVM_BLOCK_BOOT_SVK_HISTORY}
        {enable-take-address=false, indirect-api=false, port-defined-argument-value{value=PSProxy_NVM_BLOCK_BOOT_SVK_HISTORY_0:23, value-type=NvM_BlockIdType}, port=PSProxy_NVM_BLOCK_BOOT_SVK_HISTORY}
        {enable-take-address=true, indirect-api=false, port-defined-argument-value{value=PAdminProxy_NVM_BLOCK_DLOG_SVK_SYS_SUPP_0:22, value-type=NvM_BlockIdType}, port=PAdminProxy_NVM_BLOCK_DLOG_SVK_SYS_SUPP}
        {enable-take-address=false, indirect-api=false, port-defined-argument-value{value=PSProxy_NVM_BLOCK_DLOG_SVK_SYS_SUPP_0:22, value-type=NvM_BlockIdType}, port=PSProxy_NVM_BLOCK_DLOG_SVK_SYS_SUPP}
        {enable-take-address=true, indirect-api=false, port-defined-argument-value{value=PAdminProxy_NVM_BLOCK_DLOG_SVK_PLANT_0:21, value-type=NvM_BlockIdType}, port=PAdminProxy_NVM_BLOCK_DLOG_SVK_PLANT}
        {enable-take-address=false, indirect-api=false, port-defined-argument-value{value=PSProxy_NVM_BLOCK_DLOG_SVK_PLANT_0:21, value-type=NvM_BlockIdType}, port=PSProxy_NVM_BLOCK_DLOG_SVK_PLANT}
        {enable-take-address=true, indirect-api=false, port-defined-argument-value{value=PAdminProxy_Rte_NvmBlock_Darh_ErrorQueue_0:20, value-type=NvM_BlockIdType}, port=PAdminProxy_Rte_NvmBlock_Darh_ErrorQueue}
        {enable-take-address=false, indirect-api=false, port-defined-argument-value{value=PSProxy_Rte_NvmBlock_Darh_ErrorQueue_0:20, value-type=NvM_BlockIdType}, port=PSProxy_Rte_NvmBlock_Darh_ErrorQueue}
        {enable-take-address=true, indirect-api=false, port-defined-argument-value{value=PAdminProxy_Rte_NvmBlock_CDD_VrfyCritReg_MCalReadVrfyCritRegFltInfo_0:17, value-type=NvM_BlockIdType}, port=PAdminProxy_Rte_NvmBlock_CDD_VrfyCritReg_MCalReadVrfyCritRegFltInfo}
        {enable-take-address=false, indirect-api=false, port-defined-argument-value{value=PSProxy_Rte_NvmBlock_CDD_VrfyCritReg_MCalReadVrfyCritRegFltInfo_0:17, value-type=NvM_BlockIdType}, port=PSProxy_Rte_NvmBlock_CDD_VrfyCritReg_MCalReadVrfyCritRegFltInfo}
        {enable-take-address=true, indirect-api=false, port-defined-argument-value{value=PAdminProxy_Rte_NvmBlock_BmwHwAgArbnAndEotPosn_BmwVehCentrOffs_0:16, value-type=NvM_BlockIdType}, port=PAdminProxy_Rte_NvmBlock_BmwHwAgArbnAndEotPosn_BmwVehCentrOffs}
        {enable-take-address=false, indirect-api=false, port-defined-argument-value{value=PSProxy_Rte_NvmBlock_BmwHwAgArbnAndEotPosn_BmwVehCentrOffs_0:16, value-type=NvM_BlockIdType}, port=PSProxy_Rte_NvmBlock_BmwHwAgArbnAndEotPosn_BmwVehCentrOffs}
        {enable-take-address=true, indirect-api=false, port-defined-argument-value{value=PAdminProxy_Rte_NvmBlock_LrndRackCentr_LrndRackCentr_0:15, value-type=NvM_BlockIdType}, port=PAdminProxy_Rte_NvmBlock_LrndRackCentr_LrndRackCentr}
        {enable-take-address=false, indirect-api=false, port-defined-argument-value{value=PSProxy_Rte_NvmBlock_LrndRackCentr_LrndRackCentr_0:15, value-type=NvM_BlockIdType}, port=PSProxy_Rte_NvmBlock_LrndRackCentr_LrndRackCentr}
        {enable-take-address=true, indirect-api=false, port-defined-argument-value{value=PAdminProxy_Rte_NvmBlock_ExcpnHndlg_McuDiagcData_0:14, value-type=NvM_BlockIdType}, port=PAdminProxy_Rte_NvmBlock_ExcpnHndlg_McuDiagcData}
        {enable-take-address=false, indirect-api=false, port-defined-argument-value{value=PSProxy_Rte_NvmBlock_ExcpnHndlg_McuDiagcData_0:14, value-type=NvM_BlockIdType}, port=PSProxy_Rte_NvmBlock_ExcpnHndlg_McuDiagcData}
        {enable-take-address=true, indirect-api=false, port-defined-argument-value{value=PAdminProxy_Rte_NvmBlock_TEstimn_TFilStVal_0:13, value-type=NvM_BlockIdType}, port=PAdminProxy_Rte_NvmBlock_TEstimn_TFilStVal}
        {enable-take-address=false, indirect-api=false, port-defined-argument-value{value=PSProxy_Rte_NvmBlock_TEstimn_TFilStVal_0:13, value-type=NvM_BlockIdType}, port=PSProxy_Rte_NvmBlock_TEstimn_TFilStVal}
        {enable-take-address=true, indirect-api=false, port-defined-argument-value{value=PAdminProxy_NVM_BLOCK_DLOG_SVK_ENTRY_0:12, value-type=NvM_BlockIdType}, port=PAdminProxy_NVM_BLOCK_DLOG_SVK_ENTRY}
        {enable-take-address=false, indirect-api=false, port-defined-argument-value{value=PSProxy_NVM_BLOCK_DLOG_SVK_ENTRY_0:12, value-type=NvM_BlockIdType}, port=PSProxy_NVM_BLOCK_DLOG_SVK_ENTRY}
        {enable-take-address=true, indirect-api=false, port-defined-argument-value{value=PAdminProxy_Rte_NvmBlock_Darh_DiagnoseMasterEnable_0:11, value-type=NvM_BlockIdType}, port=PAdminProxy_Rte_NvmBlock_Darh_DiagnoseMasterEnable}
        {enable-take-address=false, indirect-api=false, port-defined-argument-value{value=PSProxy_Rte_NvmBlock_Darh_DiagnoseMasterEnable_0:11, value-type=NvM_BlockIdType}, port=PSProxy_Rte_NvmBlock_Darh_DiagnoseMasterEnable}
        {enable-take-address=true, indirect-api=false, port-defined-argument-value{value=PAdminProxy_Rte_NvmBlock_Coding_CodingData_0:10, value-type=NvM_BlockIdType}, port=PAdminProxy_Rte_NvmBlock_Coding_CodingData}
        {enable-take-address=false, indirect-api=false, port-defined-argument-value{value=PSProxy_Rte_NvmBlock_Coding_CodingData_0:10, value-type=NvM_BlockIdType}, port=PSProxy_Rte_NvmBlock_Coding_CodingData}
        {enable-take-address=true, indirect-api=false, port-defined-argument-value{value=PAdminProxy_Rte_NvmBlock_BmwTunSetHndlr_BmwDesIninIdx_0:9, value-type=NvM_BlockIdType}, port=PAdminProxy_Rte_NvmBlock_BmwTunSetHndlr_BmwDesIninIdx}
        {enable-take-address=false, indirect-api=false, port-defined-argument-value{value=PSProxy_Rte_NvmBlock_BmwTunSetHndlr_BmwDesIninIdx_0:9, value-type=NvM_BlockIdType}, port=PSProxy_Rte_NvmBlock_BmwTunSetHndlr_BmwDesIninIdx}
        {enable-take-address=true, indirect-api=false, port-defined-argument-value{value=PAdminProxy_Rte_NvmBlock_BmwTunSetHndlr_NvmBmwDesIninOptSetAIdx_0:8, value-type=NvM_BlockIdType}, port=PAdminProxy_Rte_NvmBlock_BmwTunSetHndlr_NvmBmwDesIninOptSetAIdx}
        {enable-take-address=false, indirect-api=false, port-defined-argument-value{value=PSProxy_Rte_NvmBlock_BmwTunSetHndlr_NvmBmwDesIninOptSetAIdx_0:8, value-type=NvM_BlockIdType}, port=PSProxy_Rte_NvmBlock_BmwTunSetHndlr_NvmBmwDesIninOptSetAIdx}
        {enable-take-address=true, indirect-api=false, port-defined-argument-value{value=PAdminProxy_Rte_NvmBlock_BmwDiagcSrvHndlg_MilesKmEeprom_0:7, value-type=NvM_BlockIdType}, port=PAdminProxy_Rte_NvmBlock_BmwDiagcSrvHndlg_MilesKmEeprom}
        {enable-take-address=false, indirect-api=false, port-defined-argument-value{value=PSProxy_Rte_NvmBlock_BmwDiagcSrvHndlg_MilesKmEeprom_0:7, value-type=NvM_BlockIdType}, port=PSProxy_Rte_NvmBlock_BmwDiagcSrvHndlg_MilesKmEeprom}
        {enable-take-address=true, indirect-api=false, port-defined-argument-value{value=PAdminProxy_Rte_NvmBlock_BmwDiagcSrvHndlg_ProgCntr_0:6, value-type=NvM_BlockIdType}, port=PAdminProxy_Rte_NvmBlock_BmwDiagcSrvHndlg_ProgCntr}
        {enable-take-address=false, indirect-api=false, port-defined-argument-value{value=PSProxy_Rte_NvmBlock_BmwDiagcSrvHndlg_ProgCntr_0:6, value-type=NvM_BlockIdType}, port=PSProxy_Rte_NvmBlock_BmwDiagcSrvHndlg_ProgCntr}
        {enable-take-address=true, indirect-api=false, port-defined-argument-value{value=PAdminProxy_Rte_NvmBlock_BmwDiagcSrvHndlg_ProgCntrMaxVal_0:5, value-type=NvM_BlockIdType}, port=PAdminProxy_Rte_NvmBlock_BmwDiagcSrvHndlg_ProgCntrMaxVal}
        {enable-take-address=false, indirect-api=false, port-defined-argument-value{value=PSProxy_Rte_NvmBlock_BmwDiagcSrvHndlg_ProgCntrMaxVal_0:5, value-type=NvM_BlockIdType}, port=PSProxy_Rte_NvmBlock_BmwDiagcSrvHndlg_ProgCntrMaxVal}
        {enable-take-address=true, indirect-api=false, port-defined-argument-value{value=PAdminProxy_Rte_NvmBlock_BmwDiagcSrvHndlg_TestStamp_0:4, value-type=NvM_BlockIdType}, port=PAdminProxy_Rte_NvmBlock_BmwDiagcSrvHndlg_TestStamp}
        {enable-take-address=false, indirect-api=false, port-defined-argument-value{value=PSProxy_Rte_NvmBlock_BmwDiagcSrvHndlg_TestStamp_0:4, value-type=NvM_BlockIdType}, port=PSProxy_Rte_NvmBlock_BmwDiagcSrvHndlg_TestStamp}
        {enable-take-address=true, indirect-api=false, port-defined-argument-value{value=PAdminProxy_Rte_NvmBlock_PullCmpActv_PullCmpLongTerm_0:3, value-type=NvM_BlockIdType}, port=PAdminProxy_Rte_NvmBlock_PullCmpActv_PullCmpLongTerm}
        {enable-take-address=false, indirect-api=false, port-defined-argument-value{value=PSProxy_Rte_NvmBlock_PullCmpActv_PullCmpLongTerm_0:3, value-type=NvM_BlockIdType}, port=PSProxy_Rte_NvmBlock_PullCmpActv_PullCmpLongTerm}
      11 x runnable:
        NvMProxy_MainFunction
        EraseBlock: can-be-invoked-concurrently=true, symbol=NvMProxy_EraseNvBlock
        GetDataIndex: can-be-invoked-concurrently=true, symbol=NvMProxy_GetDataIndex
        GetErrorStatus: can-be-invoked-concurrently=true, symbol=NvMProxy_GetErrorStatus
        InvalidateNvBlock: can-be-invoked-concurrently=true, symbol=NvMProxy_InvalidateNvBlock
        ReadBlock: can-be-invoked-concurrently=true, symbol=NvMProxy_ReadBlock
        RestoreBlockDefaults: can-be-invoked-concurrently=true, symbol=NvMProxy_RestoreBlockDefaults
        SetBlockProtection: can-be-invoked-concurrently=true, symbol=NvMProxy_SetBlockProtection
        SetDataIndex: symbol=NvM_SetDataIndex
        SetRamBlockStatus: can-be-invoked-concurrently=true, symbol=NvMProxy_SetRamBlockStatus
        WriteBlock: can-be-invoked-concurrently=true, symbol=NvMProxy_WriteBlock
  swc implementation NvMProxyImplementation: behavior=NvMProxyInternalBehavior
    code-descriptors:
      code Default: artifact-descriptors=autosar-engineering-object={short-label=Default, category=SWSRC}
